AUTOSAR XML (schema 4-0-3)
package /MICROSAR/Dcm_swc
  5 x mode declaration group:
    DcmControlDtcSetting: initial-mode=ENABLEDTCSETTING, on-transition-value=2
      mode ENABLEDTCSETTING: value=0
      mode DISABLEDTCSETTING: value=1
    DcmEcuReset: initial-mode=NONE, on-transition-value=7
      7 x mode:
        NONE: value=0
        HARD: value=1
        KEYONOFF: value=2
        SOFT: value=3
        JUMPTOBOOTLOADER: value=4
        JUMPTOSYSSUPPLIERBOOTLOADER: value=5
        EXECUTE: value=6
    DcmModeRapidPowerShutDown: initial-mode=ENABLE_RAPIDPOWERSHUTDOWN, on-transition-value=2
      mode ENABLE_RAPIDPOWERSHUTDOWN: value=0
      mode DISABLE_RAPIDPOWERSHUTDOWN: value=1
    DcmDiagnosticSessionControl: initial-mode=DefaultSession, on-transition-value=255
      4 x mode:
        DefaultSession: value=1
        ProgrammingSession: value=2
        ExtendedSession: value=3
        SafetySystemSession: value=4
    DcmCommunicationControl: initial-mode=DCM_ENABLE_RX_TX_NORM, on-transition-value=12
      12 x mode:
        DCM_ENABLE_RX_TX_NORM: value=0
        DCM_ENABLE_RX_DISABLE_TX_NORM: value=1
        DCM_DISABLE_RX_ENABLE_TX_NORM: value=2
        DCM_DISABLE_RX_TX_NORMAL: value=3
        DCM_ENABLE_RX_TX_NM: value=4
        DCM_ENABLE_RX_DISABLE_TX_NM: value=5
        DCM_DISABLE_RX_ENABLE_TX_NM: value=6
        DCM_DISABLE_RX_TX_NM: value=7
        DCM_ENABLE_RX_TX_NORM_NM: value=8
        DCM_ENABLE_RX_DISABLE_TX_NORM_NM: value=9
        DCM_DISABLE_RX_ENABLE_TX_NORM_NM: value=10
        DCM_DISABLE_RX_TX_NORM_NM: value=11
  data type mapping set DcmMappingSet  # Contains mapping for ModeDeclarationGroups which are provided by Dcm.
    mode-request-type-maps:
      implementation-data-type=Dcm_ControlDtcSettingType, mode-group=DcmControlDtcSetting
      implementation-data-type=Dcm_EcuResetType, mode-group=DcmEcuReset
      implementation-data-type=Dcm_ModeRapidPowerShutDownType, mode-group=DcmModeRapidPowerShutDown
      implementation-data-type=Dcm_DiagnosticSessionControlType, mode-group=DcmDiagnosticSessionControl
      implementation-data-type=Dcm_CommunicationModeType, mode-group=DcmCommunicationControl
package /MICROSAR/Dcm_swc/DataTypes
  32 x impl type:
    Dcm_ConfirmationStatusType: compu {0=DCM_RES_POS_OK, 1=DCM_RES_POS_NOT_OK, 2=DCM_RES_NEG_OK, 3=DCM_RES_NEG_NOT_OK}, implementation-data-type=uint8
    Dcm_OpStatusType: compu {0=DCM_INITIAL, 1=DCM_PENDING, 2=DCM_CANCEL, 3=DCM_FORCE_RCRRP_OK, 64=DCM_FORCE_RCRRP_NOT_OK}, implementation-data-type=uint8
    Dcm_NegativeResponseCodeType: compu {0=DCM_E_POSITIVERESPONSE, 16=DCM_E_GENERALREJECT, 17=DCM_E_SERVICENOTSUPPORTED, 18=DCM_E_SUBFUNCTIONNOTSUPPORTED, 19=DCM_E_INCORRECTMESSAGELENGTHORINVALIDFORMAT, 20=DCM_E_RESPONSETOOLONG, 33=DCM_E_BUSYREPEATREQUEST, 34=DCM_E_CONDITIONSNOTCORRECT, 36=DCM_E_REQUESTSEQUENCEERROR, 37=DCM_E_NORESPONSEFROMSUBNETCOMPONENT, 38=DCM_E_FAILUREPREVENTSEXECUTIONOFREQUESTEDACTION, 49=DCM_E_REQUESTOUTOFRANGE, 51=DCM_E_SECURITYACCESSDENIED, 53=DCM_E_INVALIDKEY, 54=DCM_E_EXCEEDNUMBEROFATTEMPTS, 55=DCM_E_REQUIREDTIMEDELAYNOTEXPIRED, 112=DCM_E_UPLOADDOWNLOADNOTACCEPTED, 113=DCM_E_TRANSFERDATASUSPENDED, 114=DCM_E_GENERALPROGRAMMINGFAILURE, 115=DCM_E_WRONGBLOCKSEQUENCECOUNTER, 120=DCM_E_REQUESTCORRECTLYRECEIVEDRESPONSEPENDING, 126=DCM_E_SUBFUNCTIONNOTSUPPORTEDINACTIVESESSION, 127=DCM_E_SERVICENOTSUPPORTEDINACTIVESESSION, 129=DCM_E_RPMTOOHIGH, 130=DCM_E_RPMTOOLOW, 131=DCM_E_ENGINEISRUNNING, 132=DCM_E_ENGINEISNOTRUNNING, 133=DCM_E_ENGINERUNTIMETOOLOW, 134=DCM_E_TEMPERATURETOOHIGH, 135=DCM_E_TEMPERATURETOOLOW, 136=DCM_E_VEHICLESPEEDTOOHIGH, 137=DCM_E_VEHICLESPEEDTOOLOW, 138=DCM_E_THROTTLE_PEDALTOOHIGH, 139=DCM_E_THROTTLE_PEDALTOOLOW, 140=DCM_E_TRANSMISSIONRANGENOTINNEUTRAL, 141=DCM_E_TRANSMISSIONRANGENOTINGEAR, 143=DCM_E_BRAKESWITCH_NOTCLOSED, 144=DCM_E_SHIFTERLEVERNOTINPARK, 145=DCM_E_TORQUECONVERTERCLUTCHLOCKED, 146=DCM_E_VOLTAGETOOHIGH, 147=DCM_E_VOLTAGETOOLOW, 240..249=DCM_E_VMSCNC_0..DCM_E_VMSCNC_9, 250=DCM_E_VMSCNC_A, 251=DCM_E_VMSCNC_B, 252=DCM_E_VMSCNC_C, 253=DCM_E_VMSCNC_D, 254=DCM_E_VMSCNC_E}, implementation-data-type=uint8
    Dcm_ProtocolType: compu {0=DCM_OBD_ON_CAN, 1=DCM_OBD_ON_FLEXRAY, 2=DCM_OBD_ON_IP, 3=DCM_UDS_ON_CAN, 4=DCM_UDS_ON_FLEXRAY, 5=DCM_UDS_ON_IP, 12=DCM_NO_ACTIVE_PROTOCOL, 240..254=DCM_SUPPLIER_1..DCM_SUPPLIER_15}, implementation-data-type=uint8
    Dcm_SecLevelType: compu {0=DCM_SEC_LEV_LOCKED, 1=DCM_SEC_LEV_L1, 2=DCM_SEC_LEV_L2, 5=DCM_SEC_LEV_L5, 6=DCM_SEC_LEV_L6, 7=DCM_SEC_LEV_L7, 9=DCM_SEC_LEV_L9, 48=DCM_SEC_LEV_L48}, implementation-data-type=uint8
    Dcm_SesCtrlType: compu {1=DCM_DEFAULT_SESSION, 2=DCM_PROGRAMMING_SESSION, 3=DCM_EXTENDED_DIAGNOSTIC_SESSION, 4=DCM_SAFETY_SYSTEM_DIAGNOSTIC_SESSION}, implementation-data-type=uint8
    Dem_DTCFormatType: compu {0=DEM_DTC_FORMAT_OBD, 1=DEM_DTC_FORMAT_UDS}, implementation-data-type=uint8
    Dem_DTCKindType: compu {1=DEM_DTC_KIND_ALL_DTCS, 2=DEM_DTC_KIND_EMISSION_REL_DTCS}, implementation-data-type=uint8
    Dem_DTCGroupType: range raw 0..16777215, implementation-data-type=uint32
    Dem_DTCOriginType: compu {1=DEM_DTC_ORIGIN_PRIMARY_MEMORY, 2=DEM_DTC_ORIGIN_MIRROR_MEMORY, 3=DEM_DTC_ORIGIN_PERMANENT_MEMORY, 4=DEM_DTC_ORIGIN_SECONDARY_MEMORY}, implementation-data-type=uint8
    Dcm_ControlDtcSettingType: compu {0=DCM_ENUM_ENABLEDTCSETTING, 1=DCM_ENUM_DISABLEDTCSETTING}, implementation-data-type=uint8
    Dcm_EcuResetType: compu {0=DCM_ENUM_NONE, 1=DCM_ENUM_HARD, 2=DCM_ENUM_KEYONOFF, 3=DCM_ENUM_SOFT, 4=DCM_ENUM_JUMPTOBOOTLOADER, 5=DCM_ENUM_JUMPTOSYSSUPPLIERBOOTLOADER, 6=DCM_ENUM_EXECUTE}, implementation-data-type=uint8
    Dcm_ModeRapidPowerShutDownType: compu {0=DCM_ENUM_ENABLE_RAPIDPOWERSHUTDOWN, 1=DCM_ENUM_DISABLE_RAPIDPOWERSHUTDOWN}, implementation-data-type=uint8
    Dcm_DiagnosticSessionControlType: compu {1=DCM_ENUM_DefaultSession, 2=DCM_ENUM_ProgrammingSession, 3=DCM_ENUM_ExtendedSession, 4=DCM_ENUM_SafetySystemSession}, implementation-data-type=uint8
    Dcm_CommunicationModeType: compu {0=DCM_ENABLE_RX_TX_NORM, 1=DCM_ENABLE_RX_DISABLE_TX_NORM, 2=DCM_DISABLE_RX_ENABLE_TX_NORM, 3=DCM_DISABLE_RX_TX_NORMAL, 4=DCM_ENABLE_RX_TX_NM, 5=DCM_ENABLE_RX_DISABLE_TX_NM, 6=DCM_DISABLE_RX_ENABLE_TX_NM, 7=DCM_DISABLE_RX_TX_NM, 8=DCM_ENABLE_RX_TX_NORM_NM, 9=DCM_ENABLE_RX_DISABLE_TX_NORM_NM, 10=DCM_DISABLE_RX_ENABLE_TX_NORM_NM, 11=DCM_DISABLE_RX_TX_NORM_NM}, implementation-data-type=uint8
    Dcm_Data50ByteType: category=ARRAY, sw-calibration-access=READ-ONLY
      element Dcm_Data50ByteTypeElement: array-size=50, array-size-semantics=FIXED-SIZE, implementation-data-type=uint8
    Dcm_Data31ByteType: category=ARRAY, sw-calibration-access=READ-ONLY
      element Dcm_Data31ByteTypeElement: array-size=31, array-size-semantics=FIXED-SIZE, implementation-data-type=uint8
    Dcm_Data12ByteType: category=ARRAY, sw-calibration-access=READ-ONLY
      element Dcm_Data12ByteTypeElement: array-size=12, array-size-semantics=FIXED-SIZE, implementation-data-type=uint8
    Dcm_Data2ByteType: category=ARRAY, sw-calibration-access=READ-ONLY
      element Dcm_Data2ByteTypeElement: array-size=2, array-size-semantics=FIXED-SIZE, implementation-data-type=uint8
    Dcm_Data65ByteType: category=ARRAY, sw-calibration-access=READ-ONLY
      element Dcm_Data65ByteTypeElement: array-size=65, array-size-semantics=FIXED-SIZE, implementation-data-type=uint8
    Dcm_Data4ByteType: category=ARRAY, sw-calibration-access=READ-ONLY
      element Dcm_Data4ByteTypeElement: array-size=4, array-size-semantics=FIXED-SIZE, implementation-data-type=uint8
    Dcm_Data14ByteType: category=ARRAY, sw-calibration-access=READ-ONLY
      element Dcm_Data14ByteTypeElement: array-size=14, array-size-semantics=FIXED-SIZE, implementation-data-type=uint8
    Dcm_Data1ByteType: category=ARRAY, sw-calibration-access=READ-ONLY
      element Dcm_Data1ByteTypeElement: array-size=1, array-size-semantics=FIXED-SIZE, implementation-data-type=uint8
    Dcm_Data822ByteType: category=ARRAY, sw-calibration-access=READ-ONLY
      element Dcm_Data822ByteTypeElement: array-size=822, array-size-semantics=FIXED-SIZE, implementation-data-type=uint8
    Dcm_Data10ByteType: category=ARRAY, sw-calibration-access=READ-ONLY
      element Dcm_Data10ByteTypeElement: array-size=10, array-size-semantics=FIXED-SIZE, implementation-data-type=uint8
    Dcm_Data16ByteType: category=ARRAY, sw-calibration-access=READ-ONLY
      element Dcm_Data16ByteTypeElement: array-size=16, array-size-semantics=FIXED-SIZE, implementation-data-type=uint8
    Dcm_Data8ByteType: category=ARRAY, sw-calibration-access=READ-ONLY
      element Dcm_Data8ByteTypeElement: array-size=8, array-size-semantics=FIXED-SIZE, implementation-data-type=uint8
    Dcm_Data6ByteType: category=ARRAY, sw-calibration-access=READ-ONLY
      element Dcm_Data6ByteTypeElement: array-size=6, array-size-semantics=FIXED-SIZE, implementation-data-type=uint8
    Dcm_Data17ByteType: category=ARRAY, sw-calibration-access=READ-ONLY
      element Dcm_Data17ByteTypeElement: array-size=17, array-size-semantics=FIXED-SIZE, implementation-data-type=uint8
    Dcm_Data9ByteType: category=ARRAY, sw-calibration-access=READ-ONLY
      element Dcm_Data9ByteTypeElement: array-size=9, array-size-semantics=FIXED-SIZE, implementation-data-type=uint8
    Dcm_Data3ByteType: category=ARRAY, sw-calibration-access=READ-ONLY
      element Dcm_Data3ByteTypeElement: array-size=3, array-size-semantics=FIXED-SIZE, implementation-data-type=uint8
    Dcm_Data80ByteType: category=ARRAY, sw-calibration-access=READ-ONLY
      element Dcm_Data80ByteTypeElement: array-size=80, array-size-semantics=FIXED-SIZE, implementation-data-type=uint8
package /MICROSAR/Dcm_swc/Interfaces
  5 x mode switch interface, all with is-service=true, service-kind=DIAGNOSTIC-COMMUNICATION-MANAGER:
    DcmControlDtcSetting
      mode group DcmControlDtcSetting: type=DcmControlDtcSetting
    DcmEcuReset
      mode group DcmEcuReset: type=DcmEcuReset
    DcmModeRapidPowerShutDown
      mode group DcmModeRapidPowerShutDown: type=DcmModeRapidPowerShutDown
    DcmDiagnosticSessionControl
      mode group DcmDiagnosticSessionControl: type=DcmDiagnosticSessionControl
    DcmCommunicationControl_ComMConf_ComMChannel_CAN_5_Cluster_def1eb88
      mode group DcmCommunicationControl_ComMConf_ComMChannel_CAN_5_Cluster_def1eb88: type=DcmCommunicationControl
  117 x client server interface, all with is-service=true, service-kind=DIAGNOSTIC-COMMUNICATION-MANAGER:
    DCMServices
      4 x operation, all with possible-error=DCMServices/E_NOT_OK:
        GetActiveProtocol
          arg ActiveProtocol: type=Dcm_ProtocolType, direction=OUT
        GetSesCtrlType
          arg SesCtrlType: type=Dcm_SesCtrlType, direction=OUT
        ResetToDefaultSession
        GetSecurityLevel
          arg SecLevel: type=Dcm_SecLevelType, direction=OUT
      error E_NOT_OK: error-code=1
    ServiceRequestNotification
      operation Indication: possible-error=[ServiceRequestNotification/E_NOT_OK, E_REQUEST_NOT_ACCEPTED]
        6 x arg:
          SID: type=uint8, direction=IN
          RequestData: type=Dcm_Data50ByteType, direction=IN
          DataSize: type=uint16, direction=IN
          ReqType: type=uint8, direction=IN
          SourceAddress: type=uint16, direction=IN
          ErrorCode: type=Dcm_NegativeResponseCodeType, direction=OUT
      operation Confirmation: possible-error=ServiceRequestNotification/E_NOT_OK
        4 x arg, all with direction=IN:
          SID: type=uint8
          ReqType: type=uint8
          SourceAddress: type=uint16
          ConfirmationStatus: type=Dcm_ConfirmationStatusType
      error E_NOT_OK: error-code=1
      error E_REQUEST_NOT_ACCEPTED: error-code=8
    SecurityAccess_Level_1
      operation GetSeed: possible-error=[SecurityAccess_Level_1/E_NOT_OK, SecurityAccess_Level_1/E_PENDING]
        arg OpStatus: type=Dcm_OpStatusType, direction=IN
        arg Seed: type=Dcm_Data31ByteType, direction=OUT
        arg ErrorCode: type=Dcm_NegativeResponseCodeType, direction=OUT
      operation CompareKey: possible-error=[SecurityAccess_Level_1/E_NOT_OK, SecurityAccess_Level_1/E_PENDING, SecurityAccess_Level_1/E_COMPARE_KEY_FAILED]
        arg Key: type=Dcm_Data12ByteType, direction=IN
        arg OpStatus: type=Dcm_OpStatusType, direction=IN
      error E_NOT_OK: error-code=1
      error E_PENDING: error-code=10
      error E_COMPARE_KEY_FAILED: error-code=11
    SecurityAccess_Level_3
      operation GetSeed: possible-error=[SecurityAccess_Level_3/E_NOT_OK, SecurityAccess_Level_3/E_PENDING]
        arg OpStatus: type=Dcm_OpStatusType, direction=IN
        arg Seed: type=Dcm_Data31ByteType, direction=OUT
        arg ErrorCode: type=Dcm_NegativeResponseCodeType, direction=OUT
      operation CompareKey: possible-error=[SecurityAccess_Level_3/E_NOT_OK, SecurityAccess_Level_3/E_PENDING, SecurityAccess_Level_3/E_COMPARE_KEY_FAILED]
        arg Key: type=Dcm_Data12ByteType, direction=IN
        arg OpStatus: type=Dcm_OpStatusType, direction=IN
      error E_NOT_OK: error-code=1
      error E_PENDING: error-code=10
      error E_COMPARE_KEY_FAILED: error-code=11
    SecurityAccess_Level_9
      operation GetSeed: possible-error=[SecurityAccess_Level_9/E_NOT_OK, SecurityAccess_Level_9/E_PENDING]
        arg OpStatus: type=Dcm_OpStatusType, direction=IN
        arg Seed: type=Dcm_Data31ByteType, direction=OUT
        arg ErrorCode: type=Dcm_NegativeResponseCodeType, direction=OUT
      operation CompareKey: possible-error=[SecurityAccess_Level_9/E_NOT_OK, SecurityAccess_Level_9/E_PENDING, SecurityAccess_Level_9/E_COMPARE_KEY_FAILED]
        arg Key: type=Dcm_Data12ByteType, direction=IN
        arg OpStatus: type=Dcm_OpStatusType, direction=IN
      error E_NOT_OK: error-code=1
      error E_PENDING: error-code=10
      error E_COMPARE_KEY_FAILED: error-code=11
    SecurityAccess_Level_B
      operation GetSeed: possible-error=[SecurityAccess_Level_B/E_NOT_OK, SecurityAccess_Level_B/E_PENDING]
        arg OpStatus: type=Dcm_OpStatusType, direction=IN
        arg Seed: type=Dcm_Data31ByteType, direction=OUT
        arg ErrorCode: type=Dcm_NegativeResponseCodeType, direction=OUT
      operation CompareKey: possible-error=[SecurityAccess_Level_B/E_NOT_OK, SecurityAccess_Level_B/E_PENDING, SecurityAccess_Level_B/E_COMPARE_KEY_FAILED]
        arg Key: type=Dcm_Data12ByteType, direction=IN
        arg OpStatus: type=Dcm_OpStatusType, direction=IN
      error E_NOT_OK: error-code=1
      error E_PENDING: error-code=10
      error E_COMPARE_KEY_FAILED: error-code=11
    SecurityAccess_Level_D
      operation GetSeed: possible-error=[SecurityAccess_Level_D/E_NOT_OK, SecurityAccess_Level_D/E_PENDING]
        arg OpStatus: type=Dcm_OpStatusType, direction=IN
        arg Seed: type=Dcm_Data31ByteType, direction=OUT
        arg ErrorCode: type=Dcm_NegativeResponseCodeType, direction=OUT
      operation CompareKey: possible-error=[SecurityAccess_Level_D/E_NOT_OK, SecurityAccess_Level_D/E_PENDING, SecurityAccess_Level_D/E_COMPARE_KEY_FAILED]
        arg Key: type=Dcm_Data12ByteType, direction=IN
        arg OpStatus: type=Dcm_OpStatusType, direction=IN
      error E_NOT_OK: error-code=1
      error E_PENDING: error-code=10
      error E_COMPARE_KEY_FAILED: error-code=11
    SecurityAccess_Level_11
      operation GetSeed: possible-error=[SecurityAccess_Level_11/E_NOT_OK, SecurityAccess_Level_11/E_PENDING]
        arg OpStatus: type=Dcm_OpStatusType, direction=IN
        arg Seed: type=Dcm_Data31ByteType, direction=OUT
        arg ErrorCode: type=Dcm_NegativeResponseCodeType, direction=OUT
      operation CompareKey: possible-error=[SecurityAccess_Level_11/E_NOT_OK, SecurityAccess_Level_11/E_PENDING, SecurityAccess_Level_11/E_COMPARE_KEY_FAILED]
        arg Key: type=Dcm_Data12ByteType, direction=IN
        arg OpStatus: type=Dcm_OpStatusType, direction=IN
      error E_NOT_OK: error-code=1
      error E_PENDING: error-code=10
      error E_COMPARE_KEY_FAILED: error-code=11
    SecurityAccess_Level_5F
      operation GetSeed: possible-error=[SecurityAccess_Level_5F/E_NOT_OK, SecurityAccess_Level_5F/E_PENDING]
        arg OpStatus: type=Dcm_OpStatusType, direction=IN
        arg Seed: type=Dcm_Data2ByteType, direction=OUT
        arg ErrorCode: type=Dcm_NegativeResponseCodeType, direction=OUT
      operation CompareKey: possible-error=[SecurityAccess_Level_5F/E_NOT_OK, SecurityAccess_Level_5F/E_PENDING, SecurityAccess_Level_5F/E_COMPARE_KEY_FAILED]
        arg Key: type=Dcm_Data2ByteType, direction=IN
        arg OpStatus: type=Dcm_OpStatusType, direction=IN
      error E_NOT_OK: error-code=1
      error E_PENDING: error-code=10
      error E_COMPARE_KEY_FAILED: error-code=11
    RoutineServices_RID_0200_ProvisionSecurityPeripheralGeneralKeys
      operation Start: possible-error=[RoutineServices_RID_0200_ProvisionSecurityPeripheralGeneralKeys/E_NOT_OK, RoutineServices_RID_0200_ProvisionSecurityPeripheralGeneralKeys/E_PENDING, RoutineServices_RID_0200_ProvisionSecurityPeripheralGeneralKeys/E_FORCE_RCRRP]
        4 x arg:
          ControlOptionStart: type=Dcm_Data65ByteType, direction=IN
          OpStatus: type=Dcm_OpStatusType, direction=IN
          RoutineStatusStart: type=uint8, direction=OUT
          ErrorCode: type=Dcm_NegativeResponseCodeType, direction=OUT
      error E_NOT_OK: error-code=1
      error E_PENDING: error-code=10
      error E_FORCE_RCRRP: error-code=12
    RoutineServices_RID_0204_ECUKeyProvisionData
      operation Start: possible-error=[RoutineServices_RID_0204_ECUKeyProvisionData/E_NOT_OK, RoutineServices_RID_0204_ECUKeyProvisionData/E_PENDING, RoutineServices_RID_0204_ECUKeyProvisionData/E_FORCE_RCRRP]
        arg OpStatus: type=Dcm_OpStatusType, direction=IN
        arg RoutineStatusStart: type=uint8, direction=OUT
        arg ErrorCode: type=Dcm_NegativeResponseCodeType, direction=OUT
      error E_NOT_OK: error-code=1
      error E_PENDING: error-code=10
      error E_FORCE_RCRRP: error-code=12
    RoutineServices_RID_0205_SecuredECUKeyProvisionData
      operation Start: possible-error=[RoutineServices_RID_0205_SecuredECUKeyProvisionData/E_NOT_OK, RoutineServices_RID_0205_SecuredECUKeyProvisionData/E_PENDING, RoutineServices_RID_0205_SecuredECUKeyProvisionData/E_FORCE_RCRRP]
        arg OpStatus: type=Dcm_OpStatusType, direction=IN
        arg RoutineStatusStart: type=uint8, direction=OUT
        arg ErrorCode: type=Dcm_NegativeResponseCodeType, direction=OUT
      error E_NOT_OK: error-code=1
      error E_PENDING: error-code=10
      error E_FORCE_RCRRP: error-code=12
    RoutineServices_RID_0209_UpdateProgrammedStateIndicatorForPartition
      operation Start: possible-error=[RoutineServices_RID_0209_UpdateProgrammedStateIndicatorForPartition/E_NOT_OK, RoutineServices_RID_0209_UpdateProgrammedStateIndicatorForPartition/E_PENDING, RoutineServices_RID_0209_UpdateProgrammedStateIndicatorForPartition/E_FORCE_RCRRP]
        arg ControlOptionStart: type=uint8, direction=IN
        arg OpStatus: type=Dcm_OpStatusType, direction=IN
        arg ErrorCode: type=Dcm_NegativeResponseCodeType, direction=OUT
      error E_NOT_OK: error-code=1
      error E_PENDING: error-code=10
      error E_FORCE_RCRRP: error-code=12
    RoutineServices_RID_021E_DiagInitiateExtendedReflash
      operation Start: possible-error=[RoutineServices_RID_021E_DiagInitiateExtendedReflash/E_NOT_OK, RoutineServices_RID_021E_DiagInitiateExtendedReflash/E_PENDING, RoutineServices_RID_021E_DiagInitiateExtendedReflash/E_FORCE_RCRRP]
        arg OpStatus: type=Dcm_OpStatusType, direction=IN
        arg RoutineStatusStart: type=uint8, direction=OUT
        arg ErrorCode: type=Dcm_NegativeResponseCodeType, direction=OUT
      error E_NOT_OK: error-code=1
      error E_PENDING: error-code=10
      error E_FORCE_RCRRP: error-code=12
    RoutineServices_RID_FF00_EraseMemory
      operation Start: possible-error=[RoutineServices_RID_FF00_EraseMemory/E_NOT_OK, RoutineServices_RID_FF00_EraseMemory/E_PENDING, RoutineServices_RID_FF00_EraseMemory/E_FORCE_RCRRP]
        arg ControlOptionStart: type=uint8, direction=IN
        arg OpStatus: type=Dcm_OpStatusType, direction=IN
        arg ErrorCode: type=Dcm_NegativeResponseCodeType, direction=OUT
      error E_NOT_OK: error-code=1
      error E_PENDING: error-code=10
      error E_FORCE_RCRRP: error-code=12
    DataServices_DID_F0F2_BootInitializationStatus_BootInitializationStatus_0_0
      operation ReadData: possible-error=[DataServices_DID_F0F2_BootInitializationStatus_BootInitializationStatus_0_0/E_NOT_OK, DataServices_DID_F0F2_BootInitializationStatus_BootInitializationStatus_0_0/E_PENDING]
        arg OpStatus: type=Dcm_OpStatusType, direction=IN
        arg Data: type=Dcm_Data2ByteType, direction=OUT
      error E_NOT_OK: error-code=1
      error E_PENDING: error-code=10
    DataServices_DID_F1DA_GMSoftwareModuleIdentifierAlphaCode_10_GMSoftwareModuleIdentifierAlphaCode_10_0_0
      operation ReadData: possible-error=[DataServices_DID_F1DA_GMSoftwareModuleIdentifierAlphaCode_10_GMSoftwareModuleIdentifierAlphaCode_10_0_0/E_NOT_OK, DataServices_DID_F1DA_GMSoftwareModuleIdentifierAlphaCode_10_GMSoftwareModuleIdentifierAlphaCode_10_0_0/E_PENDING]
        arg OpStatus: type=Dcm_OpStatusType, direction=IN
        arg Data: type=Dcm_Data2ByteType, direction=OUT
      error E_NOT_OK: error-code=1
      error E_PENDING: error-code=10
    DataServices_DID_F112_GMSoftwareModuleIdentifier_20_GMSoftwareModuleIdentifier_20_0_0
      operation ReadData: possible-error=[DataServices_DID_F112_GMSoftwareModuleIdentifier_20_GMSoftwareModuleIdentifier_20_0_0/E_NOT_OK, DataServices_DID_F112_GMSoftwareModuleIdentifier_20_GMSoftwareModuleIdentifier_20_0_0/E_PENDING]
        arg OpStatus: type=Dcm_OpStatusType, direction=IN
        arg Data: type=Dcm_Data4ByteType, direction=OUT
      error E_NOT_OK: error-code=1
      error E_PENDING: error-code=10
    DataServices_DID_F11C_GMSoftwareModuleIdentifier_25_GMSoftwareModuleIdentifier_25_0_0
      operation ReadData: possible-error=[DataServices_DID_F11C_GMSoftwareModuleIdentifier_25_GMSoftwareModuleIdentifier_25_0_0/E_NOT_OK, DataServices_DID_F11C_GMSoftwareModuleIdentifier_25_GMSoftwareModuleIdentifier_25_0_0/E_PENDING]
        arg OpStatus: type=Dcm_OpStatusType, direction=IN
        arg Data: type=Dcm_Data4ByteType, direction=OUT
      error E_NOT_OK: error-code=1
      error E_PENDING: error-code=10
    DataServices_DID_F10F_GMSoftwareModuleIdentifierAlphaCode_18_GMSoftwareModuleIdentifierAlphaCode_18_0_0
      operation ReadData: possible-error=[DataServices_DID_F10F_GMSoftwareModuleIdentifierAlphaCode_18_GMSoftwareModuleIdentifierAlphaCode_18_0_0/E_NOT_OK, DataServices_DID_F10F_GMSoftwareModuleIdentifierAlphaCode_18_GMSoftwareModuleIdentifierAlphaCode_18_0_0/E_PENDING]
        arg OpStatus: type=Dcm_OpStatusType, direction=IN
        arg Data: type=Dcm_Data2ByteType, direction=OUT
      error E_NOT_OK: error-code=1
      error E_PENDING: error-code=10
    DataServices_DID_F100_GMSoftwareModuleIdentifier_11_GMSoftwareModuleIdentifier_11_0_0
      operation ReadData: possible-error=[DataServices_DID_F100_GMSoftwareModuleIdentifier_11_GMSoftwareModuleIdentifier_11_0_0/E_NOT_OK, DataServices_DID_F100_GMSoftwareModuleIdentifier_11_GMSoftwareModuleIdentifier_11_0_0/E_PENDING]
        arg OpStatus: type=Dcm_OpStatusType, direction=IN
        arg Data: type=Dcm_Data4ByteType, direction=OUT
      error E_NOT_OK: error-code=1
      error E_PENDING: error-code=10
    DataServices_DID_F1CC_GMBaseModelPartNumber_GMBaseModelPartNumber_0_0
      operation ReadData: possible-error=[DataServices_DID_F1CC_GMBaseModelPartNumber_GMBaseModelPartNumber_0_0/E_NOT_OK, DataServices_DID_F1CC_GMBaseModelPartNumber_GMBaseModelPartNumber_0_0/E_PENDING]
        arg OpStatus: type=Dcm_OpStatusType, direction=IN
        arg Data: type=Dcm_Data4ByteType, direction=OUT
      error E_NOT_OK: error-code=1
      error E_PENDING: error-code=10
    DataServices_DID_F09B_GMXmlConfigurationCompatibilityIdentifier_DiagXmlConfigurationCompatibilityIdentifier_0_0
      operation ReadData: possible-error=[DataServices_DID_F09B_GMXmlConfigurationCompatibilityIdentifier_DiagXmlConfigurationCompatibilityIdentifier_0_0/E_NOT_OK, DataServices_DID_F09B_GMXmlConfigurationCompatibilityIdentifier_DiagXmlConfigurationCompatibilityIdentifier_0_0/E_PENDING]
        arg OpStatus: type=Dcm_OpStatusType, direction=IN
        arg Data: type=Dcm_Data2ByteType, direction=OUT
      error E_NOT_OK: error-code=1
      error E_PENDING: error-code=10
    DataServices_DID_F102_GMSoftwareModuleIdentifier_12_GMSoftwareModuleIdentifier_12_0_0
      operation ReadData: possible-error=[DataServices_DID_F102_GMSoftwareModuleIdentifier_12_GMSoftwareModuleIdentifier_12_0_0/E_NOT_OK, DataServices_DID_F102_GMSoftwareModuleIdentifier_12_GMSoftwareModuleIdentifier_12_0_0/E_PENDING]
        arg OpStatus: type=Dcm_OpStatusType, direction=IN
        arg Data: type=Dcm_Data4ByteType, direction=OUT
      error E_NOT_OK: error-code=1
      error E_PENDING: error-code=10
    DataServices_DID_F1C3_GMSoftwareModuleIdentifier_03_GMSoftwareModuleIdentifier_03_0_0
      operation ReadData: possible-error=[DataServices_DID_F1C3_GMSoftwareModuleIdentifier_03_GMSoftwareModuleIdentifier_03_0_0/E_NOT_OK, DataServices_DID_F1C3_GMSoftwareModuleIdentifier_03_GMSoftwareModuleIdentifier_03_0_0/E_PENDING]
        arg OpStatus: type=Dcm_OpStatusType, direction=IN
        arg Data: type=Dcm_Data4ByteType, direction=OUT
      error E_NOT_OK: error-code=1
      error E_PENDING: error-code=10
    DataServices_DID_F0AB_CompressedVehiclePartitioningAndProductStructure_DiagCompressedVehiclePartitioningAndProductStructure_0_0
      operation ReadData: possible-error=[DataServices_DID_F0AB_CompressedVehiclePartitioningAndProductStructure_DiagCompressedVehiclePartitioningAndProductStructure_0_0/E_NOT_OK, DataServices_DID_F0AB_CompressedVehiclePartitioningAndProductStructure_DiagCompressedVehiclePartitioningAndProductStructure_0_0/E_PENDING]
        arg OpStatus: type=Dcm_OpStatusType, direction=IN
        arg Data: type=Dcm_Data14ByteType, direction=OUT
      error E_NOT_OK: error-code=1
      error E_PENDING: error-code=10
    DataServices_DID_F10A_GMSoftwareModuleIdentifier_16_GMSoftwareModuleIdentifier_16_0_0
      operation ReadData: possible-error=[DataServices_DID_F10A_GMSoftwareModuleIdentifier_16_GMSoftwareModuleIdentifier_16_0_0/E_NOT_OK, DataServices_DID_F10A_GMSoftwareModuleIdentifier_16_GMSoftwareModuleIdentifier_16_0_0/E_PENDING]
        arg OpStatus: type=Dcm_OpStatusType, direction=IN
        arg Data: type=Dcm_Data4ByteType, direction=OUT
      error E_NOT_OK: error-code=1
      error E_PENDING: error-code=10
    DataServices_DID_F116_GMSoftwareModuleIdentifier_22_GMSoftwareModuleIdentifier_22_0_0
      operation ReadData: possible-error=[DataServices_DID_F116_GMSoftwareModuleIdentifier_22_GMSoftwareModuleIdentifier_22_0_0/E_NOT_OK, DataServices_DID_F116_GMSoftwareModuleIdentifier_22_GMSoftwareModuleIdentifier_22_0_0/E_PENDING]
        arg OpStatus: type=Dcm_OpStatusType, direction=IN
        arg Data: type=Dcm_Data4ByteType, direction=OUT
      error E_NOT_OK: error-code=1
      error E_PENDING: error-code=10
    DataServices_DID_F1C1_GMSoftwareModuleIdentifier_01_GMSoftwareModuleIdentifier_01_0_0
      operation ReadData: possible-error=[DataServices_DID_F1C1_GMSoftwareModuleIdentifier_01_GMSoftwareModuleIdentifier_01_0_0/E_NOT_OK, DataServices_DID_F1C1_GMSoftwareModuleIdentifier_01_GMSoftwareModuleIdentifier_01_0_0/E_PENDING]
        arg OpStatus: type=Dcm_OpStatusType, direction=IN
        arg Data: type=Dcm_Data4ByteType, direction=OUT
      error E_NOT_OK: error-code=1
      error E_PENDING: error-code=10
    DataServices_DID_F1D4_GMSoftwareModuleIdentifierAlphaCode_04_GMSoftwareModuleIdentifierAlphaCode_04_0_0
      operation ReadData: possible-error=[DataServices_DID_F1D4_GMSoftwareModuleIdentifierAlphaCode_04_GMSoftwareModuleIdentifierAlphaCode_04_0_0/E_NOT_OK, DataServices_DID_F1D4_GMSoftwareModuleIdentifierAlphaCode_04_GMSoftwareModuleIdentifierAlphaCode_04_0_0/E_PENDING]
        arg OpStatus: type=Dcm_OpStatusType, direction=IN
        arg Data: type=Dcm_Data2ByteType, direction=OUT
      error E_NOT_OK: error-code=1
      error E_PENDING: error-code=10
    DataServices_DID_F1D6_GMSoftwareModuleIdentifierAlphaCode_06_GMSoftwareModuleIdentifierAlphaCode_06_0_0
      operation ReadData: possible-error=[DataServices_DID_F1D6_GMSoftwareModuleIdentifierAlphaCode_06_GMSoftwareModuleIdentifierAlphaCode_06_0_0/E_NOT_OK, DataServices_DID_F1D6_GMSoftwareModuleIdentifierAlphaCode_06_GMSoftwareModuleIdentifierAlphaCode_06_0_0/E_PENDING]
        arg OpStatus: type=Dcm_OpStatusType, direction=IN
        arg Data: type=Dcm_Data2ByteType, direction=OUT
      error E_NOT_OK: error-code=1
      error E_PENDING: error-code=10
    DataServices_DID_F122_GMSoftwareModuleIdentifier_28_GMSoftwareModuleIdentifier_28_0_0
      operation ReadData: possible-error=[DataServices_DID_F122_GMSoftwareModuleIdentifier_28_GMSoftwareModuleIdentifier_28_0_0/E_NOT_OK, DataServices_DID_F122_GMSoftwareModuleIdentifier_28_GMSoftwareModuleIdentifier_28_0_0/E_PENDING]
        arg OpStatus: type=Dcm_OpStatusType, direction=IN
        arg Data: type=Dcm_Data4ByteType, direction=OUT
      error E_NOT_OK: error-code=1
      error E_PENDING: error-code=10
    DataServices_DID_F104_GMSoftwareModuleIdentifier_13_GMSoftwareModuleIdentifier_13_0_0
      operation ReadData: possible-error=[DataServices_DID_F104_GMSoftwareModuleIdentifier_13_GMSoftwareModuleIdentifier_13_0_0/E_NOT_OK, DataServices_DID_F104_GMSoftwareModuleIdentifier_13_GMSoftwareModuleIdentifier_13_0_0/E_PENDING]
        arg OpStatus: type=Dcm_OpStatusType, direction=IN
        arg Data: type=Dcm_Data4ByteType, direction=OUT
      error E_NOT_OK: error-code=1
      error E_PENDING: error-code=10
    DataServices_DID_F10C_GMSoftwareModuleIdentifier_17_GMSoftwareModuleIdentifier_17_0_0
      operation ReadData: possible-error=[DataServices_DID_F10C_GMSoftwareModuleIdentifier_17_GMSoftwareModuleIdentifier_17_0_0/E_NOT_OK, DataServices_DID_F10C_GMSoftwareModuleIdentifier_17_GMSoftwareModuleIdentifier_17_0_0/E_PENDING]
        arg OpStatus: type=Dcm_OpStatusType, direction=IN
        arg Data: type=Dcm_Data4ByteType, direction=OUT
      error E_NOT_OK: error-code=1
      error E_PENDING: error-code=10
    DataServices_DID_F1A0_ManufacturersEnableCounter_ManufacturersEnableCounter_0_0
      operation ReadData: possible-error=[DataServices_DID_F1A0_ManufacturersEnableCounter_ManufacturersEnableCounter_0_0/E_NOT_OK, DataServices_DID_F1A0_ManufacturersEnableCounter_ManufacturersEnableCounter_0_0/E_PENDING]
        arg OpStatus: type=Dcm_OpStatusType, direction=IN
        arg Data: type=Dcm_Data1ByteType, direction=OUT
      operation WriteData: possible-error=[DataServices_DID_F1A0_ManufacturersEnableCounter_ManufacturersEnableCounter_0_0/E_NOT_OK, DataServices_DID_F1A0_ManufacturersEnableCounter_ManufacturersEnableCounter_0_0/E_PENDING]
        arg Data: type=Dcm_Data1ByteType, direction=IN
        arg OpStatus: type=Dcm_OpStatusType, direction=IN
        arg ErrorCode: type=Dcm_NegativeResponseCodeType, direction=OUT
      error E_NOT_OK: error-code=1
      error E_PENDING: error-code=10
    DataServices_DID_F103_GMSoftwareModuleIdentifierAlphaCode_12_GMSoftwareModuleIdentifierAlphaCode_12_0_0
      operation ReadData: possible-error=[DataServices_DID_F103_GMSoftwareModuleIdentifierAlphaCode_12_GMSoftwareModuleIdentifierAlphaCode_12_0_0/E_NOT_OK, DataServices_DID_F103_GMSoftwareModuleIdentifierAlphaCode_12_GMSoftwareModuleIdentifierAlphaCode_12_0_0/E_PENDING]
        arg OpStatus: type=Dcm_OpStatusType, direction=IN
        arg Data: type=Dcm_Data2ByteType, direction=OUT
      error E_NOT_OK: error-code=1
      error E_PENDING: error-code=10
    DataServices_DID_F0F0_ProgrammedStateIndicator_ProgrammedStateIndicator_0_0
      operation ReadData: possible-error=[DataServices_DID_F0F0_ProgrammedStateIndicator_ProgrammedStateIndicator_0_0/E_NOT_OK, DataServices_DID_F0F0_ProgrammedStateIndicator_ProgrammedStateIndicator_0_0/E_PENDING]
        arg OpStatus: type=Dcm_OpStatusType, direction=IN
        arg Data: type=Dcm_Data1ByteType, direction=OUT
      operation ReadDataLength: possible-error=[DataServices_DID_F0F0_ProgrammedStateIndicator_ProgrammedStateIndicator_0_0/E_NOT_OK, DataServices_DID_F0F0_ProgrammedStateIndicator_ProgrammedStateIndicator_0_0/E_PENDING]
        arg OpStatus: type=Dcm_OpStatusType, direction=IN
        arg DataLength: type=uint16, direction=OUT
      error E_NOT_OK: error-code=1
      error E_PENDING: error-code=10
    DataServices_DID_F120_GMSoftwareModuleIdentifier_27_GMSoftwareModuleIdentifier_27_0_0
      operation ReadData: possible-error=[DataServices_DID_F120_GMSoftwareModuleIdentifier_27_GMSoftwareModuleIdentifier_27_0_0/E_NOT_OK, DataServices_DID_F120_GMSoftwareModuleIdentifier_27_GMSoftwareModuleIdentifier_27_0_0/E_PENDING]
        arg OpStatus: type=Dcm_OpStatusType, direction=IN
        arg Data: type=Dcm_Data4ByteType, direction=OUT
      error E_NOT_OK: error-code=1
      error E_PENDING: error-code=10
    DataServices_DID_F0F1_ProgramingErrorCode_ProgramingErrorCode_0_0
      operation ReadData: possible-error=[DataServices_DID_F0F1_ProgramingErrorCode_ProgramingErrorCode_0_0/E_NOT_OK, DataServices_DID_F0F1_ProgramingErrorCode_ProgramingErrorCode_0_0/E_PENDING]
        arg OpStatus: type=Dcm_OpStatusType, direction=IN
        arg Data: type=Dcm_Data2ByteType, direction=OUT
      error E_NOT_OK: error-code=1
      error E_PENDING: error-code=10
    DataServices_DID_F117_GMSoftwareModuleIdentifierAlphaCode_22_GMSoftwareModuleIdentifierAlphaCode_22_0_0
      operation ReadData: possible-error=[DataServices_DID_F117_GMSoftwareModuleIdentifierAlphaCode_22_GMSoftwareModuleIdentifierAlphaCode_22_0_0/E_NOT_OK, DataServices_DID_F117_GMSoftwareModuleIdentifierAlphaCode_22_GMSoftwareModuleIdentifierAlphaCode_22_0_0/E_PENDING]
        arg OpStatus: type=Dcm_OpStatusType, direction=IN
        arg Data: type=Dcm_Data2ByteType, direction=OUT
      error E_NOT_OK: error-code=1
      error E_PENDING: error-code=10
    DataServices_DID_F114_GMSoftwareModuleIdentifier_21_GMSoftwareModuleIdentifier_21_0_0
      operation ReadData: possible-error=[DataServices_DID_F114_GMSoftwareModuleIdentifier_21_GMSoftwareModuleIdentifier_21_0_0/E_NOT_OK, DataServices_DID_F114_GMSoftwareModuleIdentifier_21_GMSoftwareModuleIdentifier_21_0_0/E_PENDING]
        arg OpStatus: type=Dcm_OpStatusType, direction=IN
        arg Data: type=Dcm_Data4ByteType, direction=OUT
      error E_NOT_OK: error-code=1
      error E_PENDING: error-code=10
    DataServices_DID_F1AA_GMXMLProgrammingDate_DiagXMLProgrammingDate_0_0
      operation ReadData: possible-error=[DataServices_DID_F1AA_GMXMLProgrammingDate_DiagXMLProgrammingDate_0_0/E_NOT_OK, DataServices_DID_F1AA_GMXMLProgrammingDate_DiagXMLProgrammingDate_0_0/E_PENDING]
        arg OpStatus: type=Dcm_OpStatusType, direction=IN
        arg Data: type=Dcm_Data4ByteType, direction=OUT
      operation WriteData: possible-error=[DataServices_DID_F1AA_GMXMLProgrammingDate_DiagXMLProgrammingDate_0_0/E_NOT_OK, DataServices_DID_F1AA_GMXMLProgrammingDate_DiagXMLProgrammingDate_0_0/E_PENDING]
        arg Data: type=Dcm_Data4ByteType, direction=IN
        arg OpStatus: type=Dcm_OpStatusType, direction=IN
        arg ErrorCode: type=Dcm_NegativeResponseCodeType, direction=OUT
      error E_NOT_OK: error-code=1
      error E_PENDING: error-code=10
    DataServices_DID_F10E_GMSoftwareModuleIdentifier_18_GMSoftwareModuleIdentifier_18_0_0
      operation ReadData: possible-error=[DataServices_DID_F10E_GMSoftwareModuleIdentifier_18_GMSoftwareModuleIdentifier_18_0_0/E_NOT_OK, DataServices_DID_F10E_GMSoftwareModuleIdentifier_18_GMSoftwareModuleIdentifier_18_0_0/E_PENDING]
        arg OpStatus: type=Dcm_OpStatusType, direction=IN
        arg Data: type=Dcm_Data4ByteType, direction=OUT
      error E_NOT_OK: error-code=1
      error E_PENDING: error-code=10
    DataServices_DID_F1C6_GMSoftwareModuleIdentifier_06_GMSoftwareModuleIdentifier_06_0_0
      operation ReadData: possible-error=[DataServices_DID_F1C6_GMSoftwareModuleIdentifier_06_GMSoftwareModuleIdentifier_06_0_0/E_NOT_OK, DataServices_DID_F1C6_GMSoftwareModuleIdentifier_06_GMSoftwareModuleIdentifier_06_0_0/E_PENDING]
        arg OpStatus: type=Dcm_OpStatusType, direction=IN
        arg Data: type=Dcm_Data4ByteType, direction=OUT
      error E_NOT_OK: error-code=1
      error E_PENDING: error-code=10
    DataServices_DID_F105_GMSoftwareModuleIdentifierAlphaCode_13_GMSoftwareModuleIdentifierAlphaCode_13_0_0
      operation ReadData: possible-error=[DataServices_DID_F105_GMSoftwareModuleIdentifierAlphaCode_13_GMSoftwareModuleIdentifierAlphaCode_13_0_0/E_NOT_OK, DataServices_DID_F105_GMSoftwareModuleIdentifierAlphaCode_13_GMSoftwareModuleIdentifierAlphaCode_13_0_0/E_PENDING]
        arg OpStatus: type=Dcm_OpStatusType, direction=IN
        arg Data: type=Dcm_Data2ByteType, direction=OUT
      error E_NOT_OK: error-code=1
      error E_PENDING: error-code=10
    DataServices_DID_F09D_GMXmlDataFileAlphaCode_DiagGMXmlDataFileAlphaCode_0_0
      operation ReadData: possible-error=[DataServices_DID_F09D_GMXmlDataFileAlphaCode_DiagGMXmlDataFileAlphaCode_0_0/E_NOT_OK, DataServices_DID_F09D_GMXmlDataFileAlphaCode_DiagGMXmlDataFileAlphaCode_0_0/E_PENDING]
        arg OpStatus: type=Dcm_OpStatusType, direction=IN
        arg Data: type=Dcm_Data2ByteType, direction=OUT
      operation WriteData: possible-error=[DataServices_DID_F09D_GMXmlDataFileAlphaCode_DiagGMXmlDataFileAlphaCode_0_0/E_NOT_OK, DataServices_DID_F09D_GMXmlDataFileAlphaCode_DiagGMXmlDataFileAlphaCode_0_0/E_PENDING]
        arg Data: type=Dcm_Data2ByteType, direction=IN
        arg OpStatus: type=Dcm_OpStatusType, direction=IN
        arg ErrorCode: type=Dcm_NegativeResponseCodeType, direction=OUT
      error E_NOT_OK: error-code=1
      error E_PENDING: error-code=10
    DataServices_DID_F1C0_GMBootSoftwarePartNumber_GMBootSoftwarePartNumber_0_0
      operation ReadData: possible-error=[DataServices_DID_F1C0_GMBootSoftwarePartNumber_GMBootSoftwarePartNumber_0_0/E_NOT_OK, DataServices_DID_F1C0_GMBootSoftwarePartNumber_GMBootSoftwarePartNumber_0_0/E_PENDING]
        arg OpStatus: type=Dcm_OpStatusType, direction=IN
        arg Data: type=Dcm_Data4ByteType, direction=OUT
      error E_NOT_OK: error-code=1
      error E_PENDING: error-code=10
    DataServices_DID_F107_GMSoftwareModuleIdentifierAlphaCode_14_GMSoftwareModuleIdentifierAlphaCode_14_0_0
      operation ReadData: possible-error=[DataServices_DID_F107_GMSoftwareModuleIdentifierAlphaCode_14_GMSoftwareModuleIdentifierAlphaCode_14_0_0/E_NOT_OK, DataServices_DID_F107_GMSoftwareModuleIdentifierAlphaCode_14_GMSoftwareModuleIdentifierAlphaCode_14_0_0/E_PENDING]
        arg OpStatus: type=Dcm_OpStatusType, direction=IN
        arg Data: type=Dcm_Data2ByteType, direction=OUT
      error E_NOT_OK: error-code=1
      error E_PENDING: error-code=10
    DataServices_DID_F199_ProgrammingDate_DiagProgrammingDate_0_0
      operation ReadData: possible-error=[DataServices_DID_F199_ProgrammingDate_DiagProgrammingDate_0_0/E_NOT_OK, DataServices_DID_F199_ProgrammingDate_DiagProgrammingDate_0_0/E_PENDING]
        arg OpStatus: type=Dcm_OpStatusType, direction=IN
        arg Data: type=Dcm_Data4ByteType, direction=OUT
      operation WriteData: possible-error=[DataServices_DID_F199_ProgrammingDate_DiagProgrammingDate_0_0/E_NOT_OK, DataServices_DID_F199_ProgrammingDate_DiagProgrammingDate_0_0/E_PENDING]
        arg Data: type=Dcm_Data4ByteType, direction=IN
        arg OpStatus: type=Dcm_OpStatusType, direction=IN
        arg ErrorCode: type=Dcm_NegativeResponseCodeType, direction=OUT
      error E_NOT_OK: error-code=1
      error E_PENDING: error-code=10
    DataServices_DID_F1DB_GMEndModelPartNumberAlphaCode_GMEndModelPartNumberAlphaCode_0_0
      operation ReadData: possible-error=[DataServices_DID_F1DB_GMEndModelPartNumberAlphaCode_GMEndModelPartNumberAlphaCode_0_0/E_NOT_OK, DataServices_DID_F1DB_GMEndModelPartNumberAlphaCode_GMEndModelPartNumberAlphaCode_0_0/E_PENDING]
        arg OpStatus: type=Dcm_OpStatusType, direction=IN
        arg Data: type=Dcm_Data2ByteType, direction=OUT
      error E_NOT_OK: error-code=1
      error E_PENDING: error-code=10
    DataServices_DID_F0F4_SignatureBypassAuthorizationTicket_SignatureBypassAuthorizationTicket_0_0
      operation ReadData: possible-error=[DataServices_DID_F0F4_SignatureBypassAuthorizationTicket_SignatureBypassAuthorizationTicket_0_0/E_NOT_OK, DataServices_DID_F0F4_SignatureBypassAuthorizationTicket_SignatureBypassAuthorizationTicket_0_0/E_PENDING]
        arg OpStatus: type=Dcm_OpStatusType, direction=IN
        arg Data: type=Dcm_Data822ByteType, direction=OUT
      operation WriteData: possible-error=[DataServices_DID_F0F4_SignatureBypassAuthorizationTicket_SignatureBypassAuthorizationTicket_0_0/E_NOT_OK, DataServices_DID_F0F4_SignatureBypassAuthorizationTicket_SignatureBypassAuthorizationTicket_0_0/E_PENDING]
        arg Data: type=Dcm_Data822ByteType, direction=IN
        arg OpStatus: type=Dcm_OpStatusType, direction=IN
        arg ErrorCode: type=Dcm_NegativeResponseCodeType, direction=OUT
      error E_NOT_OK: error-code=1
      error E_PENDING: error-code=10
    DataServices_DID_F11A_GMSoftwareModuleIdentifier_24_GMSoftwareModuleIdentifier_24_0_0
      operation ReadData: possible-error=[DataServices_DID_F11A_GMSoftwareModuleIdentifier_24_GMSoftwareModuleIdentifier_24_0_0/E_NOT_OK, DataServices_DID_F11A_GMSoftwareModuleIdentifier_24_GMSoftwareModuleIdentifier_24_0_0/E_PENDING]
        arg OpStatus: type=Dcm_OpStatusType, direction=IN
        arg Data: type=Dcm_Data4ByteType, direction=OUT
      error E_NOT_OK: error-code=1
      error E_PENDING: error-code=10
    DataServices_DID_F101_GMSoftwareModuleIdentifierAlphaCode_11_GMSoftwareModuleIdentifierAlphaCode_11_0_0
      operation ReadData: possible-error=[DataServices_DID_F101_GMSoftwareModuleIdentifierAlphaCode_11_GMSoftwareModuleIdentifierAlphaCode_11_0_0/E_NOT_OK, DataServices_DID_F101_GMSoftwareModuleIdentifierAlphaCode_11_GMSoftwareModuleIdentifierAlphaCode_11_0_0/E_PENDING]
        arg OpStatus: type=Dcm_OpStatusType, direction=IN
        arg Data: type=Dcm_Data2ByteType, direction=OUT
      error E_NOT_OK: error-code=1
      error E_PENDING: error-code=10
    DataServices_DID_F2A0_ReadMemoryEnableCounter_DiagReadMemoryEnableCounter_0_0
      operation ReadData: possible-error=[DataServices_DID_F2A0_ReadMemoryEnableCounter_DiagReadMemoryEnableCounter_0_0/E_NOT_OK, DataServices_DID_F2A0_ReadMemoryEnableCounter_DiagReadMemoryEnableCounter_0_0/E_PENDING]
        arg OpStatus: type=Dcm_OpStatusType, direction=IN
        arg Data: type=Dcm_Data1ByteType, direction=OUT
      operation WriteData: possible-error=[DataServices_DID_F2A0_ReadMemoryEnableCounter_DiagReadMemoryEnableCounter_0_0/E_NOT_OK, DataServices_DID_F2A0_ReadMemoryEnableCounter_DiagReadMemoryEnableCounter_0_0/E_PENDING]
        arg Data: type=Dcm_Data1ByteType, direction=IN
        arg OpStatus: type=Dcm_OpStatusType, direction=IN
        arg ErrorCode: type=Dcm_NegativeResponseCodeType, direction=OUT
      error E_NOT_OK: error-code=1
      error E_PENDING: error-code=10
    DataServices_DID_F1CB_GMEndModelPartNumber_GMEndModelPartNumber_0_0
      operation ReadData: possible-error=[DataServices_DID_F1CB_GMEndModelPartNumber_GMEndModelPartNumber_0_0/E_NOT_OK, DataServices_DID_F1CB_GMEndModelPartNumber_GMEndModelPartNumber_0_0/E_PENDING]
        arg OpStatus: type=Dcm_OpStatusType, direction=IN
        arg Data: type=Dcm_Data4ByteType, direction=OUT
      error E_NOT_OK: error-code=1
      error E_PENDING: error-code=10
    DataServices_DID_F1A9_GMXMLRepairShopCodeOrTesterSerialNumber_DiagXMLRepairShopCodeOrTesterSerialNumber_0_0
      operation ReadData: possible-error=[DataServices_DID_F1A9_GMXMLRepairShopCodeOrTesterSerialNumber_DiagXMLRepairShopCodeOrTesterSerialNumber_0_0/E_NOT_OK, DataServices_DID_F1A9_GMXMLRepairShopCodeOrTesterSerialNumber_DiagXMLRepairShopCodeOrTesterSerialNumber_0_0/E_PENDING]
        arg OpStatus: type=Dcm_OpStatusType, direction=IN
        arg Data: type=Dcm_Data10ByteType, direction=OUT
      operation WriteData: possible-error=[DataServices_DID_F1A9_GMXMLRepairShopCodeOrTesterSerialNumber_DiagXMLRepairShopCodeOrTesterSerialNumber_0_0/E_NOT_OK, DataServices_DID_F1A9_GMXMLRepairShopCodeOrTesterSerialNumber_DiagXMLRepairShopCodeOrTesterSerialNumber_0_0/E_PENDING]
        arg Data: type=Dcm_Data10ByteType, direction=IN
        arg OpStatus: type=Dcm_OpStatusType, direction=IN
        arg ErrorCode: type=Dcm_NegativeResponseCodeType, direction=OUT
      error E_NOT_OK: error-code=1
      error E_PENDING: error-code=10
    DataServices_DID_F080_ECUKeyProvisionStateFlag_ECUKeyProvisionStateFlag_0_0
      operation ReadData: possible-error=[DataServices_DID_F080_ECUKeyProvisionStateFlag_ECUKeyProvisionStateFlag_0_0/E_NOT_OK, DataServices_DID_F080_ECUKeyProvisionStateFlag_ECUKeyProvisionStateFlag_0_0/E_PENDING]
        arg OpStatus: type=Dcm_OpStatusType, direction=IN
        arg Data: type=Dcm_Data1ByteType, direction=OUT
      operation WriteData: possible-error=[DataServices_DID_F080_ECUKeyProvisionStateFlag_ECUKeyProvisionStateFlag_0_0/E_NOT_OK, DataServices_DID_F080_ECUKeyProvisionStateFlag_ECUKeyProvisionStateFlag_0_0/E_PENDING]
        arg Data: type=Dcm_Data1ByteType, direction=IN
        arg OpStatus: type=Dcm_OpStatusType, direction=IN
        arg ErrorCode: type=Dcm_NegativeResponseCodeType, direction=OUT
      error E_NOT_OK: error-code=1
      error E_PENDING: error-code=10
    DataServices_DID_F1D3_GMSoftwareModuleIdentifierAlphaCode_03_GMSoftwareModuleIdentifierAlphaCode_03_0_0
      operation ReadData: possible-error=[DataServices_DID_F1D3_GMSoftwareModuleIdentifierAlphaCode_03_GMSoftwareModuleIdentifierAlphaCode_03_0_0/E_NOT_OK, DataServices_DID_F1D3_GMSoftwareModuleIdentifierAlphaCode_03_GMSoftwareModuleIdentifierAlphaCode_03_0_0/E_PENDING]
        arg OpStatus: type=Dcm_OpStatusType, direction=IN
        arg Data: type=Dcm_Data2ByteType, direction=OUT
      error E_NOT_OK: error-code=1
      error E_PENDING: error-code=10
    DataServices_DID_F1DC_GMBaseModelPartNumberAlphaCode_GMBaseModelPartNumberAlphaCode_0_0
      operation ReadData: possible-error=[DataServices_DID_F1DC_GMBaseModelPartNumberAlphaCode_GMBaseModelPartNumberAlphaCode_0_0/E_NOT_OK, DataServices_DID_F1DC_GMBaseModelPartNumberAlphaCode_GMBaseModelPartNumberAlphaCode_0_0/E_PENDING]
        arg OpStatus: type=Dcm_OpStatusType, direction=IN
        arg Data: type=Dcm_Data2ByteType, direction=OUT
      error E_NOT_OK: error-code=1
      error E_PENDING: error-code=10
    DataServices_DID_F106_GMSoftwareModuleIdentifier_14_GMSoftwareModuleIdentifier_14_0_0
      operation ReadData: possible-error=[DataServices_DID_F106_GMSoftwareModuleIdentifier_14_GMSoftwareModuleIdentifier_14_0_0/E_NOT_OK, DataServices_DID_F106_GMSoftwareModuleIdentifier_14_GMSoftwareModuleIdentifier_14_0_0/E_PENDING]
        arg OpStatus: type=Dcm_OpStatusType, direction=IN
        arg Data: type=Dcm_Data4ByteType, direction=OUT
      error E_NOT_OK: error-code=1
      error E_PENDING: error-code=10
    DataServices_DID_F113_GMSoftwareModuleIdentifierAlphaCode_20_GMSoftwareModuleIdentifierAlphaCode_20_0_0
      operation ReadData: possible-error=[DataServices_DID_F113_GMSoftwareModuleIdentifierAlphaCode_20_GMSoftwareModuleIdentifierAlphaCode_20_0_0/E_NOT_OK, DataServices_DID_F113_GMSoftwareModuleIdentifierAlphaCode_20_GMSoftwareModuleIdentifierAlphaCode_20_0_0/E_PENDING]
        arg OpStatus: type=Dcm_OpStatusType, direction=IN
        arg Data: type=Dcm_Data2ByteType, direction=OUT
      error E_NOT_OK: error-code=1
      error E_PENDING: error-code=10
    DataServices_DID_F109_GMSoftwareModuleIdentifierAlphaCode_15_GMSoftwareModuleIdentifierAlphaCode_15_0_0
      operation ReadData: possible-error=[DataServices_DID_F109_GMSoftwareModuleIdentifierAlphaCode_15_GMSoftwareModuleIdentifierAlphaCode_15_0_0/E_NOT_OK, DataServices_DID_F109_GMSoftwareModuleIdentifierAlphaCode_15_GMSoftwareModuleIdentifierAlphaCode_15_0_0/E_PENDING]
        arg OpStatus: type=Dcm_OpStatusType, direction=IN
        arg Data: type=Dcm_Data2ByteType, direction=OUT
      error E_NOT_OK: error-code=1
      error E_PENDING: error-code=10
    DataServices_DID_F1D1_GMSoftwareModuleIdentifierAlphaCode_01_GMSoftwareModuleIdentifierAlphaCode_01_0_0
      operation ReadData: possible-error=[DataServices_DID_F1D1_GMSoftwareModuleIdentifierAlphaCode_01_GMSoftwareModuleIdentifierAlphaCode_01_0_0/E_NOT_OK, DataServices_DID_F1D1_GMSoftwareModuleIdentifierAlphaCode_01_GMSoftwareModuleIdentifierAlphaCode_01_0_0/E_PENDING]
        arg OpStatus: type=Dcm_OpStatusType, direction=IN
        arg Data: type=Dcm_Data2ByteType, direction=OUT
      error E_NOT_OK: error-code=1
      error E_PENDING: error-code=10
    DataServices_DID_F0F6_BootInfoBlockSubjectNameandECUName_SubjectName_0_0
      operation ReadData: possible-error=[DataServices_DID_F0F6_BootInfoBlockSubjectNameandECUName_SubjectName_0_0/E_NOT_OK, DataServices_DID_F0F6_BootInfoBlockSubjectNameandECUName_SubjectName_0_0/E_PENDING]
        arg OpStatus: type=Dcm_OpStatusType, direction=IN
        arg Data: type=Dcm_Data16ByteType, direction=OUT
      error E_NOT_OK: error-code=1
      error E_PENDING: error-code=10
    DataServices_DID_F0F6_BootInfoBlockSubjectNameandECUName_ECUName_16_0
      operation ReadData: possible-error=[DataServices_DID_F0F6_BootInfoBlockSubjectNameandECUName_ECUName_16_0/E_NOT_OK, DataServices_DID_F0F6_BootInfoBlockSubjectNameandECUName_ECUName_16_0/E_PENDING]
        arg OpStatus: type=Dcm_OpStatusType, direction=IN
        arg Data: type=Dcm_Data8ByteType, direction=OUT
      error E_NOT_OK: error-code=1
      error E_PENDING: error-code=10
    DataServices_DID_F084_MessageAuthenticationAntiReplayCounters_MessageAuthenticationAntiReplayCounters_0_0
      operation ReadData: possible-error=[DataServices_DID_F084_MessageAuthenticationAntiReplayCounters_MessageAuthenticationAntiReplayCounters_0_0/E_NOT_OK, DataServices_DID_F084_MessageAuthenticationAntiReplayCounters_MessageAuthenticationAntiReplayCounters_0_0/E_PENDING]
        arg OpStatus: type=Dcm_OpStatusType, direction=IN
        arg Data: type=Dcm_Data1ByteType, direction=OUT
      operation ReadDataLength: possible-error=[DataServices_DID_F084_MessageAuthenticationAntiReplayCounters_MessageAuthenticationAntiReplayCounters_0_0/E_NOT_OK, DataServices_DID_F084_MessageAuthenticationAntiReplayCounters_MessageAuthenticationAntiReplayCounters_0_0/E_PENDING]
        arg OpStatus: type=Dcm_OpStatusType, direction=IN
        arg DataLength: type=uint16, direction=OUT
      error E_NOT_OK: error-code=1
      error E_PENDING: error-code=10
    DataServices_DID_F108_GMSoftwareModuleIdentifier_15_GMSoftwareModuleIdentifier_15_0_0
      operation ReadData: possible-error=[DataServices_DID_F108_GMSoftwareModuleIdentifier_15_GMSoftwareModuleIdentifier_15_0_0/E_NOT_OK, DataServices_DID_F108_GMSoftwareModuleIdentifier_15_GMSoftwareModuleIdentifier_15_0_0/E_PENDING]
        arg OpStatus: type=Dcm_OpStatusType, direction=IN
        arg Data: type=Dcm_Data4ByteType, direction=OUT
      error E_NOT_OK: error-code=1
      error E_PENDING: error-code=10
    DataServices_DID_F10D_GMSoftwareModuleIdentifierAlphaCode_17_GMSoftwareModuleIdentifierAlphaCode_17_0_0
      operation ReadData: possible-error=[DataServices_DID_F10D_GMSoftwareModuleIdentifierAlphaCode_17_GMSoftwareModuleIdentifierAlphaCode_17_0_0/E_NOT_OK, DataServices_DID_F10D_GMSoftwareModuleIdentifierAlphaCode_17_GMSoftwareModuleIdentifierAlphaCode_17_0_0/E_PENDING]
        arg OpStatus: type=Dcm_OpStatusType, direction=IN
        arg Data: type=Dcm_Data2ByteType, direction=OUT
      error E_NOT_OK: error-code=1
      error E_PENDING: error-code=10
    DataServices_DID_F11B_GMSoftwareModuleIdentifierAlphaCode_24_GMSoftwareModuleIdentifierAlphaCode_24_0_0
      operation ReadData: possible-error=[DataServices_DID_F11B_GMSoftwareModuleIdentifierAlphaCode_24_GMSoftwareModuleIdentifierAlphaCode_24_0_0/E_NOT_OK, DataServices_DID_F11B_GMSoftwareModuleIdentifierAlphaCode_24_GMSoftwareModuleIdentifierAlphaCode_24_0_0/E_PENDING]
        arg OpStatus: type=Dcm_OpStatusType, direction=IN
        arg Data: type=Dcm_Data2ByteType, direction=OUT
      error E_NOT_OK: error-code=1
      error E_PENDING: error-code=10
    DataServices_DID_F1CA_GMSoftwareModuleIdentifier_10_GMSoftwareModuleIdentifier_10_0_0
      operation ReadData: possible-error=[DataServices_DID_F1CA_GMSoftwareModuleIdentifier_10_GMSoftwareModuleIdentifier_10_0_0/E_NOT_OK, DataServices_DID_F1CA_GMSoftwareModuleIdentifier_10_GMSoftwareModuleIdentifier_10_0_0/E_PENDING]
        arg OpStatus: type=Dcm_OpStatusType, direction=IN
        arg Data: type=Dcm_Data4ByteType, direction=OUT
      error E_NOT_OK: error-code=1
      error E_PENDING: error-code=10
    DataServices_DID_F1C5_GMSoftwareModuleIdentifier_05_GMSoftwareModuleIdentifier_05_0_0
      operation ReadData: possible-error=[DataServices_DID_F1C5_GMSoftwareModuleIdentifier_05_GMSoftwareModuleIdentifier_05_0_0/E_NOT_OK, DataServices_DID_F1C5_GMSoftwareModuleIdentifier_05_GMSoftwareModuleIdentifier_05_0_0/E_PENDING]
        arg OpStatus: type=Dcm_OpStatusType, direction=IN
        arg Data: type=Dcm_Data4ByteType, direction=OUT
      error E_NOT_OK: error-code=1
      error E_PENDING: error-code=10
    DataServices_DID_F1B0_ECUDiagnosticAddress_ECUDiagnosticAddress_0_0
      operation ReadData: possible-error=[DataServices_DID_F1B0_ECUDiagnosticAddress_ECUDiagnosticAddress_0_0/E_NOT_OK, DataServices_DID_F1B0_ECUDiagnosticAddress_ECUDiagnosticAddress_0_0/E_PENDING]
        arg OpStatus: type=Dcm_OpStatusType, direction=IN
        arg Data: type=Dcm_Data1ByteType, direction=OUT
      error E_NOT_OK: error-code=1
      error E_PENDING: error-code=10
    DataServices_DID_F11D_GMSoftwareModuleIdentifierAlphaCode_25_GMSoftwareModuleIdentifierAlphaCode_25_0_0
      operation ReadData: possible-error=[DataServices_DID_F11D_GMSoftwareModuleIdentifierAlphaCode_25_GMSoftwareModuleIdentifierAlphaCode_25_0_0/E_NOT_OK, DataServices_DID_F11D_GMSoftwareModuleIdentifierAlphaCode_25_GMSoftwareModuleIdentifierAlphaCode_25_0_0/E_PENDING]
        arg OpStatus: type=Dcm_OpStatusType, direction=IN
        arg Data: type=Dcm_Data2ByteType, direction=OUT
      error E_NOT_OK: error-code=1
      error E_PENDING: error-code=10
    DataServices_DID_F081_ECUKeyConfigurationData_ECUKeyConfigurationData_0_0
      operation ReadData: possible-error=[DataServices_DID_F081_ECUKeyConfigurationData_ECUKeyConfigurationData_0_0/E_NOT_OK, DataServices_DID_F081_ECUKeyConfigurationData_ECUKeyConfigurationData_0_0/E_PENDING]
        arg OpStatus: type=Dcm_OpStatusType, direction=IN
        arg Data: type=Dcm_Data4ByteType, direction=OUT
      error E_NOT_OK: error-code=1
      error E_PENDING: error-code=10
    DataServices_DID_F1D7_GMSoftwareModuleIdentifierAlphaCode_07_GMSoftwareModuleIdentifierAlphaCode_07_0_0
      operation ReadData: possible-error=[DataServices_DID_F1D7_GMSoftwareModuleIdentifierAlphaCode_07_GMSoftwareModuleIdentifierAlphaCode_07_0_0/E_NOT_OK, DataServices_DID_F1D7_GMSoftwareModuleIdentifierAlphaCode_07_GMSoftwareModuleIdentifierAlphaCode_07_0_0/E_PENDING]
        arg OpStatus: type=Dcm_OpStatusType, direction=IN
        arg Data: type=Dcm_Data2ByteType, direction=OUT
      error E_NOT_OK: error-code=1
      error E_PENDING: error-code=10
    DataServices_DID_F09A_DiagnosticDataIdentifier_DiagSystemCode_0_0
      operation ReadData: possible-error=[DataServices_DID_F09A_DiagnosticDataIdentifier_DiagSystemCode_0_0/E_NOT_OK, DataServices_DID_F09A_DiagnosticDataIdentifier_DiagSystemCode_0_0/E_PENDING]
        arg OpStatus: type=Dcm_OpStatusType, direction=IN
        arg Data: type=Dcm_Data1ByteType, direction=OUT
      operation WriteData: possible-error=[DataServices_DID_F09A_DiagnosticDataIdentifier_DiagSystemCode_0_0/E_NOT_OK, DataServices_DID_F09A_DiagnosticDataIdentifier_DiagSystemCode_0_0/E_PENDING]
        arg Data: type=Dcm_Data1ByteType, direction=IN
        arg OpStatus: type=Dcm_OpStatusType, direction=IN
        arg ErrorCode: type=Dcm_NegativeResponseCodeType, direction=OUT
      error E_NOT_OK: error-code=1
      error E_PENDING: error-code=10
    DataServices_DID_F09A_DiagnosticDataIdentifier_DiagDiagnosticDataStreamVersionNumber_1_0
      operation ReadData: possible-error=[DataServices_DID_F09A_DiagnosticDataIdentifier_DiagDiagnosticDataStreamVersionNumber_1_0/E_NOT_OK, DataServices_DID_F09A_DiagnosticDataIdentifier_DiagDiagnosticDataStreamVersionNumber_1_0/E_PENDING]
        arg OpStatus: type=Dcm_OpStatusType, direction=IN
        arg Data: type=Dcm_Data1ByteType, direction=OUT
      operation WriteData: possible-error=[DataServices_DID_F09A_DiagnosticDataIdentifier_DiagDiagnosticDataStreamVersionNumber_1_0/E_NOT_OK, DataServices_DID_F09A_DiagnosticDataIdentifier_DiagDiagnosticDataStreamVersionNumber_1_0/E_PENDING]
        arg Data: type=Dcm_Data1ByteType, direction=IN
        arg OpStatus: type=Dcm_OpStatusType, direction=IN
        arg ErrorCode: type=Dcm_NegativeResponseCodeType, direction=OUT
      error E_NOT_OK: error-code=1
      error E_PENDING: error-code=10
    DataServices_DID_F11E_GMSoftwareModuleIdentifier_26_GMSoftwareModuleIdentifier_26_0_0
      operation ReadData: possible-error=[DataServices_DID_F11E_GMSoftwareModuleIdentifier_26_GMSoftwareModuleIdentifier_26_0_0/E_NOT_OK, DataServices_DID_F11E_GMSoftwareModuleIdentifier_26_GMSoftwareModuleIdentifier_26_0_0/E_PENDING]
        arg OpStatus: type=Dcm_OpStatusType, direction=IN
        arg Data: type=Dcm_Data4ByteType, direction=OUT
      error E_NOT_OK: error-code=1
      error E_PENDING: error-code=10
    DataServices_DID_F1C8_GMSoftwareModuleIdentifier_08_GMSoftwareModuleIdentifier_08_0_0
      operation ReadData: possible-error=[DataServices_DID_F1C8_GMSoftwareModuleIdentifier_08_GMSoftwareModuleIdentifier_08_0_0/E_NOT_OK, DataServices_DID_F1C8_GMSoftwareModuleIdentifier_08_GMSoftwareModuleIdentifier_08_0_0/E_PENDING]
        arg OpStatus: type=Dcm_OpStatusType, direction=IN
        arg Data: type=Dcm_Data4ByteType, direction=OUT
      error E_NOT_OK: error-code=1
      error E_PENDING: error-code=10
    DataServices_DID_F118_GMSoftwareModuleIdentifier_23_GMSoftwareModuleIdentifier_23_0_0
      operation ReadData: possible-error=[DataServices_DID_F118_GMSoftwareModuleIdentifier_23_GMSoftwareModuleIdentifier_23_0_0/E_NOT_OK, DataServices_DID_F118_GMSoftwareModuleIdentifier_23_GMSoftwareModuleIdentifier_23_0_0/E_PENDING]
        arg OpStatus: type=Dcm_OpStatusType, direction=IN
        arg Data: type=Dcm_Data4ByteType, direction=OUT
      error E_NOT_OK: error-code=1
      error E_PENDING: error-code=10
    DataServices_DID_F1C9_GMSoftwareModuleIdentifier_09_GMSoftwareModuleIdentifier_09_0_0
      operation ReadData: possible-error=[DataServices_DID_F1C9_GMSoftwareModuleIdentifier_09_GMSoftwareModuleIdentifier_09_0_0/E_NOT_OK, DataServices_DID_F1C9_GMSoftwareModuleIdentifier_09_GMSoftwareModuleIdentifier_09_0_0/E_PENDING]
        arg OpStatus: type=Dcm_OpStatusType, direction=IN
        arg Data: type=Dcm_Data4ByteType, direction=OUT
      error E_NOT_OK: error-code=1
      error E_PENDING: error-code=10
    DataServices_DID_F125_GMSoftwareModuleIdentifierAlphaCode_29_GMSoftwareModuleIdentifierAlphaCode_29_0_0
      operation ReadData: possible-error=[DataServices_DID_F125_GMSoftwareModuleIdentifierAlphaCode_29_GMSoftwareModuleIdentifierAlphaCode_29_0_0/E_NOT_OK, DataServices_DID_F125_GMSoftwareModuleIdentifierAlphaCode_29_GMSoftwareModuleIdentifierAlphaCode_29_0_0/E_PENDING]
        arg OpStatus: type=Dcm_OpStatusType, direction=IN
        arg Data: type=Dcm_Data2ByteType, direction=OUT
      error E_NOT_OK: error-code=1
      error E_PENDING: error-code=10
    DataServices_DID_F0F3_ECUID_ECUID_0_0
      operation ReadData: possible-error=[DataServices_DID_F0F3_ECUID_ECUID_0_0/E_NOT_OK, DataServices_DID_F0F3_ECUID_ECUID_0_0/E_PENDING]
        arg OpStatus: type=Dcm_OpStatusType, direction=IN
        arg Data: type=Dcm_Data16ByteType, direction=OUT
      error E_NOT_OK: error-code=1
      error E_PENDING: error-code=10
    DataServices_DID_F115_GMSoftwareModuleIdentifierAlphaCode_21_GMSoftwareModuleIdentifierAlphaCode_21_0_0
      operation ReadData: possible-error=[DataServices_DID_F115_GMSoftwareModuleIdentifierAlphaCode_21_GMSoftwareModuleIdentifierAlphaCode_21_0_0/E_NOT_OK, DataServices_DID_F115_GMSoftwareModuleIdentifierAlphaCode_21_GMSoftwareModuleIdentifierAlphaCode_21_0_0/E_PENDING]
        arg OpStatus: type=Dcm_OpStatusType, direction=IN
        arg Data: type=Dcm_Data2ByteType, direction=OUT
      error E_NOT_OK: error-code=1
      error E_PENDING: error-code=10
    DataServices_DID_F123_GMSoftwareModuleIdentifierAlphaCode_28_GMSoftwareModuleIdentifierAlphaCode_28_0_0
      operation ReadData: possible-error=[DataServices_DID_F123_GMSoftwareModuleIdentifierAlphaCode_28_GMSoftwareModuleIdentifierAlphaCode_28_0_0/E_NOT_OK, DataServices_DID_F123_GMSoftwareModuleIdentifierAlphaCode_28_GMSoftwareModuleIdentifierAlphaCode_28_0_0/E_PENDING]
        arg OpStatus: type=Dcm_OpStatusType, direction=IN
        arg Data: type=Dcm_Data2ByteType, direction=OUT
      error E_NOT_OK: error-code=1
      error E_PENDING: error-code=10
    DataServices_DID_F1D2_GMSoftwareModuleIdentifierAlphaCode_02_GMSoftwareModuleIdentifierAlphaCode_02_0_0
      operation ReadData: possible-error=[DataServices_DID_F1D2_GMSoftwareModuleIdentifierAlphaCode_02_GMSoftwareModuleIdentifierAlphaCode_02_0_0/E_NOT_OK, DataServices_DID_F1D2_GMSoftwareModuleIdentifierAlphaCode_02_GMSoftwareModuleIdentifierAlphaCode_02_0_0/E_PENDING]
        arg OpStatus: type=Dcm_OpStatusType, direction=IN
        arg Data: type=Dcm_Data2ByteType, direction=OUT
      error E_NOT_OK: error-code=1
      error E_PENDING: error-code=10
    DataServices_DID_F1C4_GMSoftwareModuleIdentifier_04_GMSoftwareModuleIdentifier_04_0_0
      operation ReadData: possible-error=[DataServices_DID_F1C4_GMSoftwareModuleIdentifier_04_GMSoftwareModuleIdentifier_04_0_0/E_NOT_OK, DataServices_DID_F1C4_GMSoftwareModuleIdentifier_04_GMSoftwareModuleIdentifier_04_0_0/E_PENDING]
        arg OpStatus: type=Dcm_OpStatusType, direction=IN
        arg Data: type=Dcm_Data4ByteType, direction=OUT
      error E_NOT_OK: error-code=1
      error E_PENDING: error-code=10
    DataServices_DID_F1C2_GMSoftwareModuleIdentifier_02_GMSoftwareModuleIdentifier_02_0_0
      operation ReadData: possible-error=[DataServices_DID_F1C2_GMSoftwareModuleIdentifier_02_GMSoftwareModuleIdentifier_02_0_0/E_NOT_OK, DataServices_DID_F1C2_GMSoftwareModuleIdentifier_02_GMSoftwareModuleIdentifier_02_0_0/E_PENDING]
        arg OpStatus: type=Dcm_OpStatusType, direction=IN
        arg Data: type=Dcm_Data4ByteType, direction=OUT
      error E_NOT_OK: error-code=1
      error E_PENDING: error-code=10
    DataServices_DID_F083_MessageAuthenticationCalibrationFilePartNumber_MessageAuthenticationCalibrationFilePartNumber_0_0
      operation ReadData: possible-error=[DataServices_DID_F083_MessageAuthenticationCalibrationFilePartNumber_MessageAuthenticationCalibrationFilePartNumber_0_0/E_NOT_OK, DataServices_DID_F083_MessageAuthenticationCalibrationFilePartNumber_MessageAuthenticationCalibrationFilePartNumber_0_0/E_PENDING]
        arg OpStatus: type=Dcm_OpStatusType, direction=IN
        arg Data: type=Dcm_Data4ByteType, direction=OUT
      error E_NOT_OK: error-code=1
      error E_PENDING: error-code=10
    DataServices_DID_F110_GMSoftwareModuleIdentifier_19_GMSoftwareModuleIdentifier_19_0_0
      operation ReadData: possible-error=[DataServices_DID_F110_GMSoftwareModuleIdentifier_19_GMSoftwareModuleIdentifier_19_0_0/E_NOT_OK, DataServices_DID_F110_GMSoftwareModuleIdentifier_19_GMSoftwareModuleIdentifier_19_0_0/E_PENDING]
        arg OpStatus: type=Dcm_OpStatusType, direction=IN
        arg Data: type=Dcm_Data4ByteType, direction=OUT
      error E_NOT_OK: error-code=1
      error E_PENDING: error-code=10
    DataServices_DID_F124_GMSoftwareModuleIdentifier_29_GMSoftwareModuleIdentifier_29_0_0
      operation ReadData: possible-error=[DataServices_DID_F124_GMSoftwareModuleIdentifier_29_GMSoftwareModuleIdentifier_29_0_0/E_NOT_OK, DataServices_DID_F124_GMSoftwareModuleIdentifier_29_GMSoftwareModuleIdentifier_29_0_0/E_PENDING]
        arg OpStatus: type=Dcm_OpStatusType, direction=IN
        arg Data: type=Dcm_Data4ByteType, direction=OUT
      error E_NOT_OK: error-code=1
      error E_PENDING: error-code=10
    DataServices_DID_F119_GMSoftwareModuleIdentifierAlphaCode_23_GMSoftwareModuleIdentifierAlphaCode_23_0_0
      operation ReadData: possible-error=[DataServices_DID_F119_GMSoftwareModuleIdentifierAlphaCode_23_GMSoftwareModuleIdentifierAlphaCode_23_0_0/E_NOT_OK, DataServices_DID_F119_GMSoftwareModuleIdentifierAlphaCode_23_GMSoftwareModuleIdentifierAlphaCode_23_0_0/E_PENDING]
        arg OpStatus: type=Dcm_OpStatusType, direction=IN
        arg Data: type=Dcm_Data2ByteType, direction=OUT
      error E_NOT_OK: error-code=1
      error E_PENDING: error-code=10
    DataServices_DID_F1D8_GMSoftwareModuleIdentifierAlphaCode_08_GMSoftwareModuleIdentifierAlphaCode_08_0_0
      operation ReadData: possible-error=[DataServices_DID_F1D8_GMSoftwareModuleIdentifierAlphaCode_08_GMSoftwareModuleIdentifierAlphaCode_08_0_0/E_NOT_OK, DataServices_DID_F1D8_GMSoftwareModuleIdentifierAlphaCode_08_GMSoftwareModuleIdentifierAlphaCode_08_0_0/E_PENDING]
        arg OpStatus: type=Dcm_OpStatusType, direction=IN
        arg Data: type=Dcm_Data2ByteType, direction=OUT
      error E_NOT_OK: error-code=1
      error E_PENDING: error-code=10
    DataServices_DID_F129_TotalVehicleOperationTime_DataRecord
      operation ReadData: possible-error=[DataServices_DID_F129_TotalVehicleOperationTime_DataRecord/E_NOT_OK, DataServices_DID_F129_TotalVehicleOperationTime_DataRecord/E_PENDING]
        arg OpStatus: type=Dcm_OpStatusType, direction=IN
        arg Data: type=Dcm_Data6ByteType, direction=OUT
      operation WriteData: possible-error=[DataServices_DID_F129_TotalVehicleOperationTime_DataRecord/E_NOT_OK, DataServices_DID_F129_TotalVehicleOperationTime_DataRecord/E_PENDING]
        arg Data: type=Dcm_Data6ByteType, direction=IN
        arg OpStatus: type=Dcm_OpStatusType, direction=IN
        arg ErrorCode: type=Dcm_NegativeResponseCodeType, direction=OUT
      error E_NOT_OK: error-code=1
      error E_PENDING: error-code=10
    DataServices_DID_F1D9_GMSoftwareModuleIdentifierAlphaCode_09_GMSoftwareModuleIdentifierAlphaCode_09_0_0
      operation ReadData: possible-error=[DataServices_DID_F1D9_GMSoftwareModuleIdentifierAlphaCode_09_GMSoftwareModuleIdentifierAlphaCode_09_0_0/E_NOT_OK, DataServices_DID_F1D9_GMSoftwareModuleIdentifierAlphaCode_09_GMSoftwareModuleIdentifierAlphaCode_09_0_0/E_PENDING]
        arg OpStatus: type=Dcm_OpStatusType, direction=IN
        arg Data: type=Dcm_Data2ByteType, direction=OUT
      error E_NOT_OK: error-code=1
      error E_PENDING: error-code=10
    DataServices_DID_F126_GMSoftwareModuleIdentifier_30_GMSoftwareModuleIdentifier_30_0_0
      operation ReadData: possible-error=[DataServices_DID_F126_GMSoftwareModuleIdentifier_30_GMSoftwareModuleIdentifier_30_0_0/E_NOT_OK, DataServices_DID_F126_GMSoftwareModuleIdentifier_30_GMSoftwareModuleIdentifier_30_0_0/E_PENDING]
        arg OpStatus: type=Dcm_OpStatusType, direction=IN
        arg Data: type=Dcm_Data4ByteType, direction=OUT
      error E_NOT_OK: error-code=1
      error E_PENDING: error-code=10
    DataServices_DID_F190_VehicleIdentificationNumber_VehicleIdentificationNumber_0_0
      operation ReadData: possible-error=[DataServices_DID_F190_VehicleIdentificationNumber_VehicleIdentificationNumber_0_0/E_NOT_OK, DataServices_DID_F190_VehicleIdentificationNumber_VehicleIdentificationNumber_0_0/E_PENDING]
        arg OpStatus: type=Dcm_OpStatusType, direction=IN
        arg Data: type=Dcm_Data17ByteType, direction=OUT
      operation WriteData: possible-error=[DataServices_DID_F190_VehicleIdentificationNumber_VehicleIdentificationNumber_0_0/E_NOT_OK, DataServices_DID_F190_VehicleIdentificationNumber_VehicleIdentificationNumber_0_0/E_PENDING]
        arg Data: type=Dcm_Data17ByteType, direction=IN
        arg OpStatus: type=Dcm_OpStatusType, direction=IN
        arg ErrorCode: type=Dcm_NegativeResponseCodeType, direction=OUT
      error E_NOT_OK: error-code=1
      error E_PENDING: error-code=10
    DataServices_DID_F1C7_GMSoftwareModuleIdentifier_07_GMSoftwareModuleIdentifier_07_0_0
      operation ReadData: possible-error=[DataServices_DID_F1C7_GMSoftwareModuleIdentifier_07_GMSoftwareModuleIdentifier_07_0_0/E_NOT_OK, DataServices_DID_F1C7_GMSoftwareModuleIdentifier_07_GMSoftwareModuleIdentifier_07_0_0/E_PENDING]
        arg OpStatus: type=Dcm_OpStatusType, direction=IN
        arg Data: type=Dcm_Data4ByteType, direction=OUT
      error E_NOT_OK: error-code=1
      error E_PENDING: error-code=10
    DataServices_DID_F0B3_DataUniversalNumberingSystemIdentification_DiagDataUniversalNumberingSystemIdentification_0_0
      operation ReadData: possible-error=[DataServices_DID_F0B3_DataUniversalNumberingSystemIdentification_DiagDataUniversalNumberingSystemIdentification_0_0/E_NOT_OK, DataServices_DID_F0B3_DataUniversalNumberingSystemIdentification_DiagDataUniversalNumberingSystemIdentification_0_0/E_PENDING]
        arg OpStatus: type=Dcm_OpStatusType, direction=IN
        arg Data: type=Dcm_Data9ByteType, direction=OUT
      error E_NOT_OK: error-code=1
      error E_PENDING: error-code=10
    DataServices_DID_F11F_GMSoftwareModuleIdentifierAlphaCode_26_GMSoftwareModuleIdentifierAlphaCode_26_0_0
      operation ReadData: possible-error=[DataServices_DID_F11F_GMSoftwareModuleIdentifierAlphaCode_26_GMSoftwareModuleIdentifierAlphaCode_26_0_0/E_NOT_OK, DataServices_DID_F11F_GMSoftwareModuleIdentifierAlphaCode_26_GMSoftwareModuleIdentifierAlphaCode_26_0_0/E_PENDING]
        arg OpStatus: type=Dcm_OpStatusType, direction=IN
        arg Data: type=Dcm_Data2ByteType, direction=OUT
      error E_NOT_OK: error-code=1
      error E_PENDING: error-code=10
    DataServices_DID_F10B_GMSoftwareModuleIdentifierAlphaCode_16_GMSoftwareModuleIdentifierAlphaCode_16_0_0
      operation ReadData: possible-error=[DataServices_DID_F10B_GMSoftwareModuleIdentifierAlphaCode_16_GMSoftwareModuleIdentifierAlphaCode_16_0_0/E_NOT_OK, DataServices_DID_F10B_GMSoftwareModuleIdentifierAlphaCode_16_GMSoftwareModuleIdentifierAlphaCode_16_0_0/E_PENDING]
        arg OpStatus: type=Dcm_OpStatusType, direction=IN
        arg Data: type=Dcm_Data2ByteType, direction=OUT
      error E_NOT_OK: error-code=1
      error E_PENDING: error-code=10
    DataServices_DID_F1D0_GMBootSoftwarePartNumberAlphaCode_GMBootSoftwarePartNumberAlphaCode_0_0
      operation ReadData: possible-error=[DataServices_DID_F1D0_GMBootSoftwarePartNumberAlphaCode_GMBootSoftwarePartNumberAlphaCode_0_0/E_NOT_OK, DataServices_DID_F1D0_GMBootSoftwarePartNumberAlphaCode_GMBootSoftwarePartNumberAlphaCode_0_0/E_PENDING]
        arg OpStatus: type=Dcm_OpStatusType, direction=IN
        arg Data: type=Dcm_Data2ByteType, direction=OUT
      error E_NOT_OK: error-code=1
      error E_PENDING: error-code=10
    DataServices_DID_F1D5_GMSoftwareModuleIdentifierAlphaCode_05_GMSoftwareModuleIdentifierAlphaCode_05_0_0
      operation ReadData: possible-error=[DataServices_DID_F1D5_GMSoftwareModuleIdentifierAlphaCode_05_GMSoftwareModuleIdentifierAlphaCode_05_0_0/E_NOT_OK, DataServices_DID_F1D5_GMSoftwareModuleIdentifierAlphaCode_05_GMSoftwareModuleIdentifierAlphaCode_05_0_0/E_PENDING]
        arg OpStatus: type=Dcm_OpStatusType, direction=IN
        arg Data: type=Dcm_Data2ByteType, direction=OUT
      error E_NOT_OK: error-code=1
      error E_PENDING: error-code=10
    DataServices_DID_F111_GMSoftwareModuleIdentifierAlphaCode_19_GMSoftwareModuleIdentifierAlphaCode_19_0_0
      operation ReadData: possible-error=[DataServices_DID_F111_GMSoftwareModuleIdentifierAlphaCode_19_GMSoftwareModuleIdentifierAlphaCode_19_0_0/E_NOT_OK, DataServices_DID_F111_GMSoftwareModuleIdentifierAlphaCode_19_GMSoftwareModuleIdentifierAlphaCode_19_0_0/E_PENDING]
        arg OpStatus: type=Dcm_OpStatusType, direction=IN
        arg Data: type=Dcm_Data2ByteType, direction=OUT
      error E_NOT_OK: error-code=1
      error E_PENDING: error-code=10
    DataServices_DID_F180_BootSoftwareIdentificationDataIdentifier_BootSoftwareIdentificationDataIdentifier_0_0
      operation ReadData: possible-error=[DataServices_DID_F180_BootSoftwareIdentificationDataIdentifier_BootSoftwareIdentificationDataIdentifier_0_0/E_NOT_OK, DataServices_DID_F180_BootSoftwareIdentificationDataIdentifier_BootSoftwareIdentificationDataIdentifier_0_0/E_PENDING]
        arg OpStatus: type=Dcm_OpStatusType, direction=IN
        arg Data: type=Dcm_Data1ByteType, direction=OUT
      operation ReadDataLength: possible-error=[DataServices_DID_F180_BootSoftwareIdentificationDataIdentifier_BootSoftwareIdentificationDataIdentifier_0_0/E_NOT_OK, DataServices_DID_F180_BootSoftwareIdentificationDataIdentifier_BootSoftwareIdentificationDataIdentifier_0_0/E_PENDING]
        arg OpStatus: type=Dcm_OpStatusType, direction=IN
        arg DataLength: type=uint16, direction=OUT
      error E_NOT_OK: error-code=1
      error E_PENDING: error-code=10
    DataServices_DID_F127_GMSoftwareModuleIdentifierAlphaCode_30_GMSoftwareModuleIdentifierAlphaCode_30_0_0
      operation ReadData: possible-error=[DataServices_DID_F127_GMSoftwareModuleIdentifierAlphaCode_30_GMSoftwareModuleIdentifierAlphaCode_30_0_0/E_NOT_OK, DataServices_DID_F127_GMSoftwareModuleIdentifierAlphaCode_30_GMSoftwareModuleIdentifierAlphaCode_30_0_0/E_PENDING]
        arg OpStatus: type=Dcm_OpStatusType, direction=IN
        arg Data: type=Dcm_Data2ByteType, direction=OUT
      error E_NOT_OK: error-code=1
      error E_PENDING: error-code=10
    DataServices_DID_F198_RepairShopCodeOrTesterSerialNumber_DiagRepairShopCodeOrTesterSerialNumber_0_0
      operation ReadData: possible-error=[DataServices_DID_F198_RepairShopCodeOrTesterSerialNumber_DiagRepairShopCodeOrTesterSerialNumber_0_0/E_NOT_OK, DataServices_DID_F198_RepairShopCodeOrTesterSerialNumber_DiagRepairShopCodeOrTesterSerialNumber_0_0/E_PENDING]
        arg OpStatus: type=Dcm_OpStatusType, direction=IN
        arg Data: type=Dcm_Data10ByteType, direction=OUT
      operation WriteData: possible-error=[DataServices_DID_F198_RepairShopCodeOrTesterSerialNumber_DiagRepairShopCodeOrTesterSerialNumber_0_0/E_NOT_OK, DataServices_DID_F198_RepairShopCodeOrTesterSerialNumber_DiagRepairShopCodeOrTesterSerialNumber_0_0/E_PENDING]
        arg Data: type=Dcm_Data10ByteType, direction=IN
        arg OpStatus: type=Dcm_OpStatusType, direction=IN
        arg ErrorCode: type=Dcm_NegativeResponseCodeType, direction=OUT
      error E_NOT_OK: error-code=1
      error E_PENDING: error-code=10
    DataServices_DID_F121_GMSoftwareModuleIdentifierAlphaCode_27_GMSoftwareModuleIdentifierAlphaCode_27_0_0
      operation ReadData: possible-error=[DataServices_DID_F121_GMSoftwareModuleIdentifierAlphaCode_27_GMSoftwareModuleIdentifierAlphaCode_27_0_0/E_NOT_OK, DataServices_DID_F121_GMSoftwareModuleIdentifierAlphaCode_27_GMSoftwareModuleIdentifierAlphaCode_27_0_0/E_PENDING]
        arg OpStatus: type=Dcm_OpStatusType, direction=IN
        arg Data: type=Dcm_Data2ByteType, direction=OUT
      error E_NOT_OK: error-code=1
      error E_PENDING: error-code=10
    DataServices_DID_F09C_GMXmlDataFilePartNumber_DiagGMXmlDataFilePartNumber_0_0
      operation ReadData: possible-error=[DataServices_DID_F09C_GMXmlDataFilePartNumber_DiagGMXmlDataFilePartNumber_0_0/E_NOT_OK, DataServices_DID_F09C_GMXmlDataFilePartNumber_DiagGMXmlDataFilePartNumber_0_0/E_PENDING]
        arg OpStatus: type=Dcm_OpStatusType, direction=IN
        arg Data: type=Dcm_Data4ByteType, direction=OUT
      operation WriteData: possible-error=[DataServices_DID_F09C_GMXmlDataFilePartNumber_DiagGMXmlDataFilePartNumber_0_0/E_NOT_OK, DataServices_DID_F09C_GMXmlDataFilePartNumber_DiagGMXmlDataFilePartNumber_0_0/E_PENDING]
        arg Data: type=Dcm_Data4ByteType, direction=IN
        arg OpStatus: type=Dcm_OpStatusType, direction=IN
        arg ErrorCode: type=Dcm_NegativeResponseCodeType, direction=OUT
      error E_NOT_OK: error-code=1
      error E_PENDING: error-code=10
    DataServices_DID_F0B4_ManufacturingTraceabilityCharacters_DiagYear_2_0
      operation ReadData: possible-error=[DataServices_DID_F0B4_ManufacturingTraceabilityCharacters_DiagYear_2_0/E_NOT_OK, DataServices_DID_F0B4_ManufacturingTraceabilityCharacters_DiagYear_2_0/E_PENDING]
        arg OpStatus: type=Dcm_OpStatusType, direction=IN
        arg Data: type=Dcm_Data2ByteType, direction=OUT
      error E_NOT_OK: error-code=1
      error E_PENDING: error-code=10
    DataServices_DID_F0B4_ManufacturingTraceabilityCharacters_DiagTraceabilityNumber_7_0
      operation ReadData: possible-error=[DataServices_DID_F0B4_ManufacturingTraceabilityCharacters_DiagTraceabilityNumber_7_0/E_NOT_OK, DataServices_DID_F0B4_ManufacturingTraceabilityCharacters_DiagTraceabilityNumber_7_0/E_PENDING]
        arg OpStatus: type=Dcm_OpStatusType, direction=IN
        arg Data: type=Dcm_Data9ByteType, direction=OUT
      error E_NOT_OK: error-code=1
      error E_PENDING: error-code=10
    DataServices_DID_F0B4_ManufacturingTraceabilityCharacters_DiagShift_1_0
      operation ReadData: possible-error=[DataServices_DID_F0B4_ManufacturingTraceabilityCharacters_DiagShift_1_0/E_NOT_OK, DataServices_DID_F0B4_ManufacturingTraceabilityCharacters_DiagShift_1_0/E_PENDING]
        arg OpStatus: type=Dcm_OpStatusType, direction=IN
        arg Data: type=Dcm_Data1ByteType, direction=OUT
      error E_NOT_OK: error-code=1
      error E_PENDING: error-code=10
    DataServices_DID_F0B4_ManufacturingTraceabilityCharacters_DiagLine_0_0
      operation ReadData: possible-error=[DataServices_DID_F0B4_ManufacturingTraceabilityCharacters_DiagLine_0_0/E_NOT_OK, DataServices_DID_F0B4_ManufacturingTraceabilityCharacters_DiagLine_0_0/E_PENDING]
        arg OpStatus: type=Dcm_OpStatusType, direction=IN
        arg Data: type=Dcm_Data1ByteType, direction=OUT
      error E_NOT_OK: error-code=1
      error E_PENDING: error-code=10
    DataServices_DID_F0B4_ManufacturingTraceabilityCharacters_DiagDayOfTheYear_4_0
      operation ReadData: possible-error=[DataServices_DID_F0B4_ManufacturingTraceabilityCharacters_DiagDayOfTheYear_4_0/E_NOT_OK, DataServices_DID_F0B4_ManufacturingTraceabilityCharacters_DiagDayOfTheYear_4_0/E_PENDING]
        arg OpStatus: type=Dcm_OpStatusType, direction=IN
        arg Data: type=Dcm_Data3ByteType, direction=OUT
      error E_NOT_OK: error-code=1
      error E_PENDING: error-code=10
    DataServices_DID_F0BE_MasterNetworkConfigurationListLIN_DiagMasterNetworkConfigurationListLIN_0_0
      operation ReadData: possible-error=[DataServices_DID_F0BE_MasterNetworkConfigurationListLIN_DiagMasterNetworkConfigurationListLIN_0_0/E_NOT_OK, DataServices_DID_F0BE_MasterNetworkConfigurationListLIN_DiagMasterNetworkConfigurationListLIN_0_0/E_PENDING]
        arg OpStatus: type=Dcm_OpStatusType, direction=IN
        arg Data: type=Dcm_Data1ByteType, direction=OUT
      operation ReadDataLength: possible-error=[DataServices_DID_F0BE_MasterNetworkConfigurationListLIN_DiagMasterNetworkConfigurationListLIN_0_0/E_NOT_OK, DataServices_DID_F0BE_MasterNetworkConfigurationListLIN_DiagMasterNetworkConfigurationListLIN_0_0/E_PENDING]
        arg OpStatus: type=Dcm_OpStatusType, direction=IN
        arg DataLength: type=uint16, direction=OUT
      operation WriteData: possible-error=[DataServices_DID_F0BE_MasterNetworkConfigurationListLIN_DiagMasterNetworkConfigurationListLIN_0_0/E_NOT_OK, DataServices_DID_F0BE_MasterNetworkConfigurationListLIN_DiagMasterNetworkConfigurationListLIN_0_0/E_PENDING]
        4 x arg:
          Data: type=Dcm_Data1ByteType, direction=IN
          DataLength: type=uint16, direction=IN
          OpStatus: type=Dcm_OpStatusType, direction=IN
          ErrorCode: type=Dcm_NegativeResponseCodeType, direction=OUT
      error E_NOT_OK: error-code=1
      error E_PENDING: error-code=10
    DataServices_DID_F1DD_GMSoftwareModuleIdentifierDataIdentifiers_GMSoftwareModuleIdentifierDataIdentifiers_0_0
      operation ReadData: possible-error=[DataServices_DID_F1DD_GMSoftwareModuleIdentifierDataIdentifiers_GMSoftwareModuleIdentifierDataIdentifiers_0_0/E_NOT_OK, DataServices_DID_F1DD_GMSoftwareModuleIdentifierDataIdentifiers_GMSoftwareModuleIdentifierDataIdentifiers_0_0/E_PENDING]
        arg OpStatus: type=Dcm_OpStatusType, direction=IN
        arg Data: type=Dcm_Data80ByteType, direction=OUT
      error E_NOT_OK: error-code=1
      error E_PENDING: error-code=10
    DcmIf
      4 x operation:
        DcmClearDTC: possible-error=[DEM_CLEAR_WRONG_DTC, DEM_CLEAR_WRONG_DTCORIGIN, DEM_CLEAR_FAILED, DEM_CLEAR_PENDING, DEM_CLEAR_BUSY, DEM_CLEAR_MEMORY_ERROR]
          arg DTC: type=uint32, direction=IN
          arg DTCFormat: type=Dem_DTCFormatType, direction=IN
          arg DTCOrigin: type=Dem_DTCOriginType, direction=IN
        DcmEnableDTCSetting: possible-error=[DEM_CONTROL_DTC_SETTING_N_OK, DEM_CONTROL_DTC_WRONG_DTCGROUP]
          arg DTCGroup: type=Dem_DTCGroupType, direction=IN
          arg DTCKind: type=Dem_DTCKindType, direction=IN
        DcmGetFreezeFrameDataByDTC: possible-error=[DEM_GET_FFDATABYDTC_WRONG_DTC, DEM_GET_FFDATABYDTC_WRONG_DTCORIGIN, DEM_GET_FFDATABYDTC_WRONG_RECORDNUMBER, DEM_GET_FFDATABYDTC_WRONG_BUFFERSIZE, DEM_GET_FFDATABYDTC_PENDING]
          5 x arg:
            DTC: type=uint32, direction=IN
            DTCOrigin: type=Dem_DTCOriginType, direction=IN
            RecordNumber: type=uint8, direction=IN
            DestBuffer: type=uint8, direction=OUT
            BufSize: type=uint16, direction=INOUT
        DcmGetExtendedDataRecordByDTC: possible-error=[DEM_RECORD_WRONG_DTC, DEM_RECORD_WRONG_DTCORIGIN, DEM_RECORD_WRONG_NUMBER, DEM_RECORD_WRONG_BUFFERSIZE, DEM_RECORD_PENDING]
          5 x arg:
            DTC: type=uint32, direction=IN
            DTCOrigin: type=Dem_DTCOriginType, direction=IN
            ExtendedDataNumber: type=uint8, direction=IN
            DestBuffer: type=uint8, direction=OUT
            BufSize: type=uint16, direction=INOUT
      18 x error:
        DEM_CLEAR_WRONG_DTC: error-code=1
        DEM_CONTROL_DTC_SETTING_N_OK: error-code=1
        DEM_CLEAR_WRONG_DTCORIGIN: error-code=2
        DEM_CONTROL_DTC_WRONG_DTCGROUP: error-code=2
        DEM_CLEAR_FAILED: error-code=3
        DEM_CLEAR_PENDING: error-code=4
        DEM_CLEAR_BUSY: error-code=5
        DEM_CLEAR_MEMORY_ERROR: error-code=6
        DEM_GET_FFDATABYDTC_WRONG_DTC: error-code=1
        DEM_GET_FFDATABYDTC_WRONG_DTCORIGIN: error-code=2
        DEM_GET_FFDATABYDTC_WRONG_RECORDNUMBER: error-code=3
        DEM_GET_FFDATABYDTC_WRONG_BUFFERSIZE: error-code=4
        DEM_GET_FFDATABYDTC_PENDING: error-code=5
        DEM_RECORD_WRONG_DTC: error-code=1
        DEM_RECORD_WRONG_DTCORIGIN: error-code=2
        DEM_RECORD_WRONG_NUMBER: error-code=3
        DEM_RECORD_WRONG_BUFFERSIZE: error-code=4
        DEM_RECORD_PENDING: error-code=5
package /MICROSAR/Dcm_swc/ComponentTypes
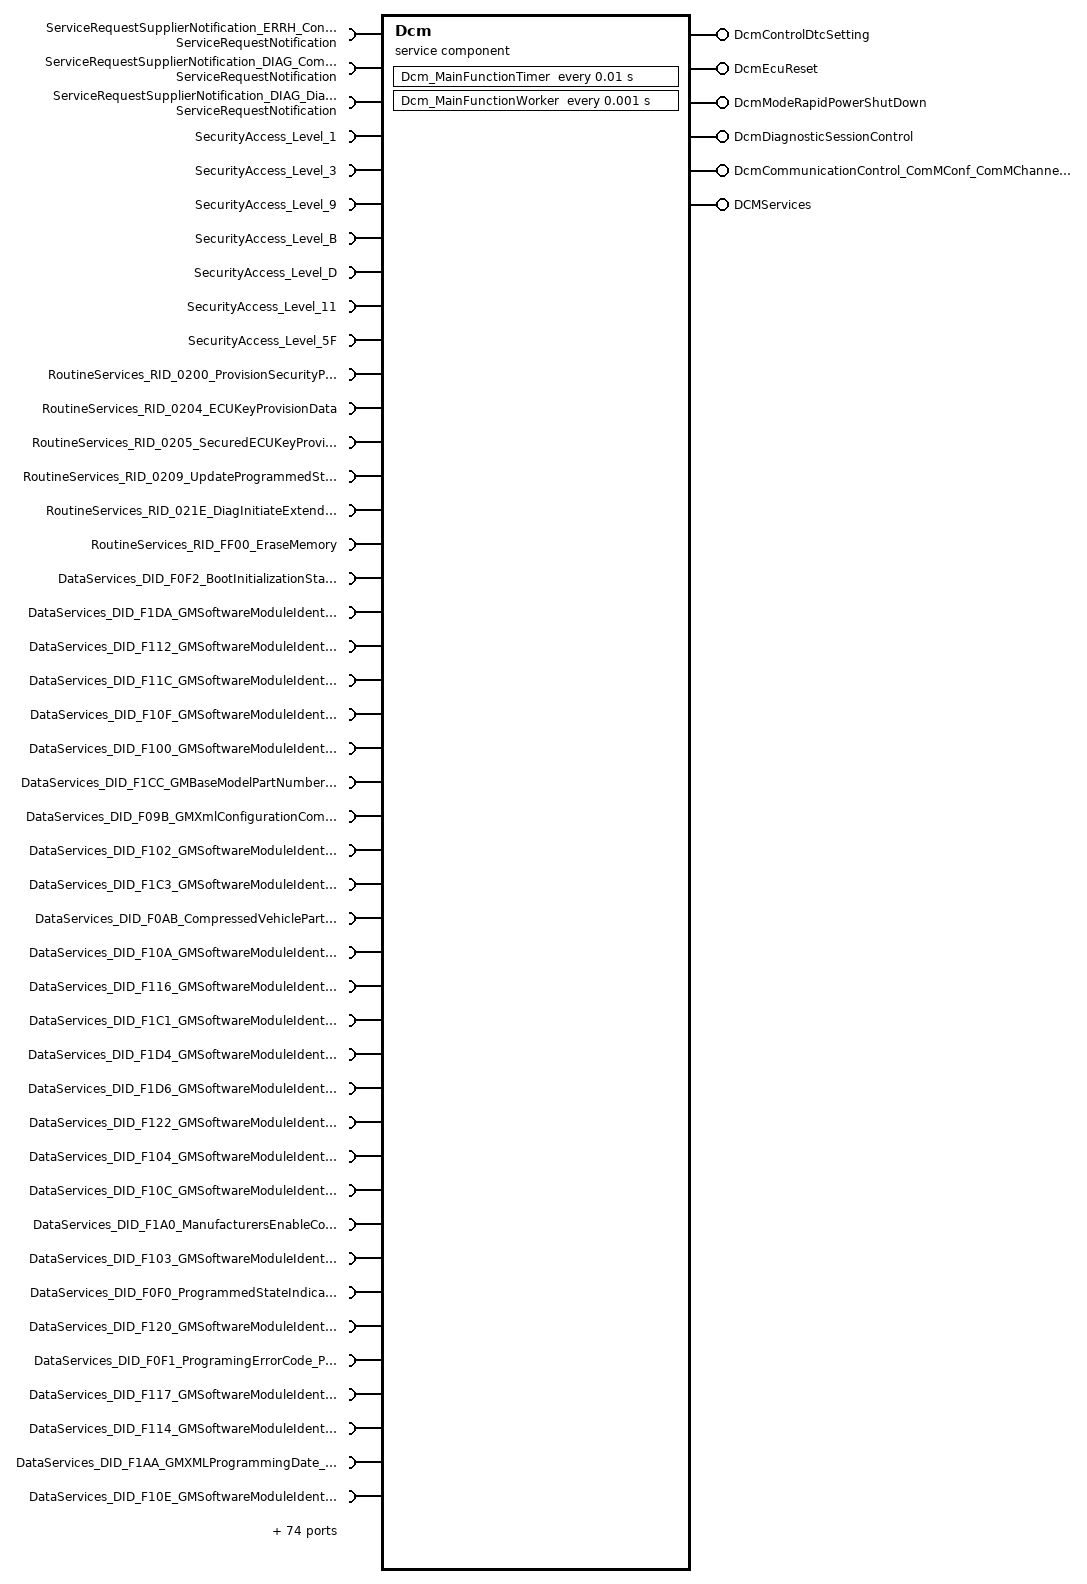
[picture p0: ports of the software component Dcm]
  service sw component type Dcm: category=SERVICE_COMPONENT
    6 x provide port:
      DcmControlDtcSetting: provided-interface=DcmControlDtcSetting
      DcmEcuReset: mode-switch-sender-com-spec{mode-group=DcmEcuReset, mode-switched-ack=timeout=0}, provided-interface=DcmEcuReset
      DcmModeRapidPowerShutDown: mode-switch-sender-com-spec{mode-group=DcmModeRapidPowerShutDown, mode-switched-ack=timeout=0}, provided-interface=DcmModeRapidPowerShutDown
      DcmDiagnosticSessionControl: provided-interface=DcmDiagnosticSessionControl
      DcmCommunicationControl_ComMConf_ComMChannel_CAN_5_Cluster_def1eb88: provided-interface=DcmCommunicationControl_ComMConf_ComMChannel_CAN_5_Cluster_def1eb88
      DCMServices: provided-interface=DCMServices
    118 x require port:
      ServiceRequestSupplierNotification_ERRH_ControlDTCSetting: required-interface=ServiceRequestNotification
      ServiceRequestSupplierNotification_DIAG_CommunicationControl: required-interface=ServiceRequestNotification
      ServiceRequestSupplierNotification_DIAG_DiagnosticSessionControl: required-interface=ServiceRequestNotification
      SecurityAccess_Level_1: required-interface=SecurityAccess_Level_1
      SecurityAccess_Level_3: required-interface=SecurityAccess_Level_3
      SecurityAccess_Level_9: required-interface=SecurityAccess_Level_9
      SecurityAccess_Level_B: required-interface=SecurityAccess_Level_B
      SecurityAccess_Level_D: required-interface=SecurityAccess_Level_D
      SecurityAccess_Level_11: required-interface=SecurityAccess_Level_11
      SecurityAccess_Level_5F: required-interface=SecurityAccess_Level_5F
      RoutineServices_RID_0200_ProvisionSecurityPeripheralGeneralKeys: required-interface=RoutineServices_RID_0200_ProvisionSecurityPeripheralGeneralKeys
      RoutineServices_RID_0204_ECUKeyProvisionData: required-interface=RoutineServices_RID_0204_ECUKeyProvisionData
      RoutineServices_RID_0205_SecuredECUKeyProvisionData: required-interface=RoutineServices_RID_0205_SecuredECUKeyProvisionData
      RoutineServices_RID_0209_UpdateProgrammedStateIndicatorForPartition: required-interface=RoutineServices_RID_0209_UpdateProgrammedStateIndicatorForPartition
      RoutineServices_RID_021E_DiagInitiateExtendedReflash: required-interface=RoutineServices_RID_021E_DiagInitiateExtendedReflash
      RoutineServices_RID_FF00_EraseMemory: required-interface=RoutineServices_RID_FF00_EraseMemory
      DataServices_DID_F0F2_BootInitializationStatus_BootInitializationStatus_0_0: required-interface=DataServices_DID_F0F2_BootInitializationStatus_BootInitializationStatus_0_0
      DataServices_DID_F1DA_GMSoftwareModuleIdentifierAlphaCode_10_GMSoftwareModuleIdentifierAlphaCode_10_0_0: required-interface=DataServices_DID_F1DA_GMSoftwareModuleIdentifierAlphaCode_10_GMSoftwareModuleIdentifierAlphaCode_10_0_0
      DataServices_DID_F112_GMSoftwareModuleIdentifier_20_GMSoftwareModuleIdentifier_20_0_0: required-interface=DataServices_DID_F112_GMSoftwareModuleIdentifier_20_GMSoftwareModuleIdentifier_20_0_0
      DataServices_DID_F11C_GMSoftwareModuleIdentifier_25_GMSoftwareModuleIdentifier_25_0_0: required-interface=DataServices_DID_F11C_GMSoftwareModuleIdentifier_25_GMSoftwareModuleIdentifier_25_0_0
      DataServices_DID_F10F_GMSoftwareModuleIdentifierAlphaCode_18_GMSoftwareModuleIdentifierAlphaCode_18_0_0: required-interface=DataServices_DID_F10F_GMSoftwareModuleIdentifierAlphaCode_18_GMSoftwareModuleIdentifierAlphaCode_18_0_0
      DataServices_DID_F100_GMSoftwareModuleIdentifier_11_GMSoftwareModuleIdentifier_11_0_0: required-interface=DataServices_DID_F100_GMSoftwareModuleIdentifier_11_GMSoftwareModuleIdentifier_11_0_0
      DataServices_DID_F1CC_GMBaseModelPartNumber_GMBaseModelPartNumber_0_0: required-interface=DataServices_DID_F1CC_GMBaseModelPartNumber_GMBaseModelPartNumber_0_0
      DataServices_DID_F09B_GMXmlConfigurationCompatibilityIdentifier_DiagXmlConfigurationCompatibilityIdentifier_0_0: required-interface=DataServices_DID_F09B_GMXmlConfigurationCompatibilityIdentifier_DiagXmlConfigurationCompatibilityIdentifier_0_0
      DataServices_DID_F102_GMSoftwareModuleIdentifier_12_GMSoftwareModuleIdentifier_12_0_0: required-interface=DataServices_DID_F102_GMSoftwareModuleIdentifier_12_GMSoftwareModuleIdentifier_12_0_0
      DataServices_DID_F1C3_GMSoftwareModuleIdentifier_03_GMSoftwareModuleIdentifier_03_0_0: required-interface=DataServices_DID_F1C3_GMSoftwareModuleIdentifier_03_GMSoftwareModuleIdentifier_03_0_0
      DataServices_DID_F0AB_CompressedVehiclePartitioningAndProductStructure_DiagCompressedVehiclePartitioningAndProductStructure_0_0: required-interface=DataServices_DID_F0AB_CompressedVehiclePartitioningAndProductStructure_DiagCompressedVehiclePartitioningAndProductStructure_0_0
      DataServices_DID_F10A_GMSoftwareModuleIdentifier_16_GMSoftwareModuleIdentifier_16_0_0: required-interface=DataServices_DID_F10A_GMSoftwareModuleIdentifier_16_GMSoftwareModuleIdentifier_16_0_0
      DataServices_DID_F116_GMSoftwareModuleIdentifier_22_GMSoftwareModuleIdentifier_22_0_0: required-interface=DataServices_DID_F116_GMSoftwareModuleIdentifier_22_GMSoftwareModuleIdentifier_22_0_0
      DataServices_DID_F1C1_GMSoftwareModuleIdentifier_01_GMSoftwareModuleIdentifier_01_0_0: required-interface=DataServices_DID_F1C1_GMSoftwareModuleIdentifier_01_GMSoftwareModuleIdentifier_01_0_0
      DataServices_DID_F1D4_GMSoftwareModuleIdentifierAlphaCode_04_GMSoftwareModuleIdentifierAlphaCode_04_0_0: required-interface=DataServices_DID_F1D4_GMSoftwareModuleIdentifierAlphaCode_04_GMSoftwareModuleIdentifierAlphaCode_04_0_0
      DataServices_DID_F1D6_GMSoftwareModuleIdentifierAlphaCode_06_GMSoftwareModuleIdentifierAlphaCode_06_0_0: required-interface=DataServices_DID_F1D6_GMSoftwareModuleIdentifierAlphaCode_06_GMSoftwareModuleIdentifierAlphaCode_06_0_0
      DataServices_DID_F122_GMSoftwareModuleIdentifier_28_GMSoftwareModuleIdentifier_28_0_0: required-interface=DataServices_DID_F122_GMSoftwareModuleIdentifier_28_GMSoftwareModuleIdentifier_28_0_0
      DataServices_DID_F104_GMSoftwareModuleIdentifier_13_GMSoftwareModuleIdentifier_13_0_0: required-interface=DataServices_DID_F104_GMSoftwareModuleIdentifier_13_GMSoftwareModuleIdentifier_13_0_0
      DataServices_DID_F10C_GMSoftwareModuleIdentifier_17_GMSoftwareModuleIdentifier_17_0_0: required-interface=DataServices_DID_F10C_GMSoftwareModuleIdentifier_17_GMSoftwareModuleIdentifier_17_0_0
      DataServices_DID_F1A0_ManufacturersEnableCounter_ManufacturersEnableCounter_0_0: required-interface=DataServices_DID_F1A0_ManufacturersEnableCounter_ManufacturersEnableCounter_0_0
      DataServices_DID_F103_GMSoftwareModuleIdentifierAlphaCode_12_GMSoftwareModuleIdentifierAlphaCode_12_0_0: required-interface=DataServices_DID_F103_GMSoftwareModuleIdentifierAlphaCode_12_GMSoftwareModuleIdentifierAlphaCode_12_0_0
      DataServices_DID_F0F0_ProgrammedStateIndicator_ProgrammedStateIndicator_0_0: required-interface=DataServices_DID_F0F0_ProgrammedStateIndicator_ProgrammedStateIndicator_0_0
      DataServices_DID_F120_GMSoftwareModuleIdentifier_27_GMSoftwareModuleIdentifier_27_0_0: required-interface=DataServices_DID_F120_GMSoftwareModuleIdentifier_27_GMSoftwareModuleIdentifier_27_0_0
      DataServices_DID_F0F1_ProgramingErrorCode_ProgramingErrorCode_0_0: required-interface=DataServices_DID_F0F1_ProgramingErrorCode_ProgramingErrorCode_0_0
      DataServices_DID_F117_GMSoftwareModuleIdentifierAlphaCode_22_GMSoftwareModuleIdentifierAlphaCode_22_0_0: required-interface=DataServices_DID_F117_GMSoftwareModuleIdentifierAlphaCode_22_GMSoftwareModuleIdentifierAlphaCode_22_0_0
      DataServices_DID_F114_GMSoftwareModuleIdentifier_21_GMSoftwareModuleIdentifier_21_0_0: required-interface=DataServices_DID_F114_GMSoftwareModuleIdentifier_21_GMSoftwareModuleIdentifier_21_0_0
      DataServices_DID_F1AA_GMXMLProgrammingDate_DiagXMLProgrammingDate_0_0: required-interface=DataServices_DID_F1AA_GMXMLProgrammingDate_DiagXMLProgrammingDate_0_0
      DataServices_DID_F10E_GMSoftwareModuleIdentifier_18_GMSoftwareModuleIdentifier_18_0_0: required-interface=DataServices_DID_F10E_GMSoftwareModuleIdentifier_18_GMSoftwareModuleIdentifier_18_0_0
      DataServices_DID_F1C6_GMSoftwareModuleIdentifier_06_GMSoftwareModuleIdentifier_06_0_0: required-interface=DataServices_DID_F1C6_GMSoftwareModuleIdentifier_06_GMSoftwareModuleIdentifier_06_0_0
      DataServices_DID_F105_GMSoftwareModuleIdentifierAlphaCode_13_GMSoftwareModuleIdentifierAlphaCode_13_0_0: required-interface=DataServices_DID_F105_GMSoftwareModuleIdentifierAlphaCode_13_GMSoftwareModuleIdentifierAlphaCode_13_0_0
      DataServices_DID_F09D_GMXmlDataFileAlphaCode_DiagGMXmlDataFileAlphaCode_0_0: required-interface=DataServices_DID_F09D_GMXmlDataFileAlphaCode_DiagGMXmlDataFileAlphaCode_0_0
      DataServices_DID_F1C0_GMBootSoftwarePartNumber_GMBootSoftwarePartNumber_0_0: required-interface=DataServices_DID_F1C0_GMBootSoftwarePartNumber_GMBootSoftwarePartNumber_0_0
      DataServices_DID_F107_GMSoftwareModuleIdentifierAlphaCode_14_GMSoftwareModuleIdentifierAlphaCode_14_0_0: required-interface=DataServices_DID_F107_GMSoftwareModuleIdentifierAlphaCode_14_GMSoftwareModuleIdentifierAlphaCode_14_0_0
      DataServices_DID_F199_ProgrammingDate_DiagProgrammingDate_0_0: required-interface=DataServices_DID_F199_ProgrammingDate_DiagProgrammingDate_0_0
      DataServices_DID_F1DB_GMEndModelPartNumberAlphaCode_GMEndModelPartNumberAlphaCode_0_0: required-interface=DataServices_DID_F1DB_GMEndModelPartNumberAlphaCode_GMEndModelPartNumberAlphaCode_0_0
      DataServices_DID_F0F4_SignatureBypassAuthorizationTicket_SignatureBypassAuthorizationTicket_0_0: required-interface=DataServices_DID_F0F4_SignatureBypassAuthorizationTicket_SignatureBypassAuthorizationTicket_0_0
      DataServices_DID_F11A_GMSoftwareModuleIdentifier_24_GMSoftwareModuleIdentifier_24_0_0: required-interface=DataServices_DID_F11A_GMSoftwareModuleIdentifier_24_GMSoftwareModuleIdentifier_24_0_0
      DataServices_DID_F101_GMSoftwareModuleIdentifierAlphaCode_11_GMSoftwareModuleIdentifierAlphaCode_11_0_0: required-interface=DataServices_DID_F101_GMSoftwareModuleIdentifierAlphaCode_11_GMSoftwareModuleIdentifierAlphaCode_11_0_0
      DataServices_DID_F2A0_ReadMemoryEnableCounter_DiagReadMemoryEnableCounter_0_0: required-interface=DataServices_DID_F2A0_ReadMemoryEnableCounter_DiagReadMemoryEnableCounter_0_0
      DataServices_DID_F1CB_GMEndModelPartNumber_GMEndModelPartNumber_0_0: required-interface=DataServices_DID_F1CB_GMEndModelPartNumber_GMEndModelPartNumber_0_0
      DataServices_DID_F1A9_GMXMLRepairShopCodeOrTesterSerialNumber_DiagXMLRepairShopCodeOrTesterSerialNumber_0_0: required-interface=DataServices_DID_F1A9_GMXMLRepairShopCodeOrTesterSerialNumber_DiagXMLRepairShopCodeOrTesterSerialNumber_0_0
      DataServices_DID_F080_ECUKeyProvisionStateFlag_ECUKeyProvisionStateFlag_0_0: required-interface=DataServices_DID_F080_ECUKeyProvisionStateFlag_ECUKeyProvisionStateFlag_0_0
      DataServices_DID_F1D3_GMSoftwareModuleIdentifierAlphaCode_03_GMSoftwareModuleIdentifierAlphaCode_03_0_0: required-interface=DataServices_DID_F1D3_GMSoftwareModuleIdentifierAlphaCode_03_GMSoftwareModuleIdentifierAlphaCode_03_0_0
      DataServices_DID_F1DC_GMBaseModelPartNumberAlphaCode_GMBaseModelPartNumberAlphaCode_0_0: required-interface=DataServices_DID_F1DC_GMBaseModelPartNumberAlphaCode_GMBaseModelPartNumberAlphaCode_0_0
      DataServices_DID_F106_GMSoftwareModuleIdentifier_14_GMSoftwareModuleIdentifier_14_0_0: required-interface=DataServices_DID_F106_GMSoftwareModuleIdentifier_14_GMSoftwareModuleIdentifier_14_0_0
      DataServices_DID_F113_GMSoftwareModuleIdentifierAlphaCode_20_GMSoftwareModuleIdentifierAlphaCode_20_0_0: required-interface=DataServices_DID_F113_GMSoftwareModuleIdentifierAlphaCode_20_GMSoftwareModuleIdentifierAlphaCode_20_0_0
      DataServices_DID_F109_GMSoftwareModuleIdentifierAlphaCode_15_GMSoftwareModuleIdentifierAlphaCode_15_0_0: required-interface=DataServices_DID_F109_GMSoftwareModuleIdentifierAlphaCode_15_GMSoftwareModuleIdentifierAlphaCode_15_0_0
      DataServices_DID_F1D1_GMSoftwareModuleIdentifierAlphaCode_01_GMSoftwareModuleIdentifierAlphaCode_01_0_0: required-interface=DataServices_DID_F1D1_GMSoftwareModuleIdentifierAlphaCode_01_GMSoftwareModuleIdentifierAlphaCode_01_0_0
      DataServices_DID_F0F6_BootInfoBlockSubjectNameandECUName_SubjectName_0_0: required-interface=DataServices_DID_F0F6_BootInfoBlockSubjectNameandECUName_SubjectName_0_0
      DataServices_DID_F0F6_BootInfoBlockSubjectNameandECUName_ECUName_16_0: required-interface=DataServices_DID_F0F6_BootInfoBlockSubjectNameandECUName_ECUName_16_0
      DataServices_DID_F084_MessageAuthenticationAntiReplayCounters_MessageAuthenticationAntiReplayCounters_0_0: required-interface=DataServices_DID_F084_MessageAuthenticationAntiReplayCounters_MessageAuthenticationAntiReplayCounters_0_0
      DataServices_DID_F108_GMSoftwareModuleIdentifier_15_GMSoftwareModuleIdentifier_15_0_0: required-interface=DataServices_DID_F108_GMSoftwareModuleIdentifier_15_GMSoftwareModuleIdentifier_15_0_0
      DataServices_DID_F10D_GMSoftwareModuleIdentifierAlphaCode_17_GMSoftwareModuleIdentifierAlphaCode_17_0_0: required-interface=DataServices_DID_F10D_GMSoftwareModuleIdentifierAlphaCode_17_GMSoftwareModuleIdentifierAlphaCode_17_0_0
      DataServices_DID_F11B_GMSoftwareModuleIdentifierAlphaCode_24_GMSoftwareModuleIdentifierAlphaCode_24_0_0: required-interface=DataServices_DID_F11B_GMSoftwareModuleIdentifierAlphaCode_24_GMSoftwareModuleIdentifierAlphaCode_24_0_0
      DataServices_DID_F1CA_GMSoftwareModuleIdentifier_10_GMSoftwareModuleIdentifier_10_0_0: required-interface=DataServices_DID_F1CA_GMSoftwareModuleIdentifier_10_GMSoftwareModuleIdentifier_10_0_0
      DataServices_DID_F1C5_GMSoftwareModuleIdentifier_05_GMSoftwareModuleIdentifier_05_0_0: required-interface=DataServices_DID_F1C5_GMSoftwareModuleIdentifier_05_GMSoftwareModuleIdentifier_05_0_0
      DataServices_DID_F1B0_ECUDiagnosticAddress_ECUDiagnosticAddress_0_0: required-interface=DataServices_DID_F1B0_ECUDiagnosticAddress_ECUDiagnosticAddress_0_0
      DataServices_DID_F11D_GMSoftwareModuleIdentifierAlphaCode_25_GMSoftwareModuleIdentifierAlphaCode_25_0_0: required-interface=DataServices_DID_F11D_GMSoftwareModuleIdentifierAlphaCode_25_GMSoftwareModuleIdentifierAlphaCode_25_0_0
      DataServices_DID_F081_ECUKeyConfigurationData_ECUKeyConfigurationData_0_0: required-interface=DataServices_DID_F081_ECUKeyConfigurationData_ECUKeyConfigurationData_0_0
      DataServices_DID_F1D7_GMSoftwareModuleIdentifierAlphaCode_07_GMSoftwareModuleIdentifierAlphaCode_07_0_0: required-interface=DataServices_DID_F1D7_GMSoftwareModuleIdentifierAlphaCode_07_GMSoftwareModuleIdentifierAlphaCode_07_0_0
      DataServices_DID_F09A_DiagnosticDataIdentifier_DiagSystemCode_0_0: required-interface=DataServices_DID_F09A_DiagnosticDataIdentifier_DiagSystemCode_0_0
      DataServices_DID_F09A_DiagnosticDataIdentifier_DiagDiagnosticDataStreamVersionNumber_1_0: required-interface=DataServices_DID_F09A_DiagnosticDataIdentifier_DiagDiagnosticDataStreamVersionNumber_1_0
      DataServices_DID_F11E_GMSoftwareModuleIdentifier_26_GMSoftwareModuleIdentifier_26_0_0: required-interface=DataServices_DID_F11E_GMSoftwareModuleIdentifier_26_GMSoftwareModuleIdentifier_26_0_0
      DataServices_DID_F1C8_GMSoftwareModuleIdentifier_08_GMSoftwareModuleIdentifier_08_0_0: required-interface=DataServices_DID_F1C8_GMSoftwareModuleIdentifier_08_GMSoftwareModuleIdentifier_08_0_0
      DataServices_DID_F118_GMSoftwareModuleIdentifier_23_GMSoftwareModuleIdentifier_23_0_0: required-interface=DataServices_DID_F118_GMSoftwareModuleIdentifier_23_GMSoftwareModuleIdentifier_23_0_0
      DataServices_DID_F1C9_GMSoftwareModuleIdentifier_09_GMSoftwareModuleIdentifier_09_0_0: required-interface=DataServices_DID_F1C9_GMSoftwareModuleIdentifier_09_GMSoftwareModuleIdentifier_09_0_0
      DataServices_DID_F125_GMSoftwareModuleIdentifierAlphaCode_29_GMSoftwareModuleIdentifierAlphaCode_29_0_0: required-interface=DataServices_DID_F125_GMSoftwareModuleIdentifierAlphaCode_29_GMSoftwareModuleIdentifierAlphaCode_29_0_0
      DataServices_DID_F0F3_ECUID_ECUID_0_0: required-interface=DataServices_DID_F0F3_ECUID_ECUID_0_0
      DataServices_DID_F115_GMSoftwareModuleIdentifierAlphaCode_21_GMSoftwareModuleIdentifierAlphaCode_21_0_0: required-interface=DataServices_DID_F115_GMSoftwareModuleIdentifierAlphaCode_21_GMSoftwareModuleIdentifierAlphaCode_21_0_0
      DataServices_DID_F123_GMSoftwareModuleIdentifierAlphaCode_28_GMSoftwareModuleIdentifierAlphaCode_28_0_0: required-interface=DataServices_DID_F123_GMSoftwareModuleIdentifierAlphaCode_28_GMSoftwareModuleIdentifierAlphaCode_28_0_0
      DataServices_DID_F1D2_GMSoftwareModuleIdentifierAlphaCode_02_GMSoftwareModuleIdentifierAlphaCode_02_0_0: required-interface=DataServices_DID_F1D2_GMSoftwareModuleIdentifierAlphaCode_02_GMSoftwareModuleIdentifierAlphaCode_02_0_0
      DataServices_DID_F1C4_GMSoftwareModuleIdentifier_04_GMSoftwareModuleIdentifier_04_0_0: required-interface=DataServices_DID_F1C4_GMSoftwareModuleIdentifier_04_GMSoftwareModuleIdentifier_04_0_0
      DataServices_DID_F1C2_GMSoftwareModuleIdentifier_02_GMSoftwareModuleIdentifier_02_0_0: required-interface=DataServices_DID_F1C2_GMSoftwareModuleIdentifier_02_GMSoftwareModuleIdentifier_02_0_0
      DataServices_DID_F083_MessageAuthenticationCalibrationFilePartNumber_MessageAuthenticationCalibrationFilePartNumber_0_0: required-interface=DataServices_DID_F083_MessageAuthenticationCalibrationFilePartNumber_MessageAuthenticationCalibrationFilePartNumber_0_0
      DataServices_DID_F110_GMSoftwareModuleIdentifier_19_GMSoftwareModuleIdentifier_19_0_0: required-interface=DataServices_DID_F110_GMSoftwareModuleIdentifier_19_GMSoftwareModuleIdentifier_19_0_0
      DataServices_DID_F124_GMSoftwareModuleIdentifier_29_GMSoftwareModuleIdentifier_29_0_0: required-interface=DataServices_DID_F124_GMSoftwareModuleIdentifier_29_GMSoftwareModuleIdentifier_29_0_0
      DataServices_DID_F119_GMSoftwareModuleIdentifierAlphaCode_23_GMSoftwareModuleIdentifierAlphaCode_23_0_0: required-interface=DataServices_DID_F119_GMSoftwareModuleIdentifierAlphaCode_23_GMSoftwareModuleIdentifierAlphaCode_23_0_0
      DataServices_DID_F1D8_GMSoftwareModuleIdentifierAlphaCode_08_GMSoftwareModuleIdentifierAlphaCode_08_0_0: required-interface=DataServices_DID_F1D8_GMSoftwareModuleIdentifierAlphaCode_08_GMSoftwareModuleIdentifierAlphaCode_08_0_0
      DataServices_DID_F129_TotalVehicleOperationTime_DataRecord: required-interface=DataServices_DID_F129_TotalVehicleOperationTime_DataRecord
      DataServices_DID_F1D9_GMSoftwareModuleIdentifierAlphaCode_09_GMSoftwareModuleIdentifierAlphaCode_09_0_0: required-interface=DataServices_DID_F1D9_GMSoftwareModuleIdentifierAlphaCode_09_GMSoftwareModuleIdentifierAlphaCode_09_0_0
      DataServices_DID_F126_GMSoftwareModuleIdentifier_30_GMSoftwareModuleIdentifier_30_0_0: required-interface=DataServices_DID_F126_GMSoftwareModuleIdentifier_30_GMSoftwareModuleIdentifier_30_0_0
      DataServices_DID_F190_VehicleIdentificationNumber_VehicleIdentificationNumber_0_0: required-interface=DataServices_DID_F190_VehicleIdentificationNumber_VehicleIdentificationNumber_0_0
      DataServices_DID_F1C7_GMSoftwareModuleIdentifier_07_GMSoftwareModuleIdentifier_07_0_0: required-interface=DataServices_DID_F1C7_GMSoftwareModuleIdentifier_07_GMSoftwareModuleIdentifier_07_0_0
      DataServices_DID_F0B3_DataUniversalNumberingSystemIdentification_DiagDataUniversalNumberingSystemIdentification_0_0: required-interface=DataServices_DID_F0B3_DataUniversalNumberingSystemIdentification_DiagDataUniversalNumberingSystemIdentification_0_0
      DataServices_DID_F11F_GMSoftwareModuleIdentifierAlphaCode_26_GMSoftwareModuleIdentifierAlphaCode_26_0_0: required-interface=DataServices_DID_F11F_GMSoftwareModuleIdentifierAlphaCode_26_GMSoftwareModuleIdentifierAlphaCode_26_0_0
      DataServices_DID_F10B_GMSoftwareModuleIdentifierAlphaCode_16_GMSoftwareModuleIdentifierAlphaCode_16_0_0: required-interface=DataServices_DID_F10B_GMSoftwareModuleIdentifierAlphaCode_16_GMSoftwareModuleIdentifierAlphaCode_16_0_0
      DataServices_DID_F1D0_GMBootSoftwarePartNumberAlphaCode_GMBootSoftwarePartNumberAlphaCode_0_0: required-interface=DataServices_DID_F1D0_GMBootSoftwarePartNumberAlphaCode_GMBootSoftwarePartNumberAlphaCode_0_0
      DataServices_DID_F1D5_GMSoftwareModuleIdentifierAlphaCode_05_GMSoftwareModuleIdentifierAlphaCode_05_0_0: required-interface=DataServices_DID_F1D5_GMSoftwareModuleIdentifierAlphaCode_05_GMSoftwareModuleIdentifierAlphaCode_05_0_0
      DataServices_DID_F111_GMSoftwareModuleIdentifierAlphaCode_19_GMSoftwareModuleIdentifierAlphaCode_19_0_0: required-interface=DataServices_DID_F111_GMSoftwareModuleIdentifierAlphaCode_19_GMSoftwareModuleIdentifierAlphaCode_19_0_0
      DataServices_DID_F180_BootSoftwareIdentificationDataIdentifier_BootSoftwareIdentificationDataIdentifier_0_0: required-interface=DataServices_DID_F180_BootSoftwareIdentificationDataIdentifier_BootSoftwareIdentificationDataIdentifier_0_0
      DataServices_DID_F127_GMSoftwareModuleIdentifierAlphaCode_30_GMSoftwareModuleIdentifierAlphaCode_30_0_0: required-interface=DataServices_DID_F127_GMSoftwareModuleIdentifierAlphaCode_30_GMSoftwareModuleIdentifierAlphaCode_30_0_0
      DataServices_DID_F198_RepairShopCodeOrTesterSerialNumber_DiagRepairShopCodeOrTesterSerialNumber_0_0: required-interface=DataServices_DID_F198_RepairShopCodeOrTesterSerialNumber_DiagRepairShopCodeOrTesterSerialNumber_0_0
      DataServices_DID_F121_GMSoftwareModuleIdentifierAlphaCode_27_GMSoftwareModuleIdentifierAlphaCode_27_0_0: required-interface=DataServices_DID_F121_GMSoftwareModuleIdentifierAlphaCode_27_GMSoftwareModuleIdentifierAlphaCode_27_0_0
      DataServices_DID_F09C_GMXmlDataFilePartNumber_DiagGMXmlDataFilePartNumber_0_0: required-interface=DataServices_DID_F09C_GMXmlDataFilePartNumber_DiagGMXmlDataFilePartNumber_0_0
      DataServices_DID_F0B4_ManufacturingTraceabilityCharacters_DiagYear_2_0: required-interface=DataServices_DID_F0B4_ManufacturingTraceabilityCharacters_DiagYear_2_0
      DataServices_DID_F0B4_ManufacturingTraceabilityCharacters_DiagTraceabilityNumber_7_0: required-interface=DataServices_DID_F0B4_ManufacturingTraceabilityCharacters_DiagTraceabilityNumber_7_0
      DataServices_DID_F0B4_ManufacturingTraceabilityCharacters_DiagShift_1_0: required-interface=DataServices_DID_F0B4_ManufacturingTraceabilityCharacters_DiagShift_1_0
      DataServices_DID_F0B4_ManufacturingTraceabilityCharacters_DiagLine_0_0: required-interface=DataServices_DID_F0B4_ManufacturingTraceabilityCharacters_DiagLine_0_0
      DataServices_DID_F0B4_ManufacturingTraceabilityCharacters_DiagDayOfTheYear_4_0: required-interface=DataServices_DID_F0B4_ManufacturingTraceabilityCharacters_DiagDayOfTheYear_4_0
      DataServices_DID_F0BE_MasterNetworkConfigurationListLIN_DiagMasterNetworkConfigurationListLIN_0_0: required-interface=DataServices_DID_F0BE_MasterNetworkConfigurationListLIN_DiagMasterNetworkConfigurationListLIN_0_0
      DataServices_DID_F1DD_GMSoftwareModuleIdentifierDataIdentifiers_GMSoftwareModuleIdentifierDataIdentifiers_0_0: required-interface=DataServices_DID_F1DD_GMSoftwareModuleIdentifierDataIdentifiers_GMSoftwareModuleIdentifierDataIdentifiers_0_0
      Dcm: required-interface=DcmIf
    behavior DcmInternalBehavior: handle-termination-and-restart=NO-SUPPORT, included-data-type-set=data-type=[Dcm_ConfirmationStatusType, Dcm_OpStatusType, Dcm_NegativeResponseCodeType, Dcm_ProtocolType, Dcm_SecLevelType, Dcm_SesCtrlType, Dcm_ControlDtcSettingType, Dcm_EcuResetType, Dcm_ModeRapidPowerShutDownType, Dcm_DiagnosticSessionControlType, Dcm_CommunicationModeType]
      timing event Timer_Dcm_MainFunctionTimer: start-on-event=Dcm_MainFunctionTimer, period=0.01
      timing event Timer_Dcm_MainFunctionWorker: start-on-event=Dcm_MainFunctionWorker, period=0.001
      4 x operation invoked event:
        OpEventGetActiveProtocol_GetActiveProtocol_DCMServices: start-on-event=GetActiveProtocol, operation=DCMServices.GetActiveProtocol
        OpEventGetSesCtrlType_GetSesCtrlType_DCMServices: start-on-event=GetSesCtrlType, operation=DCMServices.GetSesCtrlType
        OpEventResetToDefaultSession_ResetToDefaultSession_DCMServices: start-on-event=ResetToDefaultSession, operation=DCMServices.ResetToDefaultSession
        OpEventGetSecurityLevel_GetSecurityLevel_DCMServices: start-on-event=GetSecurityLevel, operation=DCMServices.GetSecurityLevel
      port-api-options:
        enable-take-address=true, indirect-api=false, port=DcmControlDtcSetting
        enable-take-address=true, indirect-api=false, port=DcmEcuReset
        enable-take-address=true, indirect-api=false, port=DcmModeRapidPowerShutDown
        enable-take-address=true, indirect-api=false, port=DcmDiagnosticSessionControl
        enable-take-address=true, indirect-api=false, port=DcmCommunicationControl_ComMConf_ComMChannel_CAN_5_Cluster_def1eb88
        enable-take-address=true, indirect-api=false, port=DCMServices
        enable-take-address=true, indirect-api=false, port=ServiceRequestSupplierNotification_ERRH_ControlDTCSetting
        enable-take-address=true, indirect-api=false, port=ServiceRequestSupplierNotification_DIAG_CommunicationControl
        enable-take-address=true, indirect-api=false, port=ServiceRequestSupplierNotification_DIAG_DiagnosticSessionControl
        enable-take-address=true, indirect-api=false, port=SecurityAccess_Level_1
        enable-take-address=true, indirect-api=false, port=SecurityAccess_Level_3
        enable-take-address=true, indirect-api=false, port=SecurityAccess_Level_9
        enable-take-address=true, indirect-api=false, port=SecurityAccess_Level_B
        enable-take-address=true, indirect-api=false, port=SecurityAccess_Level_D
        enable-take-address=true, indirect-api=false, port=SecurityAccess_Level_11
        enable-take-address=true, indirect-api=false, port=SecurityAccess_Level_5F
        enable-take-address=true, indirect-api=false, port=RoutineServices_RID_0200_ProvisionSecurityPeripheralGeneralKeys
        enable-take-address=true, indirect-api=false, port=RoutineServices_RID_0204_ECUKeyProvisionData
        enable-take-address=true, indirect-api=false, port=RoutineServices_RID_0205_SecuredECUKeyProvisionData
        enable-take-address=true, indirect-api=false, port=RoutineServices_RID_0209_UpdateProgrammedStateIndicatorForPartition
        enable-take-address=true, indirect-api=false, port=RoutineServices_RID_021E_DiagInitiateExtendedReflash
        enable-take-address=true, indirect-api=false, port=RoutineServices_RID_FF00_EraseMemory
        enable-take-address=true, indirect-api=false, port=DataServices_DID_F0F2_BootInitializationStatus_BootInitializationStatus_0_0
        enable-take-address=true, indirect-api=false, port=DataServices_DID_F1DA_GMSoftwareModuleIdentifierAlphaCode_10_GMSoftwareModuleIdentifierAlphaCode_10_0_0
        enable-take-address=true, indirect-api=false, port=DataServices_DID_F112_GMSoftwareModuleIdentifier_20_GMSoftwareModuleIdentifier_20_0_0
        enable-take-address=true, indirect-api=false, port=DataServices_DID_F11C_GMSoftwareModuleIdentifier_25_GMSoftwareModuleIdentifier_25_0_0
        enable-take-address=true, indirect-api=false, port=DataServices_DID_F10F_GMSoftwareModuleIdentifierAlphaCode_18_GMSoftwareModuleIdentifierAlphaCode_18_0_0
        enable-take-address=true, indirect-api=false, port=DataServices_DID_F100_GMSoftwareModuleIdentifier_11_GMSoftwareModuleIdentifier_11_0_0
        enable-take-address=true, indirect-api=false, port=DataServices_DID_F1CC_GMBaseModelPartNumber_GMBaseModelPartNumber_0_0
        enable-take-address=true, indirect-api=false, port=DataServices_DID_F09B_GMXmlConfigurationCompatibilityIdentifier_DiagXmlConfigurationCompatibilityIdentifier_0_0
        enable-take-address=true, indirect-api=false, port=DataServices_DID_F102_GMSoftwareModuleIdentifier_12_GMSoftwareModuleIdentifier_12_0_0
        enable-take-address=true, indirect-api=false, port=DataServices_DID_F1C3_GMSoftwareModuleIdentifier_03_GMSoftwareModuleIdentifier_03_0_0
        enable-take-address=true, indirect-api=false, port=DataServices_DID_F0AB_CompressedVehiclePartitioningAndProductStructure_DiagCompressedVehiclePartitioningAndProductStructure_0_0
        enable-take-address=true, indirect-api=false, port=DataServices_DID_F10A_GMSoftwareModuleIdentifier_16_GMSoftwareModuleIdentifier_16_0_0
        enable-take-address=true, indirect-api=false, port=DataServices_DID_F116_GMSoftwareModuleIdentifier_22_GMSoftwareModuleIdentifier_22_0_0
        enable-take-address=true, indirect-api=false, port=DataServices_DID_F1C1_GMSoftwareModuleIdentifier_01_GMSoftwareModuleIdentifier_01_0_0
        enable-take-address=true, indirect-api=false, port=DataServices_DID_F1D4_GMSoftwareModuleIdentifierAlphaCode_04_GMSoftwareModuleIdentifierAlphaCode_04_0_0
        enable-take-address=true, indirect-api=false, port=DataServices_DID_F1D6_GMSoftwareModuleIdentifierAlphaCode_06_GMSoftwareModuleIdentifierAlphaCode_06_0_0
        enable-take-address=true, indirect-api=false, port=DataServices_DID_F122_GMSoftwareModuleIdentifier_28_GMSoftwareModuleIdentifier_28_0_0
        enable-take-address=true, indirect-api=false, port=DataServices_DID_F104_GMSoftwareModuleIdentifier_13_GMSoftwareModuleIdentifier_13_0_0
        enable-take-address=true, indirect-api=false, port=DataServices_DID_F10C_GMSoftwareModuleIdentifier_17_GMSoftwareModuleIdentifier_17_0_0
        enable-take-address=true, indirect-api=false, port=DataServices_DID_F1A0_ManufacturersEnableCounter_ManufacturersEnableCounter_0_0
        enable-take-address=true, indirect-api=false, port=DataServices_DID_F103_GMSoftwareModuleIdentifierAlphaCode_12_GMSoftwareModuleIdentifierAlphaCode_12_0_0
        enable-take-address=true, indirect-api=false, port=DataServices_DID_F0F0_ProgrammedStateIndicator_ProgrammedStateIndicator_0_0
        enable-take-address=true, indirect-api=false, port=DataServices_DID_F120_GMSoftwareModuleIdentifier_27_GMSoftwareModuleIdentifier_27_0_0
        enable-take-address=true, indirect-api=false, port=DataServices_DID_F0F1_ProgramingErrorCode_ProgramingErrorCode_0_0
        enable-take-address=true, indirect-api=false, port=DataServices_DID_F117_GMSoftwareModuleIdentifierAlphaCode_22_GMSoftwareModuleIdentifierAlphaCode_22_0_0
        enable-take-address=true, indirect-api=false, port=DataServices_DID_F114_GMSoftwareModuleIdentifier_21_GMSoftwareModuleIdentifier_21_0_0
        enable-take-address=true, indirect-api=false, port=DataServices_DID_F1AA_GMXMLProgrammingDate_DiagXMLProgrammingDate_0_0
        enable-take-address=true, indirect-api=false, port=DataServices_DID_F10E_GMSoftwareModuleIdentifier_18_GMSoftwareModuleIdentifier_18_0_0
        enable-take-address=true, indirect-api=false, port=DataServices_DID_F1C6_GMSoftwareModuleIdentifier_06_GMSoftwareModuleIdentifier_06_0_0
        enable-take-address=true, indirect-api=false, port=DataServices_DID_F105_GMSoftwareModuleIdentifierAlphaCode_13_GMSoftwareModuleIdentifierAlphaCode_13_0_0
        enable-take-address=true, indirect-api=false, port=DataServices_DID_F09D_GMXmlDataFileAlphaCode_DiagGMXmlDataFileAlphaCode_0_0
        enable-take-address=true, indirect-api=false, port=DataServices_DID_F1C0_GMBootSoftwarePartNumber_GMBootSoftwarePartNumber_0_0
        enable-take-address=true, indirect-api=false, port=DataServices_DID_F107_GMSoftwareModuleIdentifierAlphaCode_14_GMSoftwareModuleIdentifierAlphaCode_14_0_0
        enable-take-address=true, indirect-api=false, port=DataServices_DID_F199_ProgrammingDate_DiagProgrammingDate_0_0
        enable-take-address=true, indirect-api=false, port=DataServices_DID_F1DB_GMEndModelPartNumberAlphaCode_GMEndModelPartNumberAlphaCode_0_0
        enable-take-address=true, indirect-api=false, port=DataServices_DID_F0F4_SignatureBypassAuthorizationTicket_SignatureBypassAuthorizationTicket_0_0
        enable-take-address=true, indirect-api=false, port=DataServices_DID_F11A_GMSoftwareModuleIdentifier_24_GMSoftwareModuleIdentifier_24_0_0
        enable-take-address=true, indirect-api=false, port=DataServices_DID_F101_GMSoftwareModuleIdentifierAlphaCode_11_GMSoftwareModuleIdentifierAlphaCode_11_0_0
        enable-take-address=true, indirect-api=false, port=DataServices_DID_F2A0_ReadMemoryEnableCounter_DiagReadMemoryEnableCounter_0_0
        enable-take-address=true, indirect-api=false, port=DataServices_DID_F1CB_GMEndModelPartNumber_GMEndModelPartNumber_0_0
        enable-take-address=true, indirect-api=false, port=DataServices_DID_F1A9_GMXMLRepairShopCodeOrTesterSerialNumber_DiagXMLRepairShopCodeOrTesterSerialNumber_0_0
        enable-take-address=true, indirect-api=false, port=DataServices_DID_F080_ECUKeyProvisionStateFlag_ECUKeyProvisionStateFlag_0_0
        enable-take-address=true, indirect-api=false, port=DataServices_DID_F1D3_GMSoftwareModuleIdentifierAlphaCode_03_GMSoftwareModuleIdentifierAlphaCode_03_0_0
        enable-take-address=true, indirect-api=false, port=DataServices_DID_F1DC_GMBaseModelPartNumberAlphaCode_GMBaseModelPartNumberAlphaCode_0_0
        enable-take-address=true, indirect-api=false, port=DataServices_DID_F106_GMSoftwareModuleIdentifier_14_GMSoftwareModuleIdentifier_14_0_0
        enable-take-address=true, indirect-api=false, port=DataServices_DID_F113_GMSoftwareModuleIdentifierAlphaCode_20_GMSoftwareModuleIdentifierAlphaCode_20_0_0
        enable-take-address=true, indirect-api=false, port=DataServices_DID_F109_GMSoftwareModuleIdentifierAlphaCode_15_GMSoftwareModuleIdentifierAlphaCode_15_0_0
        enable-take-address=true, indirect-api=false, port=DataServices_DID_F1D1_GMSoftwareModuleIdentifierAlphaCode_01_GMSoftwareModuleIdentifierAlphaCode_01_0_0
        enable-take-address=true, indirect-api=false, port=DataServices_DID_F0F6_BootInfoBlockSubjectNameandECUName_SubjectName_0_0
        enable-take-address=true, indirect-api=false, port=DataServices_DID_F0F6_BootInfoBlockSubjectNameandECUName_ECUName_16_0
        enable-take-address=true, indirect-api=false, port=DataServices_DID_F084_MessageAuthenticationAntiReplayCounters_MessageAuthenticationAntiReplayCounters_0_0
        enable-take-address=true, indirect-api=false, port=DataServices_DID_F108_GMSoftwareModuleIdentifier_15_GMSoftwareModuleIdentifier_15_0_0
        enable-take-address=true, indirect-api=false, port=DataServices_DID_F10D_GMSoftwareModuleIdentifierAlphaCode_17_GMSoftwareModuleIdentifierAlphaCode_17_0_0
        enable-take-address=true, indirect-api=false, port=DataServices_DID_F11B_GMSoftwareModuleIdentifierAlphaCode_24_GMSoftwareModuleIdentifierAlphaCode_24_0_0
        enable-take-address=true, indirect-api=false, port=DataServices_DID_F1CA_GMSoftwareModuleIdentifier_10_GMSoftwareModuleIdentifier_10_0_0
        enable-take-address=true, indirect-api=false, port=DataServices_DID_F1C5_GMSoftwareModuleIdentifier_05_GMSoftwareModuleIdentifier_05_0_0
        enable-take-address=true, indirect-api=false, port=DataServices_DID_F1B0_ECUDiagnosticAddress_ECUDiagnosticAddress_0_0
        enable-take-address=true, indirect-api=false, port=DataServices_DID_F11D_GMSoftwareModuleIdentifierAlphaCode_25_GMSoftwareModuleIdentifierAlphaCode_25_0_0
        enable-take-address=true, indirect-api=false, port=DataServices_DID_F081_ECUKeyConfigurationData_ECUKeyConfigurationData_0_0
        enable-take-address=true, indirect-api=false, port=DataServices_DID_F1D7_GMSoftwareModuleIdentifierAlphaCode_07_GMSoftwareModuleIdentifierAlphaCode_07_0_0
        enable-take-address=true, indirect-api=false, port=DataServices_DID_F09A_DiagnosticDataIdentifier_DiagSystemCode_0_0
        enable-take-address=true, indirect-api=false, port=DataServices_DID_F09A_DiagnosticDataIdentifier_DiagDiagnosticDataStreamVersionNumber_1_0
        enable-take-address=true, indirect-api=false, port=DataServices_DID_F11E_GMSoftwareModuleIdentifier_26_GMSoftwareModuleIdentifier_26_0_0
        enable-take-address=true, indirect-api=false, port=DataServices_DID_F1C8_GMSoftwareModuleIdentifier_08_GMSoftwareModuleIdentifier_08_0_0
        enable-take-address=true, indirect-api=false, port=DataServices_DID_F118_GMSoftwareModuleIdentifier_23_GMSoftwareModuleIdentifier_23_0_0
        enable-take-address=true, indirect-api=false, port=DataServices_DID_F1C9_GMSoftwareModuleIdentifier_09_GMSoftwareModuleIdentifier_09_0_0
        enable-take-address=true, indirect-api=false, port=DataServices_DID_F125_GMSoftwareModuleIdentifierAlphaCode_29_GMSoftwareModuleIdentifierAlphaCode_29_0_0
        enable-take-address=true, indirect-api=false, port=DataServices_DID_F0F3_ECUID_ECUID_0_0
        enable-take-address=true, indirect-api=false, port=DataServices_DID_F115_GMSoftwareModuleIdentifierAlphaCode_21_GMSoftwareModuleIdentifierAlphaCode_21_0_0
        enable-take-address=true, indirect-api=false, port=DataServices_DID_F123_GMSoftwareModuleIdentifierAlphaCode_28_GMSoftwareModuleIdentifierAlphaCode_28_0_0
        enable-take-address=true, indirect-api=false, port=DataServices_DID_F1D2_GMSoftwareModuleIdentifierAlphaCode_02_GMSoftwareModuleIdentifierAlphaCode_02_0_0
        enable-take-address=true, indirect-api=false, port=DataServices_DID_F1C4_GMSoftwareModuleIdentifier_04_GMSoftwareModuleIdentifier_04_0_0
        enable-take-address=true, indirect-api=false, port=DataServices_DID_F1C2_GMSoftwareModuleIdentifier_02_GMSoftwareModuleIdentifier_02_0_0
        enable-take-address=true, indirect-api=false, port=DataServices_DID_F083_MessageAuthenticationCalibrationFilePartNumber_MessageAuthenticationCalibrationFilePartNumber_0_0
        enable-take-address=true, indirect-api=false, port=DataServices_DID_F110_GMSoftwareModuleIdentifier_19_GMSoftwareModuleIdentifier_19_0_0
        enable-take-address=true, indirect-api=false, port=DataServices_DID_F124_GMSoftwareModuleIdentifier_29_GMSoftwareModuleIdentifier_29_0_0
        enable-take-address=true, indirect-api=false, port=DataServices_DID_F119_GMSoftwareModuleIdentifierAlphaCode_23_GMSoftwareModuleIdentifierAlphaCode_23_0_0
        enable-take-address=true, indirect-api=false, port=DataServices_DID_F1D8_GMSoftwareModuleIdentifierAlphaCode_08_GMSoftwareModuleIdentifierAlphaCode_08_0_0
        enable-take-address=true, indirect-api=false, port=DataServices_DID_F129_TotalVehicleOperationTime_DataRecord
        enable-take-address=true, indirect-api=false, port=DataServices_DID_F1D9_GMSoftwareModuleIdentifierAlphaCode_09_GMSoftwareModuleIdentifierAlphaCode_09_0_0
        enable-take-address=true, indirect-api=false, port=DataServices_DID_F126_GMSoftwareModuleIdentifier_30_GMSoftwareModuleIdentifier_30_0_0
        enable-take-address=true, indirect-api=false, port=DataServices_DID_F190_VehicleIdentificationNumber_VehicleIdentificationNumber_0_0
        enable-take-address=true, indirect-api=false, port=DataServices_DID_F1C7_GMSoftwareModuleIdentifier_07_GMSoftwareModuleIdentifier_07_0_0
        enable-take-address=true, indirect-api=false, port=DataServices_DID_F0B3_DataUniversalNumberingSystemIdentification_DiagDataUniversalNumberingSystemIdentification_0_0
        enable-take-address=true, indirect-api=false, port=DataServices_DID_F11F_GMSoftwareModuleIdentifierAlphaCode_26_GMSoftwareModuleIdentifierAlphaCode_26_0_0
        enable-take-address=true, indirect-api=false, port=DataServices_DID_F10B_GMSoftwareModuleIdentifierAlphaCode_16_GMSoftwareModuleIdentifierAlphaCode_16_0_0
        enable-take-address=true, indirect-api=false, port=DataServices_DID_F1D0_GMBootSoftwarePartNumberAlphaCode_GMBootSoftwarePartNumberAlphaCode_0_0
        enable-take-address=true, indirect-api=false, port=DataServices_DID_F1D5_GMSoftwareModuleIdentifierAlphaCode_05_GMSoftwareModuleIdentifierAlphaCode_05_0_0
        enable-take-address=true, indirect-api=false, port=DataServices_DID_F111_GMSoftwareModuleIdentifierAlphaCode_19_GMSoftwareModuleIdentifierAlphaCode_19_0_0
        enable-take-address=true, indirect-api=false, port=DataServices_DID_F180_BootSoftwareIdentificationDataIdentifier_BootSoftwareIdentificationDataIdentifier_0_0
        enable-take-address=true, indirect-api=false, port=DataServices_DID_F127_GMSoftwareModuleIdentifierAlphaCode_30_GMSoftwareModuleIdentifierAlphaCode_30_0_0
        enable-take-address=true, indirect-api=false, port=DataServices_DID_F198_RepairShopCodeOrTesterSerialNumber_DiagRepairShopCodeOrTesterSerialNumber_0_0
        enable-take-address=true, indirect-api=false, port=DataServices_DID_F121_GMSoftwareModuleIdentifierAlphaCode_27_GMSoftwareModuleIdentifierAlphaCode_27_0_0
        enable-take-address=true, indirect-api=false, port=DataServices_DID_F09C_GMXmlDataFilePartNumber_DiagGMXmlDataFilePartNumber_0_0
        enable-take-address=true, indirect-api=false, port=DataServices_DID_F0B4_ManufacturingTraceabilityCharacters_DiagYear_2_0
        enable-take-address=true, indirect-api=false, port=DataServices_DID_F0B4_ManufacturingTraceabilityCharacters_DiagTraceabilityNumber_7_0
        enable-take-address=true, indirect-api=false, port=DataServices_DID_F0B4_ManufacturingTraceabilityCharacters_DiagShift_1_0
        enable-take-address=true, indirect-api=false, port=DataServices_DID_F0B4_ManufacturingTraceabilityCharacters_DiagLine_0_0
        enable-take-address=true, indirect-api=false, port=DataServices_DID_F0B4_ManufacturingTraceabilityCharacters_DiagDayOfTheYear_4_0
        enable-take-address=true, indirect-api=false, port=DataServices_DID_F0BE_MasterNetworkConfigurationListLIN_DiagMasterNetworkConfigurationListLIN_0_0
        enable-take-address=true, indirect-api=false, port=DataServices_DID_F1DD_GMSoftwareModuleIdentifierDataIdentifiers_GMSoftwareModuleIdentifierDataIdentifiers_0_0
        enable-take-address=true, indirect-api=false, port=Dcm
      6 x runnable:
        Dcm_MainFunctionTimer
        Dcm_MainFunctionWorker
          5 x mode switch point:
            ModeSwitchPointDcm_MainFunctionWorker_DcmControlDtcSetting_DcmControlDtcSetting: mode-group=DcmControlDtcSetting.DcmControlDtcSetting
            ModeSwitchPointDcm_MainFunctionWorker_DcmEcuReset_DcmEcuReset: mode-group=DcmEcuReset.DcmEcuReset
            ModeSwitchPointDcm_MainFunctionWorker_DcmModeRapidPowerShutDown_DcmModeRapidPowerShutDown: mode-group=DcmModeRapidPowerShutDown.DcmModeRapidPowerShutDown
            ModeSwitchPointDcm_MainFunctionWorker_DcmDiagnosticSessionControl_DcmDiagnosticSessionControl: mode-group=DcmDiagnosticSessionControl.DcmDiagnosticSessionControl
            ModeSwitchPointDcm_MainFunctionWorker_DcmCommunicationControl_ComMConf_ComMChannel_CAN_5_Cluster_def1eb88_DcmCommunicat_34bfc37c: mode-group=DcmCommunicationControl_ComMConf_ComMChannel_CAN_5_Cluster_def1eb88.DcmCommunicationControl_ComMConf_ComMChannel_CAN_5_Cluster_def1eb88
          150 x sync call, all with timeout=0:
            OpServerCallDcm_MainFunctionWorker_Indication_ServiceRequestSupplierNotification_ERRH_ControlDTCSetting: operation=ServiceRequestSupplierNotification_ERRH_ControlDTCSetting.Indication
            OpServerCallDcm_MainFunctionWorker_Confirmation_ServiceRequestSupplierNotification_ERRH_ControlDTCSetting: operation=ServiceRequestSupplierNotification_ERRH_ControlDTCSetting.Confirmation
            OpServerCallDcm_MainFunctionWorker_Indication_ServiceRequestSupplierNotification_DIAG_CommunicationControl: operation=ServiceRequestSupplierNotification_DIAG_CommunicationControl.Indication
            OpServerCallDcm_MainFunctionWorker_Confirmation_ServiceRequestSupplierNotification_DIAG_CommunicationControl: operation=ServiceRequestSupplierNotification_DIAG_CommunicationControl.Confirmation
            OpServerCallDcm_MainFunctionWorker_Indication_ServiceRequestSupplierNotification_DIAG_DiagnosticSessionControl: operation=ServiceRequestSupplierNotification_DIAG_DiagnosticSessionControl.Indication
            OpServerCallDcm_MainFunctionWorker_Confirmation_ServiceRequestSupplierNotification_DIAG_DiagnosticSessionControl: operation=ServiceRequestSupplierNotification_DIAG_DiagnosticSessionControl.Confirmation
            OpServerCallDcm_MainFunctionWorker_GetSeed_SecurityAccess_Level_1: operation=SecurityAccess_Level_1.GetSeed
            OpServerCallDcm_MainFunctionWorker_CompareKey_SecurityAccess_Level_1: operation=SecurityAccess_Level_1.CompareKey
            OpServerCallDcm_MainFunctionWorker_GetSeed_SecurityAccess_Level_3: operation=SecurityAccess_Level_3.GetSeed
            OpServerCallDcm_MainFunctionWorker_CompareKey_SecurityAccess_Level_3: operation=SecurityAccess_Level_3.CompareKey
            OpServerCallDcm_MainFunctionWorker_GetSeed_SecurityAccess_Level_9: operation=SecurityAccess_Level_9.GetSeed
            OpServerCallDcm_MainFunctionWorker_CompareKey_SecurityAccess_Level_9: operation=SecurityAccess_Level_9.CompareKey
            OpServerCallDcm_MainFunctionWorker_GetSeed_SecurityAccess_Level_B: operation=SecurityAccess_Level_B.GetSeed
            OpServerCallDcm_MainFunctionWorker_CompareKey_SecurityAccess_Level_B: operation=SecurityAccess_Level_B.CompareKey
            OpServerCallDcm_MainFunctionWorker_GetSeed_SecurityAccess_Level_D: operation=SecurityAccess_Level_D.GetSeed
            OpServerCallDcm_MainFunctionWorker_CompareKey_SecurityAccess_Level_D: operation=SecurityAccess_Level_D.CompareKey
            OpServerCallDcm_MainFunctionWorker_GetSeed_SecurityAccess_Level_11: operation=SecurityAccess_Level_11.GetSeed
            OpServerCallDcm_MainFunctionWorker_CompareKey_SecurityAccess_Level_11: operation=SecurityAccess_Level_11.CompareKey
            OpServerCallDcm_MainFunctionWorker_GetSeed_SecurityAccess_Level_5F: operation=SecurityAccess_Level_5F.GetSeed
            OpServerCallDcm_MainFunctionWorker_CompareKey_SecurityAccess_Level_5F: operation=SecurityAccess_Level_5F.CompareKey
            OpServerCallDcm_MainFunctionWorker_Start_RoutineServices_RID_0200_ProvisionSecurityPeripheralGeneralKeys: operation=RoutineServices_RID_0200_ProvisionSecurityPeripheralGeneralKeys.Start
            OpServerCallDcm_MainFunctionWorker_Start_RoutineServices_RID_0204_ECUKeyProvisionData: operation=RoutineServices_RID_0204_ECUKeyProvisionData.Start
            OpServerCallDcm_MainFunctionWorker_Start_RoutineServices_RID_0205_SecuredECUKeyProvisionData: operation=RoutineServices_RID_0205_SecuredECUKeyProvisionData.Start
            OpServerCallDcm_MainFunctionWorker_Start_RoutineServices_RID_0209_UpdateProgrammedStateIndicatorForPartition: operation=RoutineServices_RID_0209_UpdateProgrammedStateIndicatorForPartition.Start
            OpServerCallDcm_MainFunctionWorker_Start_RoutineServices_RID_021E_DiagInitiateExtendedReflash: operation=RoutineServices_RID_021E_DiagInitiateExtendedReflash.Start
            OpServerCallDcm_MainFunctionWorker_Start_RoutineServices_RID_FF00_EraseMemory: operation=RoutineServices_RID_FF00_EraseMemory.Start
            OpServerCallDcm_MainFunctionWorker_ReadData_DataServices_DID_F0F2_BootInitializationStatus_BootInitializationStatus_0_0: operation=DataServices_DID_F0F2_BootInitializationStatus_BootInitializationStatus_0_0.ReadData
            OpServerCallDcm_MainFunctionWorker_ReadData_DataServices_DID_F1DA_GMSoftwareModuleIdentifierAlphaCode_10_GMSoftwareModu_7c350d54: operation=DataServices_DID_F1DA_GMSoftwareModuleIdentifierAlphaCode_10_GMSoftwareModuleIdentifierAlphaCode_10_0_0.ReadData
            OpServerCallDcm_MainFunctionWorker_ReadData_DataServices_DID_F112_GMSoftwareModuleIdentifier_20_GMSoftwareModuleIdentif_61d449b1: operation=DataServices_DID_F112_GMSoftwareModuleIdentifier_20_GMSoftwareModuleIdentifier_20_0_0.ReadData
            OpServerCallDcm_MainFunctionWorker_ReadData_DataServices_DID_F11C_GMSoftwareModuleIdentifier_25_GMSoftwareModuleIdentif_9f63dfcf: operation=DataServices_DID_F11C_GMSoftwareModuleIdentifier_25_GMSoftwareModuleIdentifier_25_0_0.ReadData
            OpServerCallDcm_MainFunctionWorker_ReadData_DataServices_DID_F10F_GMSoftwareModuleIdentifierAlphaCode_18_GMSoftwareModu_b1947944: operation=DataServices_DID_F10F_GMSoftwareModuleIdentifierAlphaCode_18_GMSoftwareModuleIdentifierAlphaCode_18_0_0.ReadData
            OpServerCallDcm_MainFunctionWorker_ReadData_DataServices_DID_F100_GMSoftwareModuleIdentifier_11_GMSoftwareModuleIdentif_e212700b: operation=DataServices_DID_F100_GMSoftwareModuleIdentifier_11_GMSoftwareModuleIdentifier_11_0_0.ReadData
            OpServerCallDcm_MainFunctionWorker_ReadData_DataServices_DID_F1CC_GMBaseModelPartNumber_GMBaseModelPartNumber_0_0: operation=DataServices_DID_F1CC_GMBaseModelPartNumber_GMBaseModelPartNumber_0_0.ReadData
            OpServerCallDcm_MainFunctionWorker_ReadData_DataServices_DID_F09B_GMXmlConfigurationCompatibilityIdentifier_DiagXmlConf_806a4f0f: operation=DataServices_DID_F09B_GMXmlConfigurationCompatibilityIdentifier_DiagXmlConfigurationCompatibilityIdentifier_0_0.ReadData
            OpServerCallDcm_MainFunctionWorker_ReadData_DataServices_DID_F102_GMSoftwareModuleIdentifier_12_GMSoftwareModuleIdentif_f4c4974f: operation=DataServices_DID_F102_GMSoftwareModuleIdentifier_12_GMSoftwareModuleIdentifier_12_0_0.ReadData
            OpServerCallDcm_MainFunctionWorker_ReadData_DataServices_DID_F1C3_GMSoftwareModuleIdentifier_03_GMSoftwareModuleIdentif_018150c3: operation=DataServices_DID_F1C3_GMSoftwareModuleIdentifier_03_GMSoftwareModuleIdentifier_03_0_0.ReadData
            OpServerCallDcm_MainFunctionWorker_ReadData_DataServices_DID_F0AB_CompressedVehiclePartitioningAndProductStructure_Diag_67fa4c7f: operation=DataServices_DID_F0AB_CompressedVehiclePartitioningAndProductStructure_DiagCompressedVehiclePartitioningAndProductStructure_0_0.ReadData
            OpServerCallDcm_MainFunctionWorker_ReadData_DataServices_DID_F10A_GMSoftwareModuleIdentifier_16_GMSoftwareModuleIdentif_22289cc4: operation=DataServices_DID_F10A_GMSoftwareModuleIdentifier_16_GMSoftwareModuleIdentifier_16_0_0.ReadData
            OpServerCallDcm_MainFunctionWorker_ReadData_DataServices_DID_F116_GMSoftwareModuleIdentifier_22_GMSoftwareModuleIdentif_3163725b: operation=DataServices_DID_F116_GMSoftwareModuleIdentifier_22_GMSoftwareModuleIdentifier_22_0_0.ReadData
            OpServerCallDcm_MainFunctionWorker_ReadData_DataServices_DID_F1C1_GMSoftwareModuleIdentifier_01_GMSoftwareModuleIdentif_e5a989ff: operation=DataServices_DID_F1C1_GMSoftwareModuleIdentifier_01_GMSoftwareModuleIdentifier_01_0_0.ReadData
            OpServerCallDcm_MainFunctionWorker_ReadData_DataServices_DID_F1D4_GMSoftwareModuleIdentifierAlphaCode_04_GMSoftwareModu_badcdf12: operation=DataServices_DID_F1D4_GMSoftwareModuleIdentifierAlphaCode_04_GMSoftwareModuleIdentifierAlphaCode_04_0_0.ReadData
            OpServerCallDcm_MainFunctionWorker_ReadData_DataServices_DID_F1D6_GMSoftwareModuleIdentifierAlphaCode_06_GMSoftwareModu_98b3554a: operation=DataServices_DID_F1D6_GMSoftwareModuleIdentifierAlphaCode_06_GMSoftwareModuleIdentifierAlphaCode_06_0_0.ReadData
            OpServerCallDcm_MainFunctionWorker_ReadData_DataServices_DID_F122_GMSoftwareModuleIdentifier_28_GMSoftwareModuleIdentif_41db5454: operation=DataServices_DID_F122_GMSoftwareModuleIdentifier_28_GMSoftwareModuleIdentifier_28_0_0.ReadData
            OpServerCallDcm_MainFunctionWorker_ReadData_DataServices_DID_F104_GMSoftwareModuleIdentifier_13_GMSoftwareModuleIdentif_b2a54be1: operation=DataServices_DID_F104_GMSoftwareModuleIdentifier_13_GMSoftwareModuleIdentifier_13_0_0.ReadData
            OpServerCallDcm_MainFunctionWorker_ReadData_DataServices_DID_F10C_GMSoftwareModuleIdentifier_17_GMSoftwareModuleIdentif_0a730131: operation=DataServices_DID_F10C_GMSoftwareModuleIdentifier_17_GMSoftwareModuleIdentifier_17_0_0.ReadData
            OpServerCallDcm_MainFunctionWorker_ReadData_DataServices_DID_F1A0_ManufacturersEnableCounter_ManufacturersEnableCounter_0_0: operation=DataServices_DID_F1A0_ManufacturersEnableCounter_ManufacturersEnableCounter_0_0.ReadData
            OpServerCallDcm_MainFunctionWorker_WriteData_DataServices_DID_F1A0_ManufacturersEnableCounter_ManufacturersEnableCounter_0_0: operation=DataServices_DID_F1A0_ManufacturersEnableCounter_ManufacturersEnableCounter_0_0.WriteData
            OpServerCallDcm_MainFunctionWorker_ReadData_DataServices_DID_F103_GMSoftwareModuleIdentifierAlphaCode_12_GMSoftwareModu_d647ba97: operation=DataServices_DID_F103_GMSoftwareModuleIdentifierAlphaCode_12_GMSoftwareModuleIdentifierAlphaCode_12_0_0.ReadData
            OpServerCallDcm_MainFunctionWorker_ReadData_DataServices_DID_F0F0_ProgrammedStateIndicator_ProgrammedStateIndicator_0_0: operation=DataServices_DID_F0F0_ProgrammedStateIndicator_ProgrammedStateIndicator_0_0.ReadData
            OpServerCallDcm_MainFunctionWorker_ReadDataLength_DataServices_DID_F0F0_ProgrammedStateIndicator_ProgrammedStateIndicator_0_0: operation=DataServices_DID_F0F0_ProgrammedStateIndicator_ProgrammedStateIndicator_0_0.ReadDataLength
            OpServerCallDcm_MainFunctionWorker_ReadData_DataServices_DID_F120_GMSoftwareModuleIdentifier_27_GMSoftwareModuleIdentif_d022acb6: operation=DataServices_DID_F120_GMSoftwareModuleIdentifier_27_GMSoftwareModuleIdentifier_27_0_0.ReadData
            OpServerCallDcm_MainFunctionWorker_ReadData_DataServices_DID_F0F1_ProgramingErrorCode_ProgramingErrorCode_0_0: operation=DataServices_DID_F0F1_ProgramingErrorCode_ProgramingErrorCode_0_0.ReadData
            OpServerCallDcm_MainFunctionWorker_ReadData_DataServices_DID_F117_GMSoftwareModuleIdentifierAlphaCode_22_GMSoftwareModu_2ce4459b: operation=DataServices_DID_F117_GMSoftwareModuleIdentifierAlphaCode_22_GMSoftwareModuleIdentifierAlphaCode_22_0_0.ReadData
            OpServerCallDcm_MainFunctionWorker_ReadData_DataServices_DID_F114_GMSoftwareModuleIdentifier_21_GMSoftwareModuleIdentif_27b5951f: operation=DataServices_DID_F114_GMSoftwareModuleIdentifier_21_GMSoftwareModuleIdentifier_21_0_0.ReadData
            OpServerCallDcm_MainFunctionWorker_ReadData_DataServices_DID_F1AA_GMXMLProgrammingDate_DiagXMLProgrammingDate_0_0: operation=DataServices_DID_F1AA_GMXMLProgrammingDate_DiagXMLProgrammingDate_0_0.ReadData
            OpServerCallDcm_MainFunctionWorker_WriteData_DataServices_DID_F1AA_GMXMLProgrammingDate_DiagXMLProgrammingDate_0_0: operation=DataServices_DID_F1AA_GMXMLProgrammingDate_DiagXMLProgrammingDate_0_0.WriteData
            OpServerCallDcm_MainFunctionWorker_ReadData_DataServices_DID_F10E_GMSoftwareModuleIdentifier_18_GMSoftwareModuleIdentif_f5b0b888: operation=DataServices_DID_F10E_GMSoftwareModuleIdentifier_18_GMSoftwareModuleIdentifier_18_0_0.ReadData
            OpServerCallDcm_MainFunctionWorker_ReadData_DataServices_DID_F1C6_GMSoftwareModuleIdentifier_06_GMSoftwareModuleIdentif_60b58864: operation=DataServices_DID_F1C6_GMSoftwareModuleIdentifier_06_GMSoftwareModuleIdentifier_06_0_0.ReadData
            OpServerCallDcm_MainFunctionWorker_ReadData_DataServices_DID_F105_GMSoftwareModuleIdentifierAlphaCode_13_GMSoftwareModu_d40f5141: operation=DataServices_DID_F105_GMSoftwareModuleIdentifierAlphaCode_13_GMSoftwareModuleIdentifierAlphaCode_13_0_0.ReadData
            OpServerCallDcm_MainFunctionWorker_ReadData_DataServices_DID_F09D_GMXmlDataFileAlphaCode_DiagGMXmlDataFileAlphaCode_0_0: operation=DataServices_DID_F09D_GMXmlDataFileAlphaCode_DiagGMXmlDataFileAlphaCode_0_0.ReadData
            OpServerCallDcm_MainFunctionWorker_WriteData_DataServices_DID_F09D_GMXmlDataFileAlphaCode_DiagGMXmlDataFileAlphaCode_0_0: operation=DataServices_DID_F09D_GMXmlDataFileAlphaCode_DiagGMXmlDataFileAlphaCode_0_0.WriteData
            OpServerCallDcm_MainFunctionWorker_ReadData_DataServices_DID_F1C0_GMBootSoftwarePartNumber_GMBootSoftwarePartNumber_0_0: operation=DataServices_DID_F1C0_GMBootSoftwarePartNumber_GMBootSoftwarePartNumber_0_0.ReadData
            OpServerCallDcm_MainFunctionWorker_ReadData_DataServices_DID_F107_GMSoftwareModuleIdentifierAlphaCode_14_GMSoftwareModu_bc088d83: operation=DataServices_DID_F107_GMSoftwareModuleIdentifierAlphaCode_14_GMSoftwareModuleIdentifierAlphaCode_14_0_0.ReadData
            OpServerCallDcm_MainFunctionWorker_ReadData_DataServices_DID_F199_ProgrammingDate_DiagProgrammingDate_0_0: operation=DataServices_DID_F199_ProgrammingDate_DiagProgrammingDate_0_0.ReadData
            OpServerCallDcm_MainFunctionWorker_WriteData_DataServices_DID_F199_ProgrammingDate_DiagProgrammingDate_0_0: operation=DataServices_DID_F199_ProgrammingDate_DiagProgrammingDate_0_0.WriteData
            OpServerCallDcm_MainFunctionWorker_ReadData_DataServices_DID_F1DB_GMEndModelPartNumberAlphaCode_GMEndModelPartNumberAlp_91a5a803: operation=DataServices_DID_F1DB_GMEndModelPartNumberAlphaCode_GMEndModelPartNumberAlphaCode_0_0.ReadData
            OpServerCallDcm_MainFunctionWorker_ReadData_DataServices_DID_F0F4_SignatureBypassAuthorizationTicket_SignatureBypassAut_176a60d8: operation=DataServices_DID_F0F4_SignatureBypassAuthorizationTicket_SignatureBypassAuthorizationTicket_0_0.ReadData
            OpServerCallDcm_MainFunctionWorker_WriteData_DataServices_DID_F0F4_SignatureBypassAuthorizationTicket_SignatureBypassAu_d6e2edbe: operation=DataServices_DID_F0F4_SignatureBypassAuthorizationTicket_SignatureBypassAuthorizationTicket_0_0.WriteData
            OpServerCallDcm_MainFunctionWorker_ReadData_DataServices_DID_F11A_GMSoftwareModuleIdentifier_24_GMSoftwareModuleIdentif_b738423a: operation=DataServices_DID_F11A_GMSoftwareModuleIdentifier_24_GMSoftwareModuleIdentifier_24_0_0.ReadData
            OpServerCallDcm_MainFunctionWorker_ReadData_DataServices_DID_F101_GMSoftwareModuleIdentifierAlphaCode_11_GMSoftwareModu_e360211d: operation=DataServices_DID_F101_GMSoftwareModuleIdentifierAlphaCode_11_GMSoftwareModuleIdentifierAlphaCode_11_0_0.ReadData
            OpServerCallDcm_MainFunctionWorker_ReadData_DataServices_DID_F2A0_ReadMemoryEnableCounter_DiagReadMemoryEnableCounter_0_0: operation=DataServices_DID_F2A0_ReadMemoryEnableCounter_DiagReadMemoryEnableCounter_0_0.ReadData
            OpServerCallDcm_MainFunctionWorker_WriteData_DataServices_DID_F2A0_ReadMemoryEnableCounter_DiagReadMemoryEnableCounter_0_0: operation=DataServices_DID_F2A0_ReadMemoryEnableCounter_DiagReadMemoryEnableCounter_0_0.WriteData
            OpServerCallDcm_MainFunctionWorker_ReadData_DataServices_DID_F1CB_GMEndModelPartNumber_GMEndModelPartNumber_0_0: operation=DataServices_DID_F1CB_GMEndModelPartNumber_GMEndModelPartNumber_0_0.ReadData
            OpServerCallDcm_MainFunctionWorker_ReadData_DataServices_DID_F1A9_GMXMLRepairShopCodeOrTesterSerialNumber_DiagXMLRepair_bad9b176: operation=DataServices_DID_F1A9_GMXMLRepairShopCodeOrTesterSerialNumber_DiagXMLRepairShopCodeOrTesterSerialNumber_0_0.ReadData
            OpServerCallDcm_MainFunctionWorker_WriteData_DataServices_DID_F1A9_GMXMLRepairShopCodeOrTesterSerialNumber_DiagXMLRepai_9bad5ef8: operation=DataServices_DID_F1A9_GMXMLRepairShopCodeOrTesterSerialNumber_DiagXMLRepairShopCodeOrTesterSerialNumber_0_0.WriteData
            OpServerCallDcm_MainFunctionWorker_ReadData_DataServices_DID_F080_ECUKeyProvisionStateFlag_ECUKeyProvisionStateFlag_0_0: operation=DataServices_DID_F080_ECUKeyProvisionStateFlag_ECUKeyProvisionStateFlag_0_0.ReadData
            OpServerCallDcm_MainFunctionWorker_WriteData_DataServices_DID_F080_ECUKeyProvisionStateFlag_ECUKeyProvisionStateFlag_0_0: operation=DataServices_DID_F080_ECUKeyProvisionStateFlag_ECUKeyProvisionStateFlag_0_0.WriteData
            OpServerCallDcm_MainFunctionWorker_ReadData_DataServices_DID_F1D3_GMSoftwareModuleIdentifierAlphaCode_03_GMSoftwareModu_cd5b84d6: operation=DataServices_DID_F1D3_GMSoftwareModuleIdentifierAlphaCode_03_GMSoftwareModuleIdentifierAlphaCode_03_0_0.ReadData
            OpServerCallDcm_MainFunctionWorker_ReadData_DataServices_DID_F1DC_GMBaseModelPartNumberAlphaCode_GMBaseModelPartNumberA_ea88225b: operation=DataServices_DID_F1DC_GMBaseModelPartNumberAlphaCode_GMBaseModelPartNumberAlphaCode_0_0.ReadData
            OpServerCallDcm_MainFunctionWorker_ReadData_DataServices_DID_F106_GMSoftwareModuleIdentifier_14_GMSoftwareModuleIdentif_d96959c7: operation=DataServices_DID_F106_GMSoftwareModuleIdentifier_14_GMSoftwareModuleIdentifier_14_0_0.ReadData
            OpServerCallDcm_MainFunctionWorker_ReadData_DataServices_DID_F113_GMSoftwareModuleIdentifierAlphaCode_20_GMSoftwareModu_1b8b35c7: operation=DataServices_DID_F113_GMSoftwareModuleIdentifierAlphaCode_20_GMSoftwareModuleIdentifierAlphaCode_20_0_0.ReadData
            OpServerCallDcm_MainFunctionWorker_ReadData_DataServices_DID_F109_GMSoftwareModuleIdentifierAlphaCode_15_GMSoftwareModu_8dbec1a5: operation=DataServices_DID_F109_GMSoftwareModuleIdentifierAlphaCode_15_GMSoftwareModuleIdentifierAlphaCode_15_0_0.ReadData
            OpServerCallDcm_MainFunctionWorker_ReadData_DataServices_DID_F1D1_GMSoftwareModuleIdentifierAlphaCode_01_GMSoftwareModu_ef340e8e: operation=DataServices_DID_F1D1_GMSoftwareModuleIdentifierAlphaCode_01_GMSoftwareModuleIdentifierAlphaCode_01_0_0.ReadData
            OpServerCallDcm_MainFunctionWorker_ReadData_DataServices_DID_F0F6_BootInfoBlockSubjectNameandECUName_SubjectName_0_0: operation=DataServices_DID_F0F6_BootInfoBlockSubjectNameandECUName_SubjectName_0_0.ReadData
            OpServerCallDcm_MainFunctionWorker_ReadData_DataServices_DID_F0F6_BootInfoBlockSubjectNameandECUName_ECUName_16_0: operation=DataServices_DID_F0F6_BootInfoBlockSubjectNameandECUName_ECUName_16_0.ReadData
            OpServerCallDcm_MainFunctionWorker_ReadData_DataServices_DID_F084_MessageAuthenticationAntiReplayCounters_MessageAuthen_014b1e58: operation=DataServices_DID_F084_MessageAuthenticationAntiReplayCounters_MessageAuthenticationAntiReplayCounters_0_0.ReadData
            OpServerCallDcm_MainFunctionWorker_ReadDataLength_DataServices_DID_F084_MessageAuthenticationAntiReplayCounters_Message_110d397e: operation=DataServices_DID_F084_MessageAuthenticationAntiReplayCounters_MessageAuthenticationAntiReplayCounters_0_0.ReadDataLength
            OpServerCallDcm_MainFunctionWorker_ReadData_DataServices_DID_F108_GMSoftwareModuleIdentifier_15_GMSoftwareModuleIdentif_437c07df: operation=DataServices_DID_F108_GMSoftwareModuleIdentifier_15_GMSoftwareModuleIdentifier_15_0_0.ReadData
            OpServerCallDcm_MainFunctionWorker_ReadData_DataServices_DID_F10D_GMSoftwareModuleIdentifierAlphaCode_17_GMSoftwareModu_63d32b16: operation=DataServices_DID_F10D_GMSoftwareModuleIdentifierAlphaCode_17_GMSoftwareModuleIdentifierAlphaCode_17_0_0.ReadData
            OpServerCallDcm_MainFunctionWorker_ReadData_DataServices_DID_F11B_GMSoftwareModuleIdentifierAlphaCode_24_GMSoftwareModu_ac574f90: operation=DataServices_DID_F11B_GMSoftwareModuleIdentifierAlphaCode_24_GMSoftwareModuleIdentifierAlphaCode_24_0_0.ReadData
            OpServerCallDcm_MainFunctionWorker_ReadData_DataServices_DID_F1CA_GMSoftwareModuleIdentifier_10_GMSoftwareModuleIdentif_b8c2bf35: operation=DataServices_DID_F1CA_GMSoftwareModuleIdentifier_10_GMSoftwareModuleIdentifier_10_0_0.ReadData
            OpServerCallDcm_MainFunctionWorker_ReadData_DataServices_DID_F1C5_GMSoftwareModuleIdentifier_05_GMSoftwareModuleIdentif_f6893dc6: operation=DataServices_DID_F1C5_GMSoftwareModuleIdentifier_05_GMSoftwareModuleIdentifier_05_0_0.ReadData
            OpServerCallDcm_MainFunctionWorker_ReadData_DataServices_DID_F1B0_ECUDiagnosticAddress_ECUDiagnosticAddress_0_0: operation=DataServices_DID_F1B0_ECUDiagnosticAddress_ECUDiagnosticAddress_0_0.ReadData
            OpServerCallDcm_MainFunctionWorker_ReadData_DataServices_DID_F11D_GMSoftwareModuleIdentifierAlphaCode_25_GMSoftwareModu_ae1fa446: operation=DataServices_DID_F11D_GMSoftwareModuleIdentifierAlphaCode_25_GMSoftwareModuleIdentifierAlphaCode_25_0_0.ReadData
            OpServerCallDcm_MainFunctionWorker_ReadData_DataServices_DID_F081_ECUKeyConfigurationData_ECUKeyConfigurationData_0_0: operation=DataServices_DID_F081_ECUKeyConfigurationData_ECUKeyConfigurationData_0_0.ReadData
            OpServerCallDcm_MainFunctionWorker_ReadData_DataServices_DID_F1D7_GMSoftwareModuleIdentifierAlphaCode_07_GMSoftwareModu_89849066: operation=DataServices_DID_F1D7_GMSoftwareModuleIdentifierAlphaCode_07_GMSoftwareModuleIdentifierAlphaCode_07_0_0.ReadData
            OpServerCallDcm_MainFunctionWorker_ReadData_DataServices_DID_F09A_DiagnosticDataIdentifier_DiagSystemCode_0_0: operation=DataServices_DID_F09A_DiagnosticDataIdentifier_DiagSystemCode_0_0.ReadData
            OpServerCallDcm_MainFunctionWorker_WriteData_DataServices_DID_F09A_DiagnosticDataIdentifier_DiagSystemCode_0_0: operation=DataServices_DID_F09A_DiagnosticDataIdentifier_DiagSystemCode_0_0.WriteData
            OpServerCallDcm_MainFunctionWorker_ReadData_DataServices_DID_F09A_DiagnosticDataIdentifier_DiagDiagnosticDataStreamVers_cee1145d: operation=DataServices_DID_F09A_DiagnosticDataIdentifier_DiagDiagnosticDataStreamVersionNumber_1_0.ReadData
            OpServerCallDcm_MainFunctionWorker_WriteData_DataServices_DID_F09A_DiagnosticDataIdentifier_DiagDiagnosticDataStreamVer_9e84ed7c: operation=DataServices_DID_F09A_DiagnosticDataIdentifier_DiagDiagnosticDataStreamVersionNumber_1_0.WriteData
            OpServerCallDcm_MainFunctionWorker_ReadData_DataServices_DID_F11E_GMSoftwareModuleIdentifier_26_GMSoftwareModuleIdentif_e78f79d0: operation=DataServices_DID_F11E_GMSoftwareModuleIdentifier_26_GMSoftwareModuleIdentifier_26_0_0.ReadData
            OpServerCallDcm_MainFunctionWorker_ReadData_DataServices_DID_F1C8_GMSoftwareModuleIdentifier_08_GMSoftwareModuleIdentif_b1fc8d13: operation=DataServices_DID_F1C8_GMSoftwareModuleIdentifier_08_GMSoftwareModuleIdentifier_08_0_0.ReadData
            OpServerCallDcm_MainFunctionWorker_ReadData_DataServices_DID_F118_GMSoftwareModuleIdentifier_23_GMSoftwareModuleIdentif_ab762c43: operation=DataServices_DID_F118_GMSoftwareModuleIdentifier_23_GMSoftwareModuleIdentifier_23_0_0.ReadData
            OpServerCallDcm_MainFunctionWorker_ReadData_DataServices_DID_F1C9_GMSoftwareModuleIdentifier_09_GMSoftwareModuleIdentif_c3e8e18d: operation=DataServices_DID_F1C9_GMSoftwareModuleIdentifier_09_GMSoftwareModuleIdentifier_09_0_0.ReadData
            OpServerCallDcm_MainFunctionWorker_ReadData_DataServices_DID_F125_GMSoftwareModuleIdentifierAlphaCode_29_GMSoftwareModu_4d87b1d0: operation=DataServices_DID_F125_GMSoftwareModuleIdentifierAlphaCode_29_GMSoftwareModuleIdentifierAlphaCode_29_0_0.ReadData
            OpServerCallDcm_MainFunctionWorker_ReadData_DataServices_DID_F0F3_ECUID_ECUID_0_0: operation=DataServices_DID_F0F3_ECUID_ECUID_0_0.ReadData
            OpServerCallDcm_MainFunctionWorker_ReadData_DataServices_DID_F115_GMSoftwareModuleIdentifierAlphaCode_21_GMSoftwareModu_19c3de11: operation=DataServices_DID_F115_GMSoftwareModuleIdentifierAlphaCode_21_GMSoftwareModuleIdentifierAlphaCode_21_0_0.ReadData
            OpServerCallDcm_MainFunctionWorker_ReadData_DataServices_DID_F123_GMSoftwareModuleIdentifierAlphaCode_28_GMSoftwareModu_4fcf5a06: operation=DataServices_DID_F123_GMSoftwareModuleIdentifierAlphaCode_28_GMSoftwareModuleIdentifierAlphaCode_28_0_0.ReadData
            OpServerCallDcm_MainFunctionWorker_ReadData_DataServices_DID_F1D2_GMSoftwareModuleIdentifierAlphaCode_02_GMSoftwareModu_dc6c41fa: operation=DataServices_DID_F1D2_GMSoftwareModuleIdentifierAlphaCode_02_GMSoftwareModuleIdentifierAlphaCode_02_0_0.ReadData
            OpServerCallDcm_MainFunctionWorker_ReadData_DataServices_DID_F1C4_GMSoftwareModuleIdentifier_04_GMSoftwareModuleIdentif_849d5158: operation=DataServices_DID_F1C4_GMSoftwareModuleIdentifier_04_GMSoftwareModuleIdentifier_04_0_0.ReadData
            OpServerCallDcm_MainFunctionWorker_ReadData_DataServices_DID_F1C2_GMSoftwareModuleIdentifier_02_GMSoftwareModuleIdentif_73953c5d: operation=DataServices_DID_F1C2_GMSoftwareModuleIdentifier_02_GMSoftwareModuleIdentifier_02_0_0.ReadData
            OpServerCallDcm_MainFunctionWorker_ReadData_DataServices_DID_F083_MessageAuthenticationCalibrationFilePartNumber_Messag_614738d4: operation=DataServices_DID_F083_MessageAuthenticationCalibrationFilePartNumber_MessageAuthenticationCalibrationFilePartNumber_0_0.ReadData
            OpServerCallDcm_MainFunctionWorker_ReadData_DataServices_DID_F110_GMSoftwareModuleIdentifier_19_GMSoftwareModuleIdentif_51ce37d0: operation=DataServices_DID_F110_GMSoftwareModuleIdentifier_19_GMSoftwareModuleIdentifier_19_0_0.ReadData
            OpServerCallDcm_MainFunctionWorker_ReadData_DataServices_DID_F124_GMSoftwareModuleIdentifier_29_GMSoftwareModuleIdentif_07ba88fa: operation=DataServices_DID_F124_GMSoftwareModuleIdentifier_29_GMSoftwareModuleIdentifier_29_0_0.ReadData
            OpServerCallDcm_MainFunctionWorker_ReadData_DataServices_DID_F119_GMSoftwareModuleIdentifierAlphaCode_23_GMSoftwareModu_1d5209bd: operation=DataServices_DID_F119_GMSoftwareModuleIdentifierAlphaCode_23_GMSoftwareModuleIdentifierAlphaCode_23_0_0.ReadData
            OpServerCallDcm_MainFunctionWorker_ReadData_DataServices_DID_F1D8_GMSoftwareModuleIdentifierAlphaCode_08_GMSoftwareModu_77bde2c2: operation=DataServices_DID_F1D8_GMSoftwareModuleIdentifierAlphaCode_08_GMSoftwareModuleIdentifierAlphaCode_08_0_0.ReadData
            OpServerCallDcm_MainFunctionWorker_ReadData_DataServices_DID_F129_TotalVehicleOperationTime_DataRecord: operation=DataServices_DID_F129_TotalVehicleOperationTime_DataRecord.ReadData
            OpServerCallDcm_MainFunctionWorker_WriteData_DataServices_DID_F129_TotalVehicleOperationTime_DataRecord: operation=DataServices_DID_F129_TotalVehicleOperationTime_DataRecord.WriteData
            OpServerCallDcm_MainFunctionWorker_ReadData_DataServices_DID_F1D9_GMSoftwareModuleIdentifierAlphaCode_09_GMSoftwareModu_668a27ee: operation=DataServices_DID_F1D9_GMSoftwareModuleIdentifierAlphaCode_09_GMSoftwareModuleIdentifierAlphaCode_09_0_0.ReadData
            OpServerCallDcm_MainFunctionWorker_ReadData_DataServices_DID_F126_GMSoftwareModuleIdentifier_30_GMSoftwareModuleIdentif_8bf8f8fb: operation=DataServices_DID_F126_GMSoftwareModuleIdentifier_30_GMSoftwareModuleIdentifier_30_0_0.ReadData
            OpServerCallDcm_MainFunctionWorker_ReadData_DataServices_DID_F190_VehicleIdentificationNumber_VehicleIdentificationNumber_0_0: operation=DataServices_DID_F190_VehicleIdentificationNumber_VehicleIdentificationNumber_0_0.ReadData
            OpServerCallDcm_MainFunctionWorker_WriteData_DataServices_DID_F190_VehicleIdentificationNumber_VehicleIdentificationNumber_0_0: operation=DataServices_DID_F190_VehicleIdentificationNumber_VehicleIdentificationNumber_0_0.WriteData
            OpServerCallDcm_MainFunctionWorker_ReadData_DataServices_DID_F1C7_GMSoftwareModuleIdentifier_07_GMSoftwareModuleIdentif_12a1e4fa: operation=DataServices_DID_F1C7_GMSoftwareModuleIdentifier_07_GMSoftwareModuleIdentifier_07_0_0.ReadData
            OpServerCallDcm_MainFunctionWorker_ReadData_DataServices_DID_F0B3_DataUniversalNumberingSystemIdentification_DiagDataUn_bf39fd8d: operation=DataServices_DID_F0B3_DataUniversalNumberingSystemIdentification_DiagDataUniversalNumberingSystemIdentification_0_0.ReadData
            OpServerCallDcm_MainFunctionWorker_ReadData_DataServices_DID_F11F_GMSoftwareModuleIdentifierAlphaCode_26_GMSoftwareModu_9b383fcc: operation=DataServices_DID_F11F_GMSoftwareModuleIdentifierAlphaCode_26_GMSoftwareModuleIdentifierAlphaCode_26_0_0.ReadData
            OpServerCallDcm_MainFunctionWorker_ReadData_DataServices_DID_F10B_GMSoftwareModuleIdentifierAlphaCode_16_GMSoftwareModu_619bc0c0: operation=DataServices_DID_F10B_GMSoftwareModuleIdentifierAlphaCode_16_GMSoftwareModuleIdentifierAlphaCode_16_0_0.ReadData
            OpServerCallDcm_MainFunctionWorker_ReadData_DataServices_DID_F1D0_GMBootSoftwarePartNumberAlphaCode_GMBootSoftwarePartN_934743ef: operation=DataServices_DID_F1D0_GMBootSoftwarePartNumberAlphaCode_GMBootSoftwarePartNumberAlphaCode_0_0.ReadData
            OpServerCallDcm_MainFunctionWorker_ReadData_DataServices_DID_F1D5_GMSoftwareModuleIdentifierAlphaCode_05_GMSoftwareModu_abeb1a3e: operation=DataServices_DID_F1D5_GMSoftwareModuleIdentifierAlphaCode_05_GMSoftwareModuleIdentifierAlphaCode_05_0_0.ReadData
            OpServerCallDcm_MainFunctionWorker_ReadData_DataServices_DID_F111_GMSoftwareModuleIdentifierAlphaCode_19_GMSoftwareModu_03230f42: operation=DataServices_DID_F111_GMSoftwareModuleIdentifierAlphaCode_19_GMSoftwareModuleIdentifierAlphaCode_19_0_0.ReadData
            OpServerCallDcm_MainFunctionWorker_ReadData_DataServices_DID_F180_BootSoftwareIdentificationDataIdentifier_BootSoftware_d45af91c: operation=DataServices_DID_F180_BootSoftwareIdentificationDataIdentifier_BootSoftwareIdentificationDataIdentifier_0_0.ReadData
            OpServerCallDcm_MainFunctionWorker_ReadDataLength_DataServices_DID_F180_BootSoftwareIdentificationDataIdentifier_BootSo_b28edf15: operation=DataServices_DID_F180_BootSoftwareIdentificationDataIdentifier_BootSoftwareIdentificationDataIdentifier_0_0.ReadDataLength
            OpServerCallDcm_MainFunctionWorker_ReadData_DataServices_DID_F127_GMSoftwareModuleIdentifierAlphaCode_30_GMSoftwareModu_84ba7c87: operation=DataServices_DID_F127_GMSoftwareModuleIdentifierAlphaCode_30_GMSoftwareModuleIdentifierAlphaCode_30_0_0.ReadData
            OpServerCallDcm_MainFunctionWorker_ReadData_DataServices_DID_F198_RepairShopCodeOrTesterSerialNumber_DiagRepairShopCode_c433ed27: operation=DataServices_DID_F198_RepairShopCodeOrTesterSerialNumber_DiagRepairShopCodeOrTesterSerialNumber_0_0.ReadData
            OpServerCallDcm_MainFunctionWorker_WriteData_DataServices_DID_F198_RepairShopCodeOrTesterSerialNumber_DiagRepairShopCod_2caa2d4e: operation=DataServices_DID_F198_RepairShopCodeOrTesterSerialNumber_DiagRepairShopCodeOrTesterSerialNumber_0_0.WriteData
            OpServerCallDcm_MainFunctionWorker_ReadData_DataServices_DID_F121_GMSoftwareModuleIdentifierAlphaCode_27_GMSoftwareModu_9d880854: operation=DataServices_DID_F121_GMSoftwareModuleIdentifierAlphaCode_27_GMSoftwareModuleIdentifierAlphaCode_27_0_0.ReadData
            OpServerCallDcm_MainFunctionWorker_ReadData_DataServices_DID_F09C_GMXmlDataFilePartNumber_DiagGMXmlDataFilePartNumber_0_0: operation=DataServices_DID_F09C_GMXmlDataFilePartNumber_DiagGMXmlDataFilePartNumber_0_0.ReadData
            OpServerCallDcm_MainFunctionWorker_WriteData_DataServices_DID_F09C_GMXmlDataFilePartNumber_DiagGMXmlDataFilePartNumber_0_0: operation=DataServices_DID_F09C_GMXmlDataFilePartNumber_DiagGMXmlDataFilePartNumber_0_0.WriteData
            OpServerCallDcm_MainFunctionWorker_ReadData_DataServices_DID_F0B4_ManufacturingTraceabilityCharacters_DiagYear_2_0: operation=DataServices_DID_F0B4_ManufacturingTraceabilityCharacters_DiagYear_2_0.ReadData
            OpServerCallDcm_MainFunctionWorker_ReadData_DataServices_DID_F0B4_ManufacturingTraceabilityCharacters_DiagTraceabilityNumber_7_0: operation=DataServices_DID_F0B4_ManufacturingTraceabilityCharacters_DiagTraceabilityNumber_7_0.ReadData
            OpServerCallDcm_MainFunctionWorker_ReadData_DataServices_DID_F0B4_ManufacturingTraceabilityCharacters_DiagShift_1_0: operation=DataServices_DID_F0B4_ManufacturingTraceabilityCharacters_DiagShift_1_0.ReadData
            OpServerCallDcm_MainFunctionWorker_ReadData_DataServices_DID_F0B4_ManufacturingTraceabilityCharacters_DiagLine_0_0: operation=DataServices_DID_F0B4_ManufacturingTraceabilityCharacters_DiagLine_0_0.ReadData
            OpServerCallDcm_MainFunctionWorker_ReadData_DataServices_DID_F0B4_ManufacturingTraceabilityCharacters_DiagDayOfTheYear_4_0: operation=DataServices_DID_F0B4_ManufacturingTraceabilityCharacters_DiagDayOfTheYear_4_0.ReadData
            OpServerCallDcm_MainFunctionWorker_ReadData_DataServices_DID_F0BE_MasterNetworkConfigurationListLIN_DiagMasterNetworkCo_4a73c377: operation=DataServices_DID_F0BE_MasterNetworkConfigurationListLIN_DiagMasterNetworkConfigurationListLIN_0_0.ReadData
            OpServerCallDcm_MainFunctionWorker_ReadDataLength_DataServices_DID_F0BE_MasterNetworkConfigurationListLIN_DiagMasterNet_ae30aa98: operation=DataServices_DID_F0BE_MasterNetworkConfigurationListLIN_DiagMasterNetworkConfigurationListLIN_0_0.ReadDataLength
            OpServerCallDcm_MainFunctionWorker_WriteData_DataServices_DID_F0BE_MasterNetworkConfigurationListLIN_DiagMasterNetworkC_eadd3143: operation=DataServices_DID_F0BE_MasterNetworkConfigurationListLIN_DiagMasterNetworkConfigurationListLIN_0_0.WriteData
            OpServerCallDcm_MainFunctionWorker_ReadData_DataServices_DID_F1DD_GMSoftwareModuleIdentifierDataIdentifiers_GMSoftwareM_d24c1015: operation=DataServices_DID_F1DD_GMSoftwareModuleIdentifierDataIdentifiers_GMSoftwareModuleIdentifierDataIdentifiers_0_0.ReadData
            OpServerCallDcm_MainFunctionWorker_DcmClearDTC_Dcm: operation=Dcm.DcmClearDTC
            OpServerCallDcm_MainFunctionWorker_DcmEnableDTCSetting_Dcm: operation=Dcm.DcmEnableDTCSetting
            OpServerCallDcm_MainFunctionWorker_DcmGetFreezeFrameDataByDTC_Dcm: operation=Dcm.DcmGetFreezeFrameDataByDTC
            OpServerCallDcm_MainFunctionWorker_DcmGetExtendedDataRecordByDTC_Dcm: operation=Dcm.DcmGetExtendedDataRecordByDTC
        GetActiveProtocol: can-be-invoked-concurrently=true, symbol=Dcm_GetActiveProtocol
        GetSesCtrlType: can-be-invoked-concurrently=true, symbol=Dcm_GetSesCtrlType
        ResetToDefaultSession: can-be-invoked-concurrently=true, symbol=Dcm_ResetToDefaultSession
        GetSecurityLevel: can-be-invoked-concurrently=true, symbol=Dcm_GetSecurityLevel
  swc implementation DcmImplementation: programming-language=C, behavior=DcmInternalBehavior
